VERSION ""

NS_ :

BS_:

BU_: ARM APIM_CDC APIM_CISM APIM ESPM DSP APIM_CIM FCIMB RACM_RCIM HUD_ADV WCM TRM_ITRM ACM GWM _delete IPC GENERIC TSTR

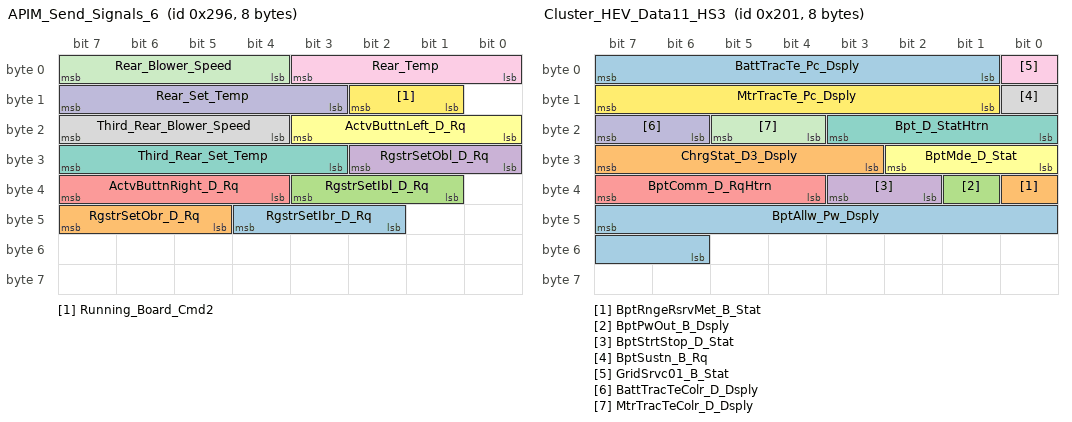
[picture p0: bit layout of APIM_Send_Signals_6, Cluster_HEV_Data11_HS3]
BO_ 662 APIM_Send_Signals_6: 8 APIM_CIM
 SG_ RgstrSetIbr_D_Rq : 44|3@0+ (1,0) [0|7] "SED"  GWM
 SG_ RgstrSetObr_D_Rq : 47|3@0+ (1,0) [0|7] "SED"  GWM
 SG_ RgstrSetIbl_D_Rq : 35|3@0+ (1,0) [0|7] "SED"  GWM
 SG_ RgstrSetObl_D_Rq : 26|3@0+ (1,0) [0|7] "SED"  GWM
 SG_ ActvButtnRight_D_Rq : 39|4@0+ (1,0) [0|15] "SED"  GWM
 SG_ ActvButtnLeft_D_Rq : 19|4@0+ (1,0) [0|15] "SED"  GWM
 SG_ Third_Rear_Set_Temp : 31|5@0+ (1,0) [0|31] "SED"  GWM
 SG_ Third_Rear_Blower_Speed : 23|4@0+ (1,0) [0|15] "SED"  GWM
 SG_ Rear_Temp : 3|4@0+ (1,0) [0|15] "SED"  GWM
 SG_ Rear_Set_Temp : 15|5@0+ (1,0) [0|31] "SED"  GWM
 SG_ Rear_Blower_Speed : 7|4@0+ (1,0) [0|15] "SED"  GWM
 SG_ Running_Board_Cmd2 : 10|2@0+ (1,0) [0|3] "SED"  GWM

BO_ 515 PowertrainData_12_HS3: 8 GWM
 SG_ FuelLvlPss_Pc_DsplyEng : 9|10@0+ (0.108696,-5.217408) [-5.217408|105.9786] "percent"  APIM,APIM_CDC,APIM_CIM,APIM_CISM,IPC
 SG_ FuelLvlAct_Pc_DsplyEng : 5|10@0+ (0.108696,-5.217408) [-5.217408|105.9786] "percent"  APIM,APIM_CDC,APIM_CIM,APIM_CISM,IPC
 SG_ PtIgnSwtch_D_Stat : 7|2@0+ (1,0) [0|3] "SED" Vector__XXX

BO_ 513 Cluster_HEV_Data11_HS3: 8 GWM
 SG_ BptAllw_Pw_Dsply : 47|10@0+ (0.1,0) [0|102.1] "kilowatt"  APIM_CDC,APIM,APIM_CIM,APIM_CISM
 SG_ BptRngeRsrvMet_B_Stat : 32|1@0+ (1,0) [0|1] "SED"  APIM_CDC,APIM,APIM_CIM,APIM_CISM
 SG_ BptPwOut_B_Dsply : 33|1@0+ (1,0) [0|1] "SED"  APIM_CDC,APIM,APIM_CIM,APIM_CISM
 SG_ BptStrtStop_D_Stat : 35|2@0+ (1,0) [0|3] "SED"  APIM_CDC,APIM,APIM_CIM,APIM_CISM
 SG_ BptComm_D_RqHtrn : 39|4@0+ (1,0) [0|15] "SED"  APIM_CDC,APIM,APIM_CIM,APIM_CISM
 SG_ BptMde_D_Stat : 26|3@0+ (1,0) [0|7] "SED"  APIM_CDC,APIM,APIM_CIM,APIM_CISM
 SG_ Bpt_D_StatHtrn : 19|4@0+ (1,0) [0|15] "SED"  APIM,APIM_CIM,APIM_CISM
 SG_ BptSustn_B_Rq : 8|1@0+ (1,0) [0|1] "SED"  APIM,APIM_CIM,APIM_CISM
 SG_ GridSrvc01_B_Stat : 0|1@0+ (1,0) [0|1] "SED"  APIM_CDC,APIM,APIM_CIM,APIM_CISM
 SG_ BattTracTeColr_D_Dsply : 23|2@0+ (1,0) [0|3] "SED"  APIM_CDC,APIM_CIM,IPC
 SG_ MtrTracTeColr_D_Dsply : 21|2@0+ (1,0) [0|3] "SED"  APIM_CDC,APIM_CIM,IPC
 SG_ MtrTracTe_Pc_Dsply : 15|7@0+ (1,0) [0|127] "percent"  APIM_CDC,APIM_CIM,IPC
 SG_ BattTracTe_Pc_Dsply : 7|7@0+ (1,0) [0|127] "percent"  APIM_CDC,APIM_CIM,IPC
 SG_ ChrgStat_D3_Dsply : 31|5@0+ (1,0) [0|31] "SED"  APIM_CDC,APIM,APIM_CIM,IPC,APIM_CISM

BO_ 148 Yaw_Data_HS3: 8 GWM
 SG_ VehYawWActl_D_Qf : 53|2@0+ (1,0) [0|3] "SED" Vector__XXX
 SG_ VehRolWActl_D_Qf : 55|2@0+ (1,0) [0|3] "SED" Vector__XXX
 SG_ VehRollYawW_No_Cs : 39|8@0+ (1,0) [0|255] "unitless" Vector__XXX
 SG_ VehRollYaw_No_Cnt : 47|8@0+ (1,0) [0|255] "unitless" Vector__XXX
 SG_ VehYaw_W_Actl : 23|16@0+ (0.0002,-6.5) [-6.5|6.6066] "rad/s"  APIM_CDC,APIM,APIM_CISM,ACM,APIM_CIM
 SG_ VehRol_W_Actl : 7|16@0+ (0.0002,-6.5) [-6.5|6.6066] "rad/s" Vector__XXX

BO_ 1042 TrailerBrakeData_HS3: 8 GWM
 SG_ VehRol_An_Dsply : 31|7@0+ (1,-64) [-64|61] "degrees"  APIM_CDC,HUD_ADV,APIM,APIM_CIM,APIM_CISM,IPC
 SG_ RearDiffLck_Tq_RqMn : 39|12@0+ (4,0) [0|16376] "Nm" Vector__XXX
 SG_ VehPtch_An_Dsply : 23|7@0+ (1,-64) [-64|61] "degrees"  APIM_CDC,HUD_ADV,APIM,APIM_CIM,APIM_CISM,IPC
 SG_ TrlrBrk_Pc_Rq : 14|7@0+ (1,0) [0|127] "percent"  TRM_ITRM,IPC

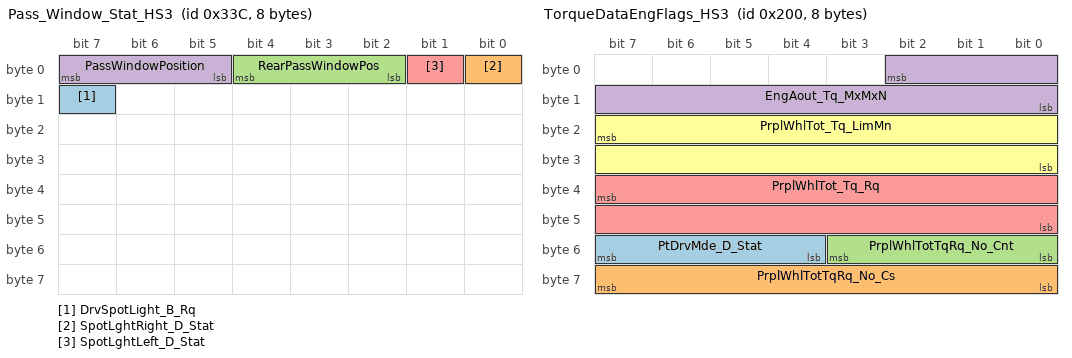
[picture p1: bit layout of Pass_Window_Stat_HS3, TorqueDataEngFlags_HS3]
BO_ 828 Pass_Window_Stat_HS3: 8 GWM
 SG_ DrvSpotLight_B_Rq : 15|1@0+ (1,0) [0|1] "SED" Vector__XXX
 SG_ SpotLghtRight_D_Stat : 0|1@0+ (1,0) [0|1] "SED"  APIM_CDC,APIM,APIM_CISM,APIM_CIM
 SG_ RearPassWindowPos : 4|3@0+ (1,0) [0|7] "SED"  APIM_CDC,APIM,APIM_CISM,ACM,APIM_CIM,WCM
 SG_ PassWindowPosition : 7|3@0+ (1,0) [0|7] "SED"  APIM_CDC,APIM,APIM_CISM,ACM,APIM_CIM,WCM
 SG_ SpotLghtLeft_D_Stat : 1|1@0+ (1,0) [0|1] "SED"  APIM_CDC,APIM,APIM_CISM,APIM_CIM

BO_ 330 TransData_3_HS3: 8 GWM
 SG_ TrnFaltOpenClu_B_Stat : 5|1@0+ (1,0) [0|1] "SED" Vector__XXX
 SG_ TrnAout_W_ActlUnfilt : 22|15@0+ (0.1,0) [0|3276.5] "rad/s"  APIM_CISM,ACM,APIM_CIM

BO_ 512 TorqueDataEngFlags_HS3: 8 GWM
 SG_ PtDrvMde_D_Stat : 55|4@0+ (1,0) [0|15] "SED"  APIM_CDC,APIM_CISM,ACM,APIM_CIM,IPC
 SG_ PrplWhlTotTqRq_No_Cs : 63|8@0+ (1,0) [0|255] "unitless" Vector__XXX
 SG_ PrplWhlTotTqRq_No_Cnt : 51|4@0+ (1,0) [0|15] "unitless" Vector__XXX
 SG_ EngAout_Tq_MxMxN : 2|11@0+ (1,-500) [-500|1547] "Nm" Vector__XXX
 SG_ PrplWhlTot_Tq_Rq : 39|16@0+ (4,-131072) [-131072|131068] "Nm" Vector__XXX
 SG_ PrplWhlTot_Tq_LimMn : 23|16@0+ (4,-131072) [-131072|131068] "Nm" Vector__XXX

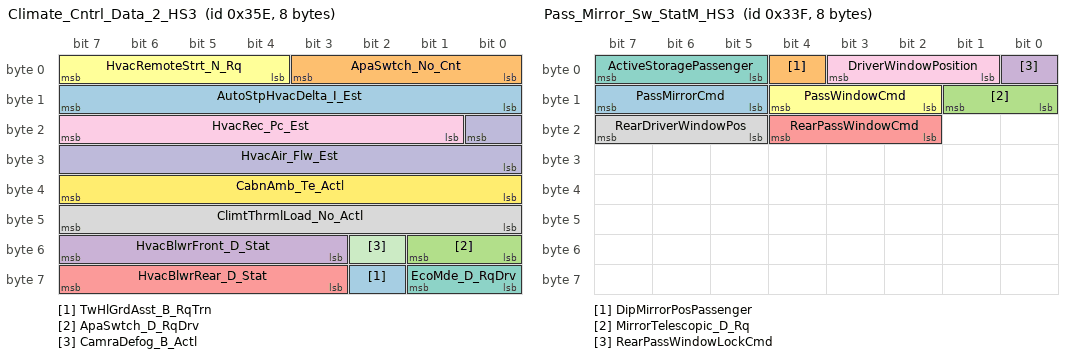
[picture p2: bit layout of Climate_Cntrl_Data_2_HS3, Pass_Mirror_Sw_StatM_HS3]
BO_ 862 Climate_Cntrl_Data_2_HS3: 8 GWM
 SG_ TwHlGrdAsst_B_RqTrn : 58|1@0+ (1,0) [0|1] "SED" Vector__XXX
 SG_ ApaSwtch_No_Cnt : 3|4@0+ (1,0) [0|15] "unitless" Vector__XXX
 SG_ ApaSwtch_D_RqDrv : 49|2@0+ (1,0) [0|3] "SED" Vector__XXX
 SG_ HvacBlwrFront_D_Stat : 55|5@0+ (1,0) [0|31] "SED"  APIM,APIM_CISM,APIM_CIM,WCM
 SG_ HvacBlwrRear_D_Stat : 63|5@0+ (1,0) [0|31] "SED"  APIM,APIM_CISM,APIM_CIM,WCM
 SG_ HvacRemoteStrt_N_Rq : 7|4@0+ (100,450) [450|1950] "RPM" Vector__XXX
 SG_ EcoMde_D_RqDrv : 57|2@0+ (1,0) [0|3] "SED" Vector__XXX
 SG_ ClimtThrmlLoad_No_Actl : 47|8@0+ (1,0) [0|254] "unitless" Vector__XXX
 SG_ HvacRec_Pc_Est : 23|7@0+ (1,0) [0|127] "percent" Vector__XXX
 SG_ HvacAir_Flw_Est : 16|9@0+ (0.5,0) [0|255.5] "liter/second" Vector__XXX
 SG_ CamraDefog_B_Actl : 50|1@0+ (1,0) [0|1] "SED" Vector__XXX
 SG_ CabnAmb_Te_Actl : 39|8@0+ (0.5,-57) [-57|70] "degC"  APIM_CDC,APIM,APIM_CISM,GWM,ACM,APIM_CIM,WCM
 SG_ AutoStpHvacDelta_I_Est : 15|8@0+ (1,-192) [-192|62] "ampere" Vector__XXX

BO_ 831 Pass_Mirror_Sw_StatM_HS3: 8 GWM
 SG_ PassMirrorCmd : 15|3@0+ (1,0) [0|7] "SED" Vector__XXX
 SG_ DipMirrorPosPassenger : 4|1@0+ (1,0) [0|1] "SED" Vector__XXX
 SG_ MirrorTelescopic_D_Rq : 9|2@0+ (1,0) [0|3] "SED" Vector__XXX
 SG_ RearPassWindowLockCmd : 0|1@0+ (1,0) [0|1] "SED" Vector__XXX
 SG_ RearPassWindowCmd : 20|3@0+ (1,0) [0|7] "SED" Vector__XXX
 SG_ PassWindowCmd : 12|3@0+ (1,0) [0|7] "SED" Vector__XXX
 SG_ ActiveStoragePassenger : 7|3@0+ (1,0) [0|7] "SED" Vector__XXX
 SG_ RearDriverWindowPos : 23|3@0+ (1,0) [0|7] "SED"  APIM_CDC,APIM,APIM_CISM,ACM,APIM_CIM,WCM
 SG_ DriverWindowPosition : 3|3@0+ (1,0) [0|7] "SED"  APIM_CDC,APIM,APIM_CISM,ACM,APIM_CIM,WCM

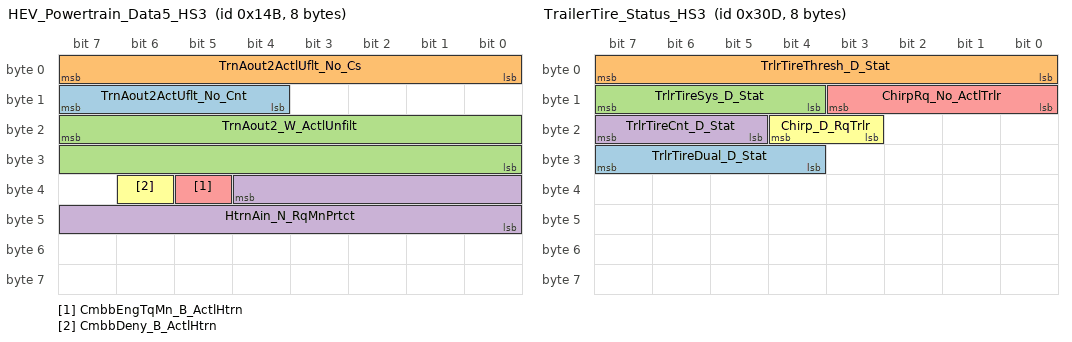
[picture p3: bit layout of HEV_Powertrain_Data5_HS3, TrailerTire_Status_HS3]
BO_ 331 HEV_Powertrain_Data5_HS3: 8 GWM
 SG_ TrnAout2ActUflt_No_Cnt : 15|4@0+ (1,0) [0|15] "unitless" Vector__XXX
 SG_ TrnAout2ActlUflt_No_Cs : 7|8@0+ (1,0) [0|255] "unitless" Vector__XXX
 SG_ TrnAout2_W_ActlUnfilt : 23|16@0+ (0.1,-3276.5) [-3276.5|3276.8] "rad/s"  APIM_CDC,APIM_CISM,ACM,APIM_CIM
 SG_ HtrnAin_N_RqMnPrtct : 36|13@0+ (2,0) [0|16382] "RPM" Vector__XXX
 SG_ CmbbEngTqMn_B_ActlHtrn : 37|1@0+ (1,0) [0|1] "SED" Vector__XXX
 SG_ CmbbDeny_B_ActlHtrn : 38|1@0+ (1,0) [0|1] "SED" Vector__XXX

BO_ 965 FrontTrunk_Data_HS3: 8 GWM
 SG_ TrnkFrontPrim_B_Falt : 18|1@0+ (1,0) [0|1] "SED"  APIM_CDC,APIM_CIM,IPC
 SG_ TrnkFrontEmgcy_D_Stat : 20|2@0+ (1,0) [0|0] "SED"  APIM_CDC,APIM_CIM,IPC
 SG_ PtWakeupActv4_B_Rq : 21|1@0+ (1,0) [0|1] "SED" Vector__XXX
 SG_ TrunkFrontOpen_D_Stat : 23|2@0+ (1,0) [0|3] "SED"  APIM_CDC,APIM,APIM_CISM,APIM_CIM
 SG_ TrunkFrontRolCd_No_Locl : 7|16@0+ (1,0) [0|65535] "unitless" Vector__XXX

BO_ 1242 PowertrainCstmData_HS3: 8 GWM
 SG_ EngExhMdeQuietCstm_D_Rq : 7|3@0+ (1,0) [0|7] "SED"  IPC
 SG_ StopStrtCstm_D_Rq : 15|2@0+ (1,0) [0|3] "SED"  IPC
 SG_ SelDrvMdeCstmPt_D_Rq : 4|5@0+ (1,0) [0|31] "SED" Vector__XXX

BO_ 1245 DrivelineCstmFeatures_HS3: 8 GWM
 SG_ RearDiffLckLamp_D_Cstm : 13|2@0+ (1,0) [0|3] "SED"  IPC
 SG_ FrontDiffLckLamp_D_Cstm : 15|2@0+ (1,0) [0|3] "SED"  IPC
 SG_ AwdMdeCstm_D_RqDrv : 7|3@0+ (1,0) [0|7] "SED"  IPC
 SG_ SelDrvMdeAwd2_D_Cstm : 4|5@0+ (1,0) [0|31] "SED" Vector__XXX

BO_ 781 TrailerTire_Status_HS3: 8 GWM
 SG_ TrlrTireDual_D_Stat : 31|4@0+ (1,0) [0|15] "SED"  APIM_CDC,APIM,APIM_CIM,APIM_CISM,IPC
 SG_ TrlrTireThresh_D_Stat : 7|8@0+ (1,0) [0|255] "unitless"  APIM_CDC,APIM,APIM_CISM,APIM_CIM,IPC
 SG_ TrlrTireSys_D_Stat : 15|4@0+ (1,0) [0|15] "SED"  APIM_CDC,APIM,APIM_CISM,APIM_CIM,IPC
 SG_ TrlrTireCnt_D_Stat : 23|3@0+ (1,0) [0|6] "SED"  APIM_CDC,APIM,APIM_CISM,APIM_CIM,IPC
 SG_ ChirpRq_No_ActlTrlr : 11|4@0+ (1,0) [0|15] "unitless"  APIM_CISM,APIM_CIM,IPC
 SG_ Chirp_D_RqTrlr : 20|2@0+ (1,0) [0|3] "SED"  APIM_CISM,APIM_CIM,IPC

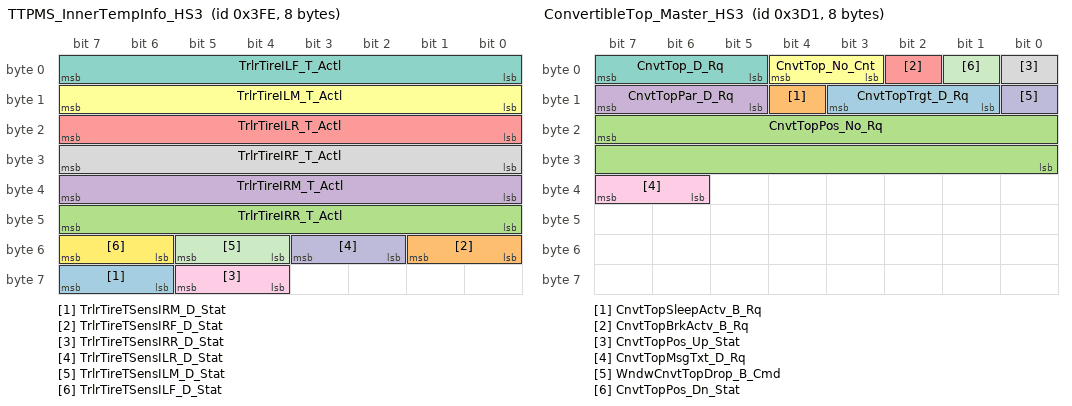
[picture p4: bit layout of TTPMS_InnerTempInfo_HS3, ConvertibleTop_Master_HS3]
BO_ 1022 TTPMS_InnerTempInfo_HS3: 8 GWM
 SG_ TrlrTireTSensIRM_D_Stat : 63|2@0+ (1,0) [0|3] "SED"  APIM_CDC,APIM,APIM_CISM,APIM_CIM,IPC
 SG_ TrlrTireTSensIRF_D_Stat : 49|2@0+ (1,0) [0|3] "SED"  APIM_CDC,APIM,APIM_CISM,APIM_CIM,IPC
 SG_ TrlrTireIRR_T_Actl : 47|8@0+ (1,-60) [-60|193] "degC"  APIM_CDC,APIM,APIM_CISM,APIM_CIM,IPC
 SG_ TrlrTireIRM_T_Actl : 39|8@0+ (1,-60) [-60|193] "degC"  APIM_CDC,APIM,APIM_CISM,APIM_CIM,IPC
 SG_ TrlrTireILR_T_Actl : 23|8@0+ (1,-60) [-60|193] "degC"  APIM_CDC,APIM,APIM_CISM,APIM_CIM,IPC
 SG_ TrlrTireILM_T_Actl : 15|8@0+ (1,-60) [-60|193] "degC"  APIM_CDC,APIM,APIM_CISM,APIM_CIM,IPC
 SG_ TrlrTireILF_T_Actl : 7|8@0+ (1,-60) [-60|193] "degC"  APIM_CDC,APIM,APIM_CISM,APIM_CIM,IPC
 SG_ TrlrTireIRF_T_Actl : 31|8@0+ (1,-60) [-60|193] "degC"  APIM_CDC,APIM,APIM_CISM,APIM_CIM,IPC
 SG_ TrlrTireTSensIRR_D_Stat : 61|2@0+ (1,0) [0|3] "SED"  APIM_CDC,APIM,APIM_CISM,APIM_CIM,IPC
 SG_ TrlrTireTSensILR_D_Stat : 51|2@0+ (1,0) [0|3] "SED"  APIM_CDC,APIM,APIM_CISM,APIM_CIM,IPC
 SG_ TrlrTireTSensILM_D_Stat : 53|2@0+ (1,0) [0|3] "SED"  APIM_CDC,APIM,APIM_CISM,APIM_CIM,IPC
 SG_ TrlrTireTSensILF_D_Stat : 55|2@0+ (1,0) [0|3] "SED"  APIM_CDC,APIM,APIM_CISM,APIM_CIM,IPC

BO_ 903 Av_RDAPM_Data2_HS3: 8 GWM
 SG_ AprSnd_D_Rq : 7|6@0+ (1,0) [0|63] "SED"  APIM_CDC,APIM,APIM_CISM,APIM_CIM

BO_ 901 Av_LDAPM_Data2_HS3: 8 GWM
 SG_ AplSnd_D_Rq : 7|6@0+ (1,0) [0|63] "SED"  APIM_CDC,APIM,APIM_CISM,APIM_CIM

BO_ 1112 Battery_Traction_6_HS3: 8 GWM
 SG_ BattTracIsoDis_B_Stat : 0|1@0+ (1,0) [0|1] "SED" Vector__XXX
 SG_ BattTrac2_E_Max : 47|12@0+ (50,0) [0|204650] "watt*hour"  APIM_CDC,APIM,APIM_CISM,APIM_CIM
 SG_ BattTracHeat_D_Rq : 35|2@0+ (1,0) [0|3] "SED" Vector__XXX
 SG_ BattTracDcFstSustn_B_Rq : 51|1@0+ (1,0) [0|1] "SED" Vector__XXX
 SG_ BattDcCnnct_D_Cmd : 14|3@0+ (1,0) [0|7] "SED" Vector__XXX
 SG_ BattTrac2_E_Avail : 31|12@0+ (50,0) [0|204650] "watt*hour"  APIM_CDC,APIM,APIM_CISM,APIM_CIM
 SG_ BattTracCnnct_D_Cmd : 18|3@0+ (1,0) [0|7] "SED" Vector__XXX
 SG_ BattTracHvilOpen_B_Stat : 8|1@0+ (1,0) [0|1] "SED" Vector__XXX
 SG_ BattTracCoolLvl_D_Rq : 11|3@0+ (1,0) [0|7] "SED" Vector__XXX
 SG_ CoolFanBatt_D_Rq : 23|5@0+ (1,0) [0|31] "unitless" Vector__XXX
 SG_ BattTracTeSustn_B_Rq : 1|1@0+ (1,0) [0|1] "SED" Vector__XXX
 SG_ BattTracTeEvnt_B_Stat : 2|1@0+ (1,0) [0|1] "SED" Vector__XXX
 SG_ BattTracDcdcDis_B_Rq : 7|1@0+ (1,0) [0|1] "SED" Vector__XXX
 SG_ BattChrgTrgtEvnt_B_Stat : 3|1@0+ (1,0) [0|1] "SED" Vector__XXX
 SG_ BattTracDiagClr_B_Rq : 15|1@0+ (1,0) [0|1] "SED" Vector__XXX
 SG_ BattTracChrgSustn_B_Rq : 4|1@0+ (1,0) [0|1] "SED" Vector__XXX
 SG_ HtrnClntPump_D_Stat : 6|2@0+ (1,0) [0|3] "SED" Vector__XXX
 SG_ BattTracDelta_Te_Actl : 63|8@0+ (0.5,-60) [-60|66.5] "degC" Vector__XXX
 SG_ BattTracClntPmp_D_Stat : 33|2@0+ (1,0) [0|3] "SED" Vector__XXX
 SG_ BattTracHazrd_D_Stat : 50|3@0+ (1,0) [0|7] "SED"  APIM_CDC,APIM_CIM,IPC

BO_ 977 ConvertibleTop_Master_HS3: 8 GWM
 SG_ CnvtTopTrgt_D_Rq : 11|3@0+ (1,0) [0|7] "SED" Vector__XXX
 SG_ CnvtTopSleepActv_B_Rq : 12|1@0+ (1,0) [0|1] "SED" Vector__XXX
 SG_ CnvtTopPos_No_Rq : 23|16@0+ (1,0) [0|65535] "unitless" Vector__XXX
 SG_ CnvtTopPar_D_Rq : 15|3@0+ (1,0) [0|7] "SED" Vector__XXX
 SG_ CnvtTopBrkActv_B_Rq : 2|1@0+ (1,0) [0|1] "SED" Vector__XXX
 SG_ CnvtTop_No_Cnt : 4|2@0+ (1,0) [0|3] "unitless" Vector__XXX
 SG_ CnvtTop_D_Rq : 7|3@0+ (1,0) [0|7] "SED" Vector__XXX
 SG_ CnvtTopPos_Up_Stat : 0|1@0+ (1,0) [0|1] "SED"  APIM_CDC,APIM_CISM,APIM_CIM,ACM,DSP
 SG_ CnvtTopMsgTxt_D_Rq : 39|2@0+ (1,0) [0|3] "SED"  APIM_CDC,APIM_CIM,IPC
 SG_ WndwCnvtTopDrop_B_Cmd : 8|1@0+ (1,0) [0|1] "SED" Vector__XXX
 SG_ CnvtTopPos_Dn_Stat : 1|1@0+ (1,0) [0|1] "SED"  APIM_CDC,APIM_CISM,APIM_CIM,ACM

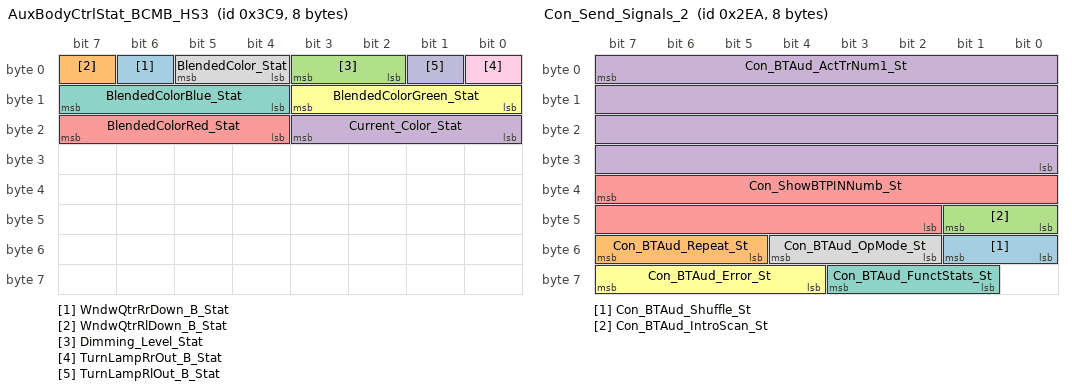
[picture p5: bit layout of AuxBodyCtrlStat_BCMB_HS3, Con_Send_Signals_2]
BO_ 969 AuxBodyCtrlStat_BCMB_HS3: 8 GWM
 SG_ WndwQtrRrDown_B_Stat : 6|1@0+ (1,0) [0|1] "SED" Vector__XXX
 SG_ WndwQtrRlDown_B_Stat : 7|1@0+ (1,0) [0|1] "SED" Vector__XXX
 SG_ Dimming_Level_Stat : 3|2@0+ (1,0) [0|3] "SED"  APIM_CDC,APIM_CIM
 SG_ Current_Color_Stat : 19|4@0+ (1,0) [0|15] "SED"  APIM_CDC,APIM_CIM
 SG_ BlendedColorRed_Stat : 23|4@0+ (1,0) [0|15] "SED"  APIM_CDC,APIM_CIM
 SG_ BlendedColorGreen_Stat : 11|4@0+ (1,0) [0|15] "SED"  APIM_CDC,APIM_CIM
 SG_ BlendedColorBlue_Stat : 15|4@0+ (1,0) [0|15] "SED"  APIM_CDC,APIM_CIM
 SG_ BlendedColor_Stat : 5|2@0+ (1,0) [0|3] "SED"  APIM_CDC,APIM_CIM
 SG_ TurnLampRrOut_B_Stat : 0|1@0+ (1,0) [0|1] "SED" Vector__XXX
 SG_ TurnLampRlOut_B_Stat : 1|1@0+ (1,0) [0|1] "SED" Vector__XXX

BO_ 530 APIM_Request_Signals_6: 8 APIM
 SG_ PiCode_No_Rq : 39|16@0+ (1,0) [0|65535] "unitless"  ACM
 SG_ StationTypeSel_D_Rq : 61|2@0+ (1,0) [0|3] "SED"  ACM
 SG_ DabExtndCntryCode_No_Rq : 55|8@0+ (1,0) [0|255] "unitless"  ACM
 SG_ DabStationCodeId_No_Rq : 23|16@0+ (1,0) [0|65535] "unitless"  ACM
 SG_ DabStationId_No_Rq : 7|16@0+ (1,0) [0|65535] "unitless"  ACM

BO_ 746 Con_Send_Signals_2: 8 ACM
 SG_ Con_BTAud_Shuffle_St : 49|2@0+ (1,0) [0|3] "SED"  IPC
 SG_ Con_BTAud_Repeat_St : 55|3@0+ (1,0) [0|7] "SED"  IPC
 SG_ Con_BTAud_IntroScan_St : 41|2@0+ (1,0) [0|3] "SED"  IPC
 SG_ Con_BTAud_ActTrNum1_St : 7|32@0+ (1,0) [0|4294967295] "unitless"  IPC
 SG_ Con_ShowBTPINNumb_St : 39|14@0+ (1,0) [0|16383] "unitless"  IPC
 SG_ Con_BTAud_Error_St : 63|4@0+ (1,0) [0|15] "SED"  IPC
 SG_ Con_BTAud_FunctStats_St : 59|3@0+ (1,0) [0|7] "SED"  IPC
 SG_ Con_BTAud_OpMode_St : 52|3@0+ (1,0) [0|7] "SED"  IPC

BO_ 479 DISP_Request_Sig: 8 APIM_CIM
 SG_ DISP_SetVolume_Rq : 5|6@0+ (1,-30) [-30|33] "steps"  DSP,ACM,GWM
 SG_ DISP_SetVol_Source_Rq : 19|4@0+ (1,0) [0|15] "SED"  IPC,DSP,ACM,GWM
 SG_ DISP_SetVol_Level_Rq : 13|6@0+ (1,0) [0|63] "unitless"  DSP,GWM,ACM
 SG_ DISP_Setshaker_Rq : 21|2@0+ (1,0) [0|3] "SED"  DSP,GWM,ACM

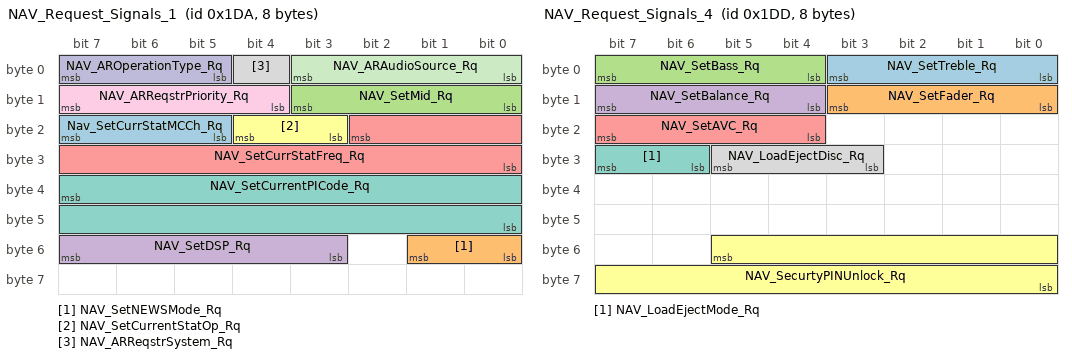
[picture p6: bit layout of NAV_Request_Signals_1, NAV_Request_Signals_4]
BO_ 474 NAV_Request_Signals_1: 8 APIM
 SG_ Nav_SetCurrStatMCCh_Rq : 23|3@0+ (1,0) [0|7] "SED"  ACM
 SG_ NAV_SetNEWSMode_Rq : 49|2@0+ (1,0) [0|3] "SED"  ACM
 SG_ NAV_SetMid_Rq : 11|4@0+ (1,-7) [-7|8] "SED"  DSP,ACM
 SG_ NAV_SetDSP_Rq : 55|5@0+ (1,0) [0|31] "SED"  DSP,ACM
 SG_ NAV_SetCurrStatFreq_Rq : 18|11@0+ (1,0) [0|1557] "unitless"  ACM
 SG_ NAV_SetCurrentStatOp_Rq : 20|2@0+ (1,0) [0|3] "SED"  ACM
 SG_ NAV_SetCurrentPICode_Rq : 39|16@0+ (1,0) [0|65535] "unitless"  ACM
 SG_ NAV_ARReqstrSystem_Rq : 4|1@0+ (1,0) [0|1] "SED"  DSP,ACM
 SG_ NAV_ARReqstrPriority_Rq : 15|4@0+ (1,0) [0|15] "SED"  DSP,ACM
 SG_ NAV_AROperationType_Rq : 7|3@0+ (1,0) [0|7] "SED"  DSP,ACM
 SG_ NAV_ARAudioSource_Rq : 3|4@0+ (1,0) [0|15] "SED"  DSP,ACM

BO_ 477 NAV_Request_Signals_4: 8 APIM
 SG_ NAV_SetTreble_Rq : 3|4@0+ (1,-7) [-7|8] "SED"  ACM,DSP
 SG_ NAV_SetFader_Rq : 11|4@0+ (1,-7) [-7|8] "SED"  ACM,DSP
 SG_ NAV_SetBass_Rq : 7|4@0+ (1,-7) [-7|8] "SED"  ACM,DSP
 SG_ NAV_SetBalance_Rq : 15|4@0+ (1,-7) [-7|8] "SED"  ACM,DSP
 SG_ NAV_SetAVC_Rq : 23|4@0+ (1,0) [0|15] "SED"  ACM,DSP
 SG_ NAV_SecurtyPINUnlock_Rq : 53|14@0+ (1,0) [0|16383] "unitless"  ACM
 SG_ NAV_LoadEjectMode_Rq : 31|2@0+ (1,0) [0|3] "SED"  ACM
 SG_ NAV_LoadEjectDisc_Rq : 29|3@0+ (1,0) [0|7] "SED"  ACM

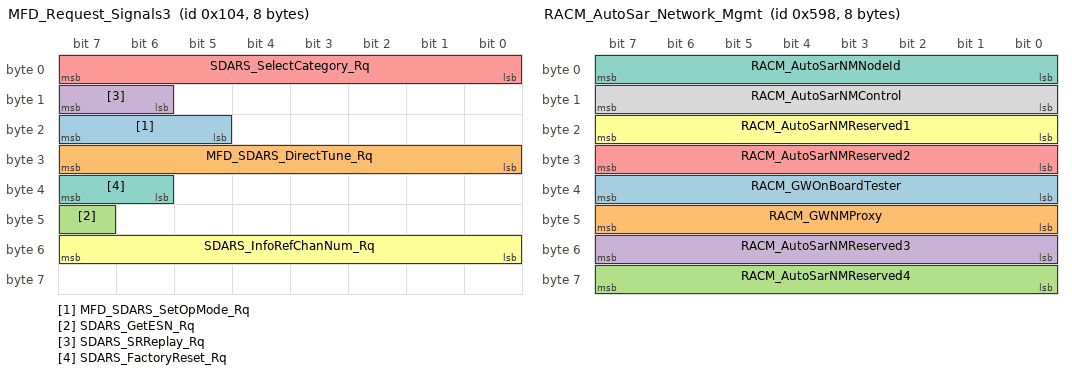
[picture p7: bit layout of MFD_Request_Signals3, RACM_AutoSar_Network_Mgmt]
BO_ 260 MFD_Request_Signals3: 8 APIM
 SG_ MFD_SDARS_SetOpMode_Rq : 23|3@0+ (1,0) [0|7] "SED"  ACM
 SG_ MFD_SDARS_DirectTune_Rq : 31|8@0+ (1,0) [0|255] "unitless"  ACM
 SG_ SDARS_GetESN_Rq : 47|1@0+ (1,0) [0|1] "SED"  ACM
 SG_ SDARS_SRReplay_Rq : 15|2@0+ (1,0) [0|3] "SED"  ACM
 SG_ SDARS_SelectCategory_Rq : 7|8@0+ (1,0) [0|255] "unitless"  ACM
 SG_ SDARS_InfoRefChanNum_Rq : 55|8@0+ (1,0) [0|255] "unitless"  ACM
 SG_ SDARS_FactoryReset_Rq : 39|2@0+ (1,0) [0|3] "SED"  DSP,ACM

BO_ 476 NAV_Request_Signals_3: 8 APIM
 SG_ Nav_SetAudioMixRatio_Rq : 31|5@0+ (1,0) [0|20] "decibel"  ACM
 SG_ NAV_SkipCatalouge_Rq : 7|2@0+ (1,0) [0|3] "SED"  ACM
 SG_ NAV_SetOperationMode_Rq : 26|3@0+ (1,0) [0|7] "SED"  ACM
 SG_ NAV_SetDSPProgram_Rq : 13|3@0+ (1,0) [0|7] "SED"  ACM

BO_ 490 HMI_Request_Signals_2: 8 APIM
 SG_ HMI_SetCompression_Rq : 9|2@0+ (1,0) [0|3] "SED"  APIM_CDC,ACM
 SG_ HMI_SkipTrack_Rq : 35|2@0+ (1,0) [0|3] "SED"  ACM

BO_ 1916 TesterPhysicalResRACM: 8 RACM_RCIM
 SG_ TesterPhysicalResRACM : 7|64@0+ (1,0) [0|1.84467E+019] "unitless"  TSTR

BO_ 1908 TesterPhysicalReqRACM: 8 TSTR
 SG_ TesterPhysicalReqRACM : 7|64@0+ (1,0) [0|1.84467E+019] "unitless"  RACM_RCIM

BO_ 1432 RACM_AutoSar_Network_Mgmt: 8 RACM_RCIM
 SG_ RACM_GWOnBoardTester : 39|8@0+ (1,0) [0|255] "unitless"  GENERIC,GWM
 SG_ RACM_GWNMProxy : 47|8@0+ (1,0) [0|255] "unitless"  GENERIC,GWM
 SG_ RACM_AutoSarNMReserved4 : 63|8@0+ (1,0) [0|255] "unitless"  GENERIC,GWM
 SG_ RACM_AutoSarNMReserved3 : 55|8@0+ (1,0) [0|255] "unitless"  GENERIC,GWM
 SG_ RACM_AutoSarNMReserved2 : 31|8@0+ (1,0) [0|255] "unitless"  GENERIC,GWM
 SG_ RACM_AutoSarNMReserved1 : 23|8@0+ (1,0) [0|255] "unitless"  GENERIC,GWM
 SG_ RACM_AutoSarNMNodeId : 7|8@0+ (1,0) [0|255] "unitless"  GENERIC,GWM
 SG_ RACM_AutoSarNMControl : 15|8@0+ (1,0) [0|255] "unitless"  GENERIC,GWM

BO_ 1923 TesterPhysicalReqDSP: 8 TSTR
 SG_ TesterPhysicalReqDSP : 7|64@0+ (1,0) [0|1.84467E+019] "unitless"  DSP

BO_ 1931 TesterPhysicalResDSP: 8 DSP
 SG_ TesterPhysicalResDSP : 7|64@0+ (1,0) [0|1.84467E+019] "unitless"  TSTR

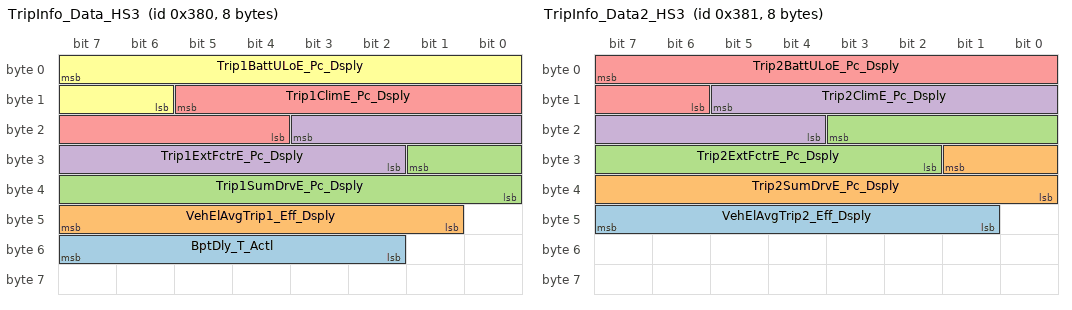
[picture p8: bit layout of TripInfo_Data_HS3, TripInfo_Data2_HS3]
BO_ 896 TripInfo_Data_HS3: 8 GWM
 SG_ BptDly_T_Actl : 55|6@0+ (0.5,0) [0|30.5] "minute"  APIM_CDC,APIM,APIM_CIM,APIM_CISM
 SG_ VehElAvgTrip1_Eff_Dsply : 47|7@0+ (10,-100) [-100|1150] "wattHr/km"  APIM_CDC,APIM,APIM_CIM,IPC,APIM_CISM
 SG_ Trip1SumDrvE_Pc_Dsply : 25|10@0+ (0.1,0) [0|102.1] "percent"  APIM_CDC,APIM,APIM_CIM,APIM_CISM
 SG_ Trip1ExtFctrE_Pc_Dsply : 19|10@0+ (0.1,0) [0|102.1] "percent"  APIM_CDC,APIM,APIM_CIM,APIM_CISM
 SG_ Trip1ClimE_Pc_Dsply : 13|10@0+ (0.1,0) [0|102.1] "percent"  APIM_CDC,APIM,APIM_CIM,APIM_CISM
 SG_ Trip1BattULoE_Pc_Dsply : 7|10@0+ (0.1,0) [0|102.1] "percent"  APIM_CDC,APIM,APIM_CIM,APIM_CISM

BO_ 897 TripInfo_Data2_HS3: 8 GWM
 SG_ VehElAvgTrip2_Eff_Dsply : 47|7@0+ (10,-100) [-100|1150] "wattHr/km"  APIM_CDC,APIM,APIM_CIM,IPC,APIM_CISM
 SG_ Trip2SumDrvE_Pc_Dsply : 25|10@0+ (0.1,0) [0|102.1] "percent"  APIM_CDC,APIM,APIM_CIM,APIM_CISM
 SG_ Trip2ExtFctrE_Pc_Dsply : 19|10@0+ (0.1,0) [0|102.1] "percent"  APIM_CDC,APIM,APIM_CIM,APIM_CISM
 SG_ Trip2ClimE_Pc_Dsply : 13|10@0+ (0.1,0) [0|102.1] "percent"  APIM_CDC,APIM,APIM_CIM,APIM_CISM
 SG_ Trip2BattULoE_Pc_Dsply : 7|10@0+ (0.1,0) [0|102.1] "percent"  APIM_CDC,APIM,APIM_CIM,APIM_CISM

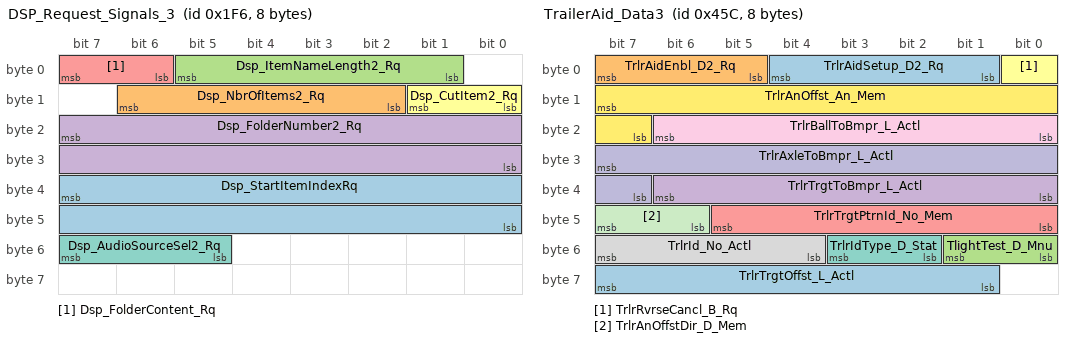
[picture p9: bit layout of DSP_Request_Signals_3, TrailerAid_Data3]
BO_ 502 DSP_Request_Signals_3: 8 APIM
 SG_ Dsp_StartItemIndexRq : 39|16@0+ (1,0) [0|65535] "unitless"  ACM
 SG_ Dsp_NbrOfItems2_Rq : 14|5@0+ (1,0) [0|20] "SED"  ACM
 SG_ Dsp_ItemNameLength2_Rq : 5|5@0+ (1,0) [0|20] "SED"  ACM
 SG_ Dsp_FolderNumber2_Rq : 23|16@0+ (1,0) [0|65535] "unitless"  ACM
 SG_ Dsp_FolderContent_Rq : 7|2@0+ (1,0) [0|3] "SED"  ACM
 SG_ Dsp_CutItem2_Rq : 9|2@0+ (1,0) [0|3] "SED"  ACM
 SG_ Dsp_AudioSourceSel2_Rq : 55|3@0+ (1,0) [0|7] "SED"  ACM

BO_ 955 Tire_Temp_Data_HS3: 8 GWM
 SG_ Tire_Temp_RF_Data : 47|8@0+ (1,-60) [-60|193] "degC"  APIM_CDC,APIM,APIM_CISM,APIM_CIM,IPC
 SG_ Tire_Temp_ORR_Data : 39|8@0+ (1,-60) [-60|193] "degC"  APIM_CDC,APIM,APIM_CISM,APIM_CIM,IPC
 SG_ Tire_Temp_OLR_Data : 31|8@0+ (1,-60) [-60|193] "degC"  APIM_CDC,APIM,APIM_CISM,APIM_CIM,IPC
 SG_ Tire_Temp_LF_Data : 23|8@0+ (1,-60) [-60|193] "degC"  APIM_CDC,APIM,APIM_CISM,APIM_CIM,IPC
 SG_ Tire_Temp_IRR_Data : 15|8@0+ (1,-60) [-60|193] "degC"  APIM_CDC,APIM,APIM_CIM,APIM_CISM,IPC
 SG_ Tire_Temp_ILR_Data : 7|8@0+ (1,-60) [-60|193] "degC"  APIM_CDC,APIM,APIM_CIM,APIM_CISM,IPC

BO_ 1116 TrailerAid_Data3: 8 APIM
 SG_ TrlrAidSetup_D2_Rq : 4|4@0+ (1,0) [0|15] "SED"  GWM
 SG_ TrlrAidEnbl_D2_Rq : 7|3@0+ (1,0) [0|7] "SED"  GWM
 SG_ TlightTest_D_Mnu : 49|2@0+ (1,0) [0|3] "SED"  GWM
 SG_ TrlrTrgtToBmpr_L_Actl : 38|7@0+ (0.0127,0) [0|1.6129] "meter"  GWM
 SG_ TrlrTrgtPtrnId_No_Mem : 45|6@0+ (1,0) [0|63] "unitless"  GWM
 SG_ TrlrRvrseCancl_B_Rq : 0|1@0+ (1,0) [0|1] "SED"  GWM
 SG_ TrlrIdType_D_Stat : 51|2@0+ (1,0) [0|3] "SED"  GWM
 SG_ TrlrId_No_Actl : 55|4@0+ (1,0) [0|15] "unitless"  GWM
 SG_ TrlrBallToBmpr_L_Actl : 22|7@0+ (0.0127,0) [0|1.6129] "meter"  GWM
 SG_ TrlrAxleToBmpr_L_Actl : 31|9@0+ (0.0254,0) [0|12.9794] "meter"  GWM
 SG_ TrlrAnOffstDir_D_Mem : 47|2@0+ (1,0) [0|3] "SED"  GWM
 SG_ TrlrAnOffst_An_Mem : 15|9@0+ (0.1,0) [0|51.1] "degrees"  GWM
 SG_ TrlrTrgtOffst_L_Actl : 63|7@0+ (0.0127,0) [0|1.6129] "meter"  GWM

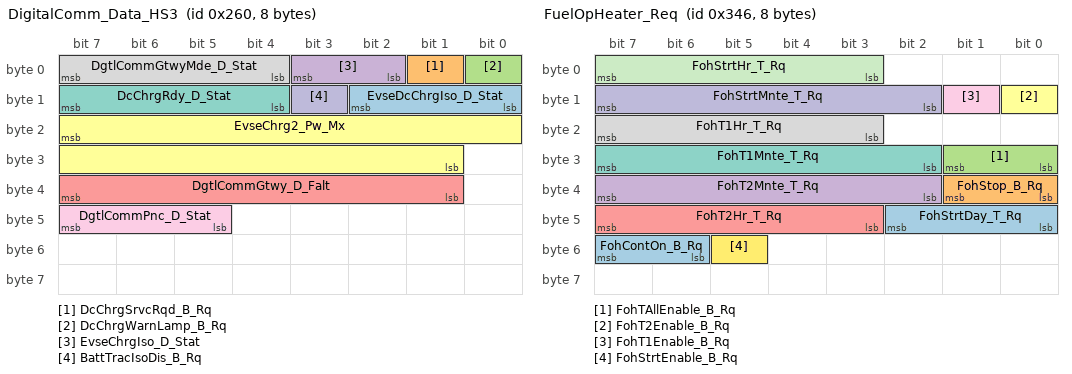
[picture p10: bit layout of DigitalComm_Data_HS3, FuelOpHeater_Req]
BO_ 608 DigitalComm_Data_HS3: 8 GWM
 SG_ EvseDcChrgIso_D_Stat : 10|3@0+ (1,0) [0|7] "SED" Vector__XXX
 SG_ DcChrgSrvcRqd_B_Rq : 1|1@0+ (1,0) [0|1] "SED"  IPC
 SG_ DcChrgWarnLamp_B_Rq : 0|1@0+ (1,0) [0|1] "SED" Vector__XXX
 SG_ EvseChrgIso_D_Stat : 3|2@0+ (1,0) [0|3] "SED" Vector__XXX
 SG_ DgtlCommGtwy_D_Falt : 39|7@0+ (1,0) [0|63] "SED" Vector__XXX
 SG_ EvseChrg2_Pw_Mx : 23|15@0+ (50,0) [0|1638250] "watts" Vector__XXX
 SG_ DcChrgRdy_D_Stat : 15|4@0+ (1,0) [0|15] "SED" Vector__XXX
 SG_ DgtlCommGtwyMde_D_Stat : 7|4@0+ (1,0) [0|15] "SED" Vector__XXX
 SG_ DgtlCommPnc_D_Stat : 47|3@0+ (1,0) [0|7] "SED" Vector__XXX
 SG_ BattTracIsoDis_B_Rq : 11|1@0+ (1,0) [0|1] "SED" Vector__XXX

BO_ 1237 Active_Park_Assist3_HS3: 8 GWM
 SG_ ApaSlotRef2Y_L_Actl : 31|11@0+ (0.02,-20.96) [-20.96|19.98] "meter"  APIM_CDC,APIM,APIM_CISM,APIM_CIM
 SG_ ApaSlotRef2X_L_Actl : 12|11@0+ (0.02,-20.96) [-20.96|19.98] "meter"  APIM_CDC,APIM,APIM_CISM,APIM_CIM
 SG_ ApaSlotRef1Y_L_Actl : 36|11@0+ (0.02,-20.96) [-20.96|19.98] "meter"  APIM_CDC,APIM,APIM_CISM,APIM_CIM
 SG_ ApaSlotRef1X_L_Actl : 7|11@0+ (0.02,-20.96) [-20.96|19.98] "meter"  APIM_CDC,APIM,APIM_CISM,APIM_CIM

BO_ 838 FuelOpHeater_Req: 8 IPC
 SG_ FohStrtDay_T_Rq : 42|3@0+ (1,0) [0|7] "SED"  GWM
 SG_ FohStop_B_Rq : 33|2@0+ (1,0) [0|3] "SED"  GWM
 SG_ FohTAllEnable_B_Rq : 25|2@0+ (1,0) [0|3] "SED"  GWM
 SG_ FohT2Mnte_T_Rq : 39|6@0+ (1,0) [0|63] "minute"  GWM
 SG_ FohT2Hr_T_Rq : 47|5@0+ (1,0) [0|31] "hour"  GWM
 SG_ FohT2Enable_B_Rq : 8|1@0+ (1,0) [0|1] "SED"  GWM
 SG_ FohT1Mnte_T_Rq : 31|6@0+ (1,0) [0|63] "minute"  GWM
 SG_ FohT1Hr_T_Rq : 23|5@0+ (1,0) [0|31] "hour"  GWM
 SG_ FohT1Enable_B_Rq : 9|1@0+ (1,0) [0|1] "SED"  GWM
 SG_ FohStrtMnte_T_Rq : 15|6@0+ (1,0) [0|63] "minute"  GWM
 SG_ FohStrtHr_T_Rq : 7|5@0+ (1,0) [0|31] "hour"  GWM
 SG_ FohStrtEnable_B_Rq : 53|1@0+ (1,0) [0|1] "SED"  GWM
 SG_ FohContOn_B_Rq : 55|2@0+ (1,0) [0|3] "SED"  GWM

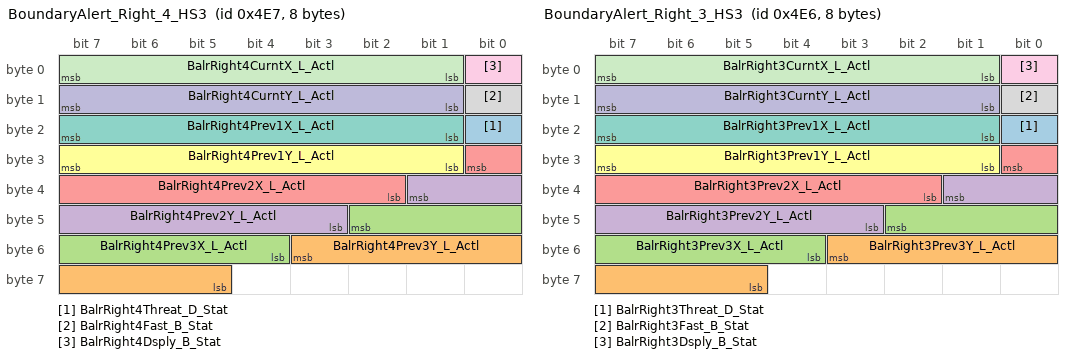
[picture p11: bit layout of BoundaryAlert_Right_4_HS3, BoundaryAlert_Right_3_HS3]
BO_ 1255 BoundaryAlert_Right_4_HS3: 8 GWM
 SG_ BalrRight4Threat_D_Stat : 16|1@0+ (1,0) [0|1] "SED"  APIM_CDC,IPC,APIM_CIM
 SG_ BalrRight4Prev3Y_L_Actl : 51|7@0+ (0.5,-32) [-32|31.5] "meter"  APIM_CDC,IPC,APIM_CIM
 SG_ BalrRight4Prev3X_L_Actl : 42|7@0+ (0.5,-32) [-32|31.5] "meter"  APIM_CDC,IPC,APIM_CIM
 SG_ BalrRight4Prev2Y_L_Actl : 33|7@0+ (0.5,-32) [-32|31.5] "meter"  APIM_CDC,IPC,APIM_CIM
 SG_ BalrRight4Prev2X_L_Actl : 24|7@0+ (0.5,-32) [-32|31.5] "meter"  APIM_CDC,IPC,APIM_CIM
 SG_ BalrRight4Prev1Y_L_Actl : 31|7@0+ (0.5,-32) [-32|31.5] "meter"  APIM_CDC,IPC,APIM_CIM
 SG_ BalrRight4Prev1X_L_Actl : 23|7@0+ (0.5,-32) [-32|31.5] "meter"  APIM_CDC,IPC,APIM_CIM
 SG_ BalrRight4Fast_B_Stat : 8|1@0+ (1,0) [0|1] "SED"  APIM_CDC,IPC,APIM_CIM
 SG_ BalrRight4Dsply_B_Stat : 0|1@0+ (1,0) [0|1] "SED"  APIM_CDC,IPC,APIM_CIM
 SG_ BalrRight4CurntY_L_Actl : 15|7@0+ (0.5,-32) [-32|31.5] "meter"  APIM_CDC,IPC,APIM_CIM
 SG_ BalrRight4CurntX_L_Actl : 7|7@0+ (0.5,-32) [-32|31.5] "meter"  APIM_CDC,IPC,APIM_CIM

BO_ 1254 BoundaryAlert_Right_3_HS3: 8 GWM
 SG_ BalrRight3Threat_D_Stat : 16|1@0+ (1,0) [0|1] "SED"  APIM_CDC,IPC,APIM_CIM
 SG_ BalrRight3Prev3Y_L_Actl : 51|7@0+ (0.5,-32) [-32|31.5] "meter"  APIM_CDC,IPC,APIM_CIM
 SG_ BalrRight3Prev3X_L_Actl : 42|7@0+ (0.5,-32) [-32|31.5] "meter"  APIM_CDC,IPC,APIM_CIM
 SG_ BalrRight3Prev2Y_L_Actl : 33|7@0+ (0.5,-32) [-32|31.5] "meter"  APIM_CDC,IPC,APIM_CIM
 SG_ BalrRight3Prev2X_L_Actl : 24|7@0+ (0.5,-32) [-32|31.5] "meter"  APIM_CDC,IPC,APIM_CIM
 SG_ BalrRight3Prev1Y_L_Actl : 31|7@0+ (0.5,-32) [-32|31.5] "meter"  APIM_CDC,IPC,APIM_CIM
 SG_ BalrRight3Prev1X_L_Actl : 23|7@0+ (0.5,-32) [-32|31.5] "meter"  APIM_CDC,IPC,APIM_CIM
 SG_ BalrRight3Fast_B_Stat : 8|1@0+ (1,0) [0|1] "SED"  APIM_CDC,IPC,APIM_CIM
 SG_ BalrRight3Dsply_B_Stat : 0|1@0+ (1,0) [0|1] "SED"  APIM_CDC,IPC,APIM_CIM
 SG_ BalrRight3CurntY_L_Actl : 15|7@0+ (0.5,-32) [-32|31.5] "meter"  APIM_CDC,IPC,APIM_CIM
 SG_ BalrRight3CurntX_L_Actl : 7|7@0+ (0.5,-32) [-32|31.5] "meter"  APIM_CDC,IPC,APIM_CIM

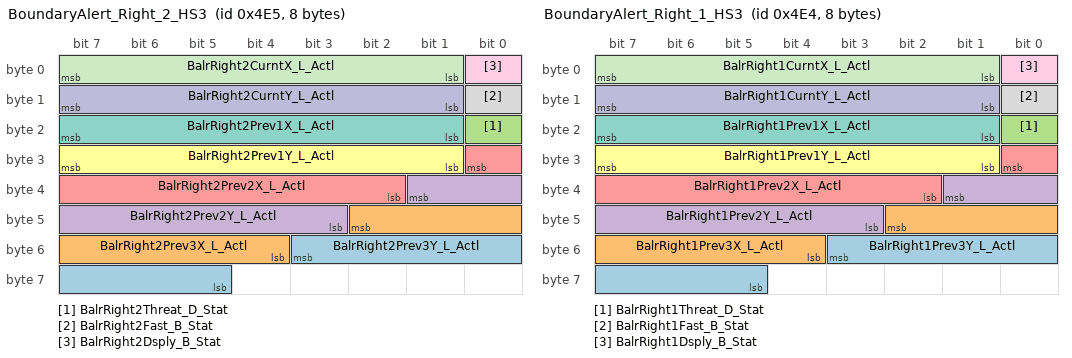
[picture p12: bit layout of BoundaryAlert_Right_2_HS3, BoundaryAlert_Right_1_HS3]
BO_ 1253 BoundaryAlert_Right_2_HS3: 8 GWM
 SG_ BalrRight2Prev3Y_L_Actl : 51|7@0+ (0.5,-32) [-32|31.5] "meter"  APIM_CDC,IPC,APIM_CIM
 SG_ BalrRight2Prev3X_L_Actl : 42|7@0+ (0.5,-32) [-32|31.5] "meter"  APIM_CDC,IPC,APIM_CIM
 SG_ BalrRight2Threat_D_Stat : 16|1@0+ (1,0) [0|1] "SED"  APIM_CDC,IPC,APIM_CIM
 SG_ BalrRight2Prev2Y_L_Actl : 33|7@0+ (0.5,-32) [-32|31.5] "meter"  APIM_CDC,IPC,APIM_CIM
 SG_ BalrRight2Prev2X_L_Actl : 24|7@0+ (0.5,-32) [-32|31.5] "meter"  APIM_CDC,IPC,APIM_CIM
 SG_ BalrRight2Prev1Y_L_Actl : 31|7@0+ (0.5,-32) [-32|31.5] "meter"  APIM_CDC,IPC,APIM_CIM
 SG_ BalrRight2Prev1X_L_Actl : 23|7@0+ (0.5,-32) [-32|31.5] "meter"  APIM_CDC,IPC,APIM_CIM
 SG_ BalrRight2Fast_B_Stat : 8|1@0+ (1,0) [0|1] "SED"  APIM_CDC,IPC,APIM_CIM
 SG_ BalrRight2Dsply_B_Stat : 0|1@0+ (1,0) [0|1] "SED"  APIM_CDC,IPC,APIM_CIM
 SG_ BalrRight2CurntY_L_Actl : 15|7@0+ (0.5,-32) [-32|31.5] "meter"  APIM_CDC,IPC,APIM_CIM
 SG_ BalrRight2CurntX_L_Actl : 7|7@0+ (0.5,-32) [-32|31.5] "meter"  APIM_CDC,IPC,APIM_CIM

BO_ 1252 BoundaryAlert_Right_1_HS3: 8 GWM
 SG_ BalrRight1Prev3Y_L_Actl : 51|7@0+ (0.5,-32) [-32|31.5] "meter"  APIM_CDC,IPC,APIM_CIM
 SG_ BalrRight1Prev3X_L_Actl : 42|7@0+ (0.5,-32) [-32|31.5] "meter"  APIM_CDC,IPC,APIM_CIM
 SG_ BalrRight1Threat_D_Stat : 16|1@0+ (1,0) [0|1] "SED"  APIM_CDC,IPC,APIM_CIM
 SG_ BalrRight1Prev2Y_L_Actl : 33|7@0+ (0.5,-32) [-32|31.5] "meter"  APIM_CDC,IPC,APIM_CIM
 SG_ BalrRight1Prev2X_L_Actl : 24|7@0+ (0.5,-32) [-32|31.5] "meter"  APIM_CDC,IPC,APIM_CIM
 SG_ BalrRight1Prev1Y_L_Actl : 31|7@0+ (0.5,-32) [-32|31.5] "meter"  APIM_CDC,IPC,APIM_CIM
 SG_ BalrRight1Prev1X_L_Actl : 23|7@0+ (0.5,-32) [-32|31.5] "meter"  APIM_CDC,IPC,APIM_CIM
 SG_ BalrRight1Fast_B_Stat : 8|1@0+ (1,0) [0|1] "SED"  APIM_CDC,IPC,APIM_CIM
 SG_ BalrRight1Dsply_B_Stat : 0|1@0+ (1,0) [0|1] "SED"  APIM_CDC,IPC,APIM_CIM
 SG_ BalrRight1CurntY_L_Actl : 15|7@0+ (0.5,-32) [-32|31.5] "meter"  APIM_CDC,IPC,APIM_CIM
 SG_ BalrRight1CurntX_L_Actl : 7|7@0+ (0.5,-32) [-32|31.5] "meter"  APIM_CDC,IPC,APIM_CIM

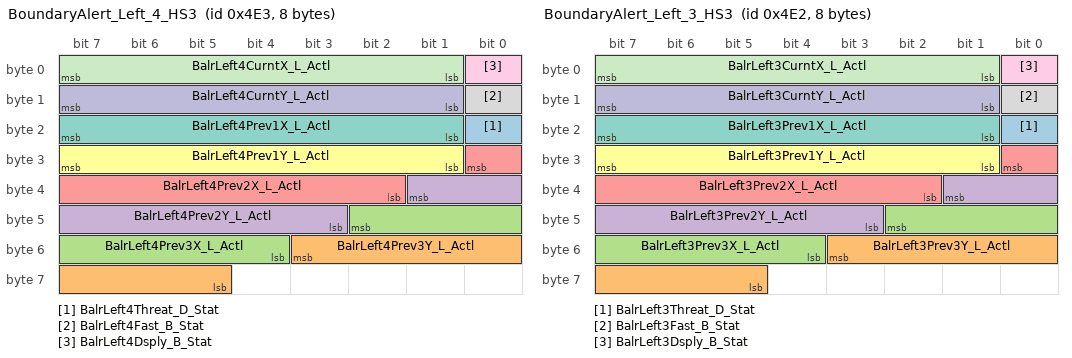
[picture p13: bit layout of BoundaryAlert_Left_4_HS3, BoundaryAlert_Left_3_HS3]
BO_ 1251 BoundaryAlert_Left_4_HS3: 8 GWM
 SG_ BalrLeft4Threat_D_Stat : 16|1@0+ (1,0) [0|1] "SED"  APIM_CDC,IPC,APIM_CIM
 SG_ BalrLeft4Prev3Y_L_Actl : 51|7@0+ (0.5,-32) [-32|31.5] "meter"  APIM_CDC,IPC,APIM_CIM
 SG_ BalrLeft4Prev3X_L_Actl : 42|7@0+ (0.5,-32) [-32|31.5] "meter"  APIM_CDC,IPC,APIM_CIM
 SG_ BalrLeft4Prev2Y_L_Actl : 33|7@0+ (0.5,-32) [-32|31.5] "meter"  APIM_CDC,IPC,APIM_CIM
 SG_ BalrLeft4Prev2X_L_Actl : 24|7@0+ (0.5,-32) [-32|31.5] "meter"  APIM_CDC,IPC,APIM_CIM
 SG_ BalrLeft4Prev1Y_L_Actl : 31|7@0+ (0.5,-32) [-32|31.5] "meter"  APIM_CDC,IPC,APIM_CIM
 SG_ BalrLeft4Prev1X_L_Actl : 23|7@0+ (0.5,-32) [-32|31.5] "meter"  APIM_CDC,IPC,APIM_CIM
 SG_ BalrLeft4Fast_B_Stat : 8|1@0+ (1,0) [0|1] "SED"  APIM_CDC,IPC,APIM_CIM
 SG_ BalrLeft4Dsply_B_Stat : 0|1@0+ (1,0) [0|1] "SED"  APIM_CDC,IPC,APIM_CIM
 SG_ BalrLeft4CurntY_L_Actl : 15|7@0+ (0.5,-32) [-32|31.5] "meter"  APIM_CDC,IPC,APIM_CIM
 SG_ BalrLeft4CurntX_L_Actl : 7|7@0+ (0.5,-32) [-32|31.5] "meter"  APIM_CDC,IPC,APIM_CIM

BO_ 1250 BoundaryAlert_Left_3_HS3: 8 GWM
 SG_ BalrLeft3Threat_D_Stat : 16|1@0+ (1,0) [0|1] "SED"  APIM_CDC,IPC,APIM_CIM
 SG_ BalrLeft3Prev3Y_L_Actl : 51|7@0+ (0.5,-32) [-32|31.5] "meter"  APIM_CDC,IPC,APIM_CIM
 SG_ BalrLeft3Prev3X_L_Actl : 42|7@0+ (0.5,-32) [-32|31.5] "meter"  APIM_CDC,IPC,APIM_CIM
 SG_ BalrLeft3Prev2Y_L_Actl : 33|7@0+ (0.5,-32) [-32|31.5] "meter"  APIM_CDC,IPC,APIM_CIM
 SG_ BalrLeft3Prev2X_L_Actl : 24|7@0+ (0.5,-32) [-32|31.5] "meter"  APIM_CDC,IPC,APIM_CIM
 SG_ BalrLeft3Prev1Y_L_Actl : 31|7@0+ (0.5,-32) [-32|31.5] "meter"  APIM_CDC,IPC,APIM_CIM
 SG_ BalrLeft3Prev1X_L_Actl : 23|7@0+ (0.5,-32) [-32|31.5] "meter"  APIM_CDC,IPC,APIM_CIM
 SG_ BalrLeft3Fast_B_Stat : 8|1@0+ (1,0) [0|1] "SED"  APIM_CDC,IPC,APIM_CIM
 SG_ BalrLeft3Dsply_B_Stat : 0|1@0+ (1,0) [0|1] "SED"  APIM_CDC,IPC,APIM_CIM
 SG_ BalrLeft3CurntY_L_Actl : 15|7@0+ (0.5,-32) [-32|31.5] "meter"  APIM_CDC,IPC,APIM_CIM
 SG_ BalrLeft3CurntX_L_Actl : 7|7@0+ (0.5,-32) [-32|31.5] "meter"  APIM_CDC,IPC,APIM_CIM

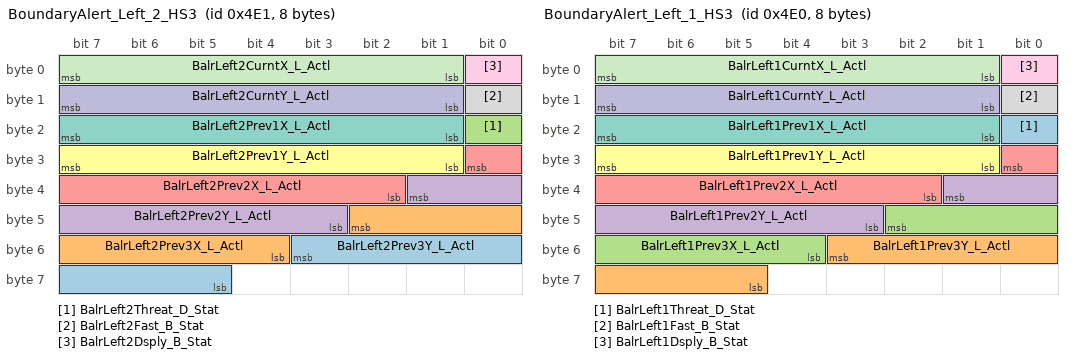
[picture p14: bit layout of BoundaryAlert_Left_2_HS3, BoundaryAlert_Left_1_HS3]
BO_ 1249 BoundaryAlert_Left_2_HS3: 8 GWM
 SG_ BalrLeft2Prev3Y_L_Actl : 51|7@0+ (0.5,-32) [-32|31.5] "meter"  APIM_CDC,IPC,APIM_CIM
 SG_ BalrLeft2Prev3X_L_Actl : 42|7@0+ (0.5,-32) [-32|31.5] "meter"  APIM_CDC,IPC,APIM_CIM
 SG_ BalrLeft2Threat_D_Stat : 16|1@0+ (1,0) [0|1] "SED"  APIM_CDC,IPC,APIM_CIM
 SG_ BalrLeft2Prev2Y_L_Actl : 33|7@0+ (0.5,-32) [-32|31.5] "meter"  APIM_CDC,IPC,APIM_CIM
 SG_ BalrLeft2Prev2X_L_Actl : 24|7@0+ (0.5,-32) [-32|31.5] "meter"  APIM_CDC,IPC,APIM_CIM
 SG_ BalrLeft2Prev1Y_L_Actl : 31|7@0+ (0.5,-32) [-32|31.5] "meter"  APIM_CDC,IPC,APIM_CIM
 SG_ BalrLeft2Prev1X_L_Actl : 23|7@0+ (0.5,-32) [-32|31.5] "meter"  APIM_CDC,IPC,APIM_CIM
 SG_ BalrLeft2Fast_B_Stat : 8|1@0+ (1,0) [0|1] "SED"  APIM_CDC,IPC,APIM_CIM
 SG_ BalrLeft2Dsply_B_Stat : 0|1@0+ (1,0) [0|1] "SED"  APIM_CDC,IPC,APIM_CIM
 SG_ BalrLeft2CurntY_L_Actl : 15|7@0+ (0.5,-32) [-32|31.5] "meter"  APIM_CDC,IPC,APIM_CIM
 SG_ BalrLeft2CurntX_L_Actl : 7|7@0+ (0.5,-32) [-32|31.5] "meter"  APIM_CDC,IPC,APIM_CIM

BO_ 1248 BoundaryAlert_Left_1_HS3: 8 GWM
 SG_ BalrLeft1Threat_D_Stat : 16|1@0+ (1,0) [0|1] "SED"  APIM_CDC,IPC,APIM_CIM
 SG_ BalrLeft1Prev3Y_L_Actl : 51|7@0+ (0.5,-32) [-32|31.5] "meter"  APIM_CDC,IPC,APIM_CIM
 SG_ BalrLeft1Prev3X_L_Actl : 42|7@0+ (0.5,-32) [-32|31.5] "meter"  APIM_CDC,IPC,APIM_CIM
 SG_ BalrLeft1Prev2Y_L_Actl : 33|7@0+ (0.5,-32) [-32|31.5] "meter"  APIM_CDC,IPC,APIM_CIM
 SG_ BalrLeft1Prev2X_L_Actl : 24|7@0+ (0.5,-32) [-32|31.5] "meter"  APIM_CDC,IPC,APIM_CIM
 SG_ BalrLeft1Prev1Y_L_Actl : 31|7@0+ (0.5,-32) [-32|31.5] "meter"  APIM_CDC,IPC,APIM_CIM
 SG_ BalrLeft1Prev1X_L_Actl : 23|7@0+ (0.5,-32) [-32|31.5] "meter"  APIM_CDC,IPC,APIM_CIM
 SG_ BalrLeft1Fast_B_Stat : 8|1@0+ (1,0) [0|1] "SED"  APIM_CDC,IPC,APIM_CIM
 SG_ BalrLeft1Dsply_B_Stat : 0|1@0+ (1,0) [0|1] "SED"  APIM_CDC,IPC,APIM_CIM
 SG_ BalrLeft1CurntY_L_Actl : 15|7@0+ (0.5,-32) [-32|31.5] "meter"  APIM_CDC,IPC,APIM_CIM
 SG_ BalrLeft1CurntX_L_Actl : 7|7@0+ (0.5,-32) [-32|31.5] "meter"  APIM_CDC,IPC,APIM_CIM

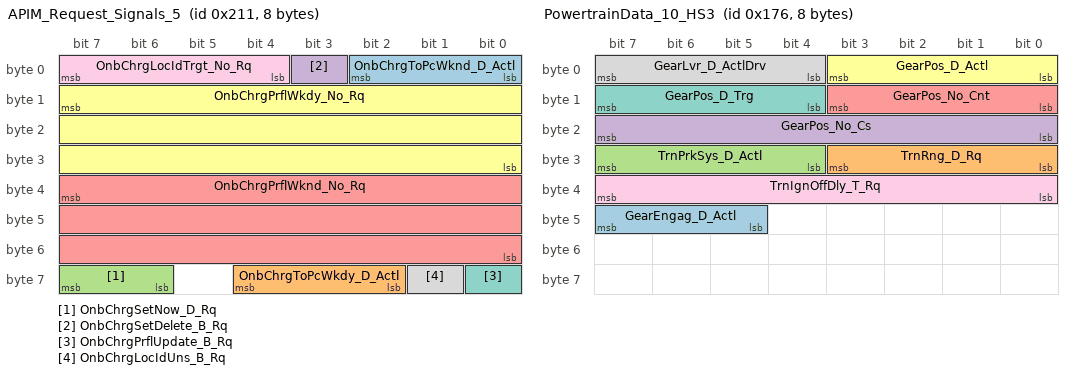
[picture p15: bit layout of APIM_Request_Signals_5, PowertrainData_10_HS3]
BO_ 529 APIM_Request_Signals_5: 8 APIM
 SG_ OnbChrgToPcWknd_D_Actl : 2|3@0+ (1,0) [0|7] "percent"  GWM
 SG_ OnbChrgToPcWkdy_D_Actl : 60|3@0+ (1,0) [0|7] "percent"  GWM
 SG_ OnbChrgSetNow_D_Rq : 63|2@0+ (1,0) [0|3] "SED"  GWM
 SG_ OnbChrgSetDelete_B_Rq : 3|1@0+ (1,0) [0|1] "SED"  GWM
 SG_ OnbChrgPrflWknd_No_Rq : 39|24@0+ (1,0) [0|16777215] "unitless"  GWM
 SG_ OnbChrgPrflWkdy_No_Rq : 15|24@0+ (1,0) [0|16777215] "unitless"  GWM
 SG_ OnbChrgPrflUpdate_B_Rq : 56|1@0+ (1,0) [0|1] "SED"  GWM
 SG_ OnbChrgLocIdUns_B_Rq : 57|1@0+ (1,0) [0|1] "SED"  GWM
 SG_ OnbChrgLocIdTrgt_No_Rq : 7|4@0+ (1,0) [0|15] "unitless"  GWM

BO_ 374 PowertrainData_10_HS3: 8 GWM
 SG_ GearEngag_D_Actl : 47|3@0+ (1,0) [0|7] "SED"  APIM_CDC,APIM_CIM,IPC
 SG_ TrnRng_D_Rq : 27|4@0+ (1,0) [0|15] "SED"  APIM_CDC,APIM,APIM_CISM,APIM_CIM
 SG_ TrnPrkSys_D_Actl : 31|4@0+ (1,0) [0|15] "SED" Vector__XXX
 SG_ GearPos_No_Cs : 23|8@0+ (1,0) [0|255] "unitless" Vector__XXX
 SG_ GearPos_No_Cnt : 11|4@0+ (1,0) [0|15] "unitless" Vector__XXX
 SG_ GearPos_D_Actl : 3|4@0+ (1,0) [0|15] "SED"  APIM_CDC,APIM,APIM_CISM,APIM_CIM
 SG_ GearPos_D_Trg : 15|4@0+ (1,0) [0|15] "SED"  APIM_CDC,APIM,APIM_CISM,APIM_CIM
 SG_ GearLvr_D_ActlDrv : 7|4@0+ (1,0) [0|15] "SED" Vector__XXX
 SG_ TrnIgnOffDly_T_Rq : 39|8@0+ (4,0) [0|1020] "ms" Vector__XXX

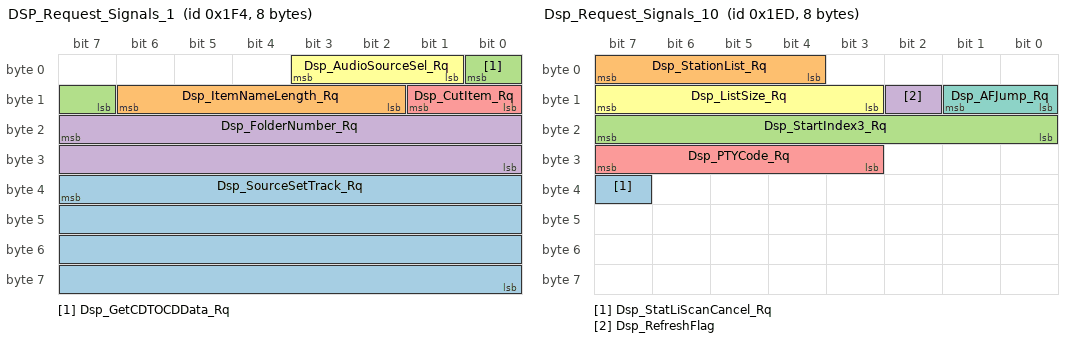
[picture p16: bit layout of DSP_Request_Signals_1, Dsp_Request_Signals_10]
BO_ 500 DSP_Request_Signals_1: 8 APIM
 SG_ Dsp_SourceSetTrack_Rq : 39|32@0+ (1,0) [0|4294967295] "unitless"  ACM
 SG_ Dsp_ItemNameLength_Rq : 14|5@0+ (1,0) [0|20] "SED"  ACM
 SG_ Dsp_GetCDTOCDData_Rq : 0|2@0+ (1,0) [0|3] "SED"  ACM
 SG_ Dsp_FolderNumber_Rq : 23|16@0+ (1,0) [0|65535] "unitless"  ACM
 SG_ Dsp_CutItem_Rq : 9|2@0+ (1,0) [0|3] "SED"  ACM
 SG_ Dsp_AudioSourceSel_Rq : 3|3@0+ (1,0) [0|7] "SED"  ACM

BO_ 503 DSP_Request_Signals_4: 8 APIM
 SG_ Dsp_PlayFrstTrInFldr_Rq : 39|16@0+ (1,0) [0|65535] "unitless"  ACM
 SG_ Dsp_ItemIndex_Rq : 23|16@0+ (1,0) [0|65535] "unitless"  APIM_CDC,ACM
 SG_ Dsp_FolderNumber3_Rq : 7|16@0+ (1,0) [0|65535] "unitless"  APIM_CDC,ACM
 SG_ Dsp_AudioSourceSel3_Rq : 55|3@0+ (1,0) [0|7] "SED"  ACM

BO_ 412 LBClient2_Request_Signals: 8 APIM
 SG_ LBC2_StartItemInd : 55|16@0+ (1,0) [0|65535] "unitless"  ACM
 SG_ LBC2_SetListServ : 47|8@0+ (1,0) [0|255] "unitless"  ACM
 SG_ LBC2_Opcode : 39|2@0+ (1,0) [0|3] "SED"  ACM
 SG_ LBC2_NbrOfItems : 37|6@0+ (1,0) [0|63] "unitless"  ACM
 SG_ LBC2_ItemIndex : 23|16@0+ (1,0) [0|65535] "unitless"  ACM
 SG_ LBC2_ActiveListID : 7|16@0+ (1,0) [0|65535] "unitless"  ACM

BO_ 493 Dsp_Request_Signals_10: 8 APIM
 SG_ Dsp_StatLiScanCancel_Rq : 39|1@0+ (1,0) [0|1] "SED"  ACM
 SG_ Dsp_StationList_Rq : 7|4@0+ (1,0) [0|15] "SED"  ACM
 SG_ Dsp_StartIndex3_Rq : 23|8@0+ (1,0) [0|255] "unitless"  ACM
 SG_ Dsp_RefreshFlag : 10|1@0+ (1,0) [0|1] "SED"  ACM
 SG_ Dsp_PTYCode_Rq : 31|5@0+ (1,0) [0|31] "SED"  ACM
 SG_ Dsp_ListSize_Rq : 15|5@0+ (1,0) [0|31] "SED"  ACM
 SG_ Dsp_AFJump_Rq : 9|2@0+ (1,0) [0|3] "SED"  ACM

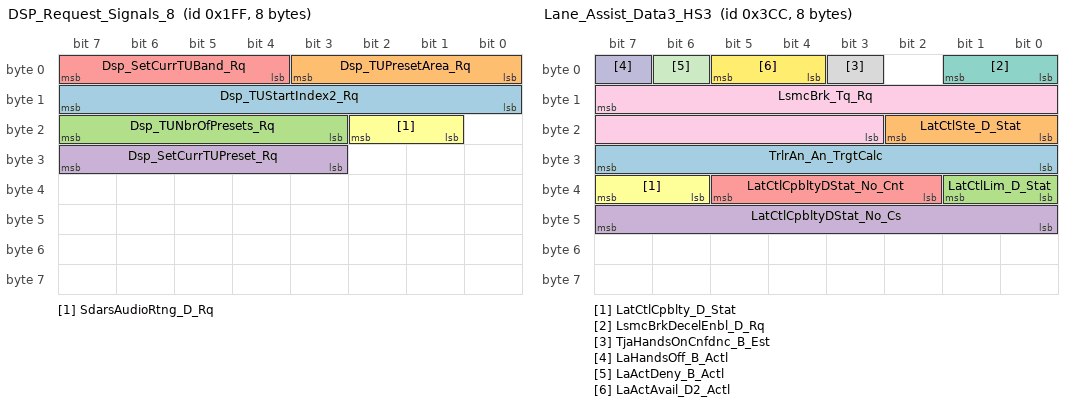
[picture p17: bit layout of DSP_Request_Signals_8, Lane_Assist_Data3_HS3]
BO_ 511 DSP_Request_Signals_8: 8 APIM
 SG_ Dsp_TUStartIndex2_Rq : 15|8@0+ (1,0) [0|255] "unitless"  ACM
 SG_ Dsp_TUPresetArea_Rq : 3|4@0+ (1,0) [0|15] "SED"  ACM
 SG_ Dsp_TUNbrOfPresets_Rq : 23|5@0+ (1,0) [0|30] "SED"  ACM
 SG_ Dsp_SetCurrTUPreset_Rq : 31|5@0+ (1,0) [0|31] "SED"  APIM_CDC,ACM
 SG_ Dsp_SetCurrTUBand_Rq : 7|4@0+ (1,0) [0|15] "SED"  ACM
 SG_ SdarsAudioRtng_D_Rq : 18|2@0+ (1,0) [0|3] "SED"  ACM

BO_ 257 MFD_Request_Signals1: 8 APIM
 SG_ MFD_SetTagMode : 39|2@0+ (1,0) [0|3] "SED"  ACM
 SG_ MFD_SetRBDSMode : 47|2@0+ (1,0) [0|3] "SED"  ACM
 SG_ MFD_SetHDModeRq : 31|2@0+ (1,0) [0|3] "SED"  ACM
 SG_ MFD_GetTagInfo : 7|4@0+ (1,0) [0|15] "day"  ACM

BO_ 972 Lane_Assist_Data3_HS3: 8 GWM
 SG_ TrlrAn_An_TrgtCalc : 31|8@0+ (1,-128) [-128|127] "degrees" Vector__XXX
 SG_ LatCtlSte_D_Stat : 18|3@0+ (1,0) [0|7] "SED" Vector__XXX
 SG_ LatCtlLim_D_Stat : 33|2@0+ (1,0) [0|3] "SED" Vector__XXX
 SG_ LatCtlCpbltyDStat_No_Cs : 47|8@0+ (1,0) [0|255] "unitless" Vector__XXX
 SG_ LatCtlCpbltyDStat_No_Cnt : 37|4@0+ (1,0) [0|15] "unitless" Vector__XXX
 SG_ LatCtlCpblty_D_Stat : 39|2@0+ (1,0) [0|3] "SED" Vector__XXX
 SG_ LsmcBrkDecelEnbl_D_Rq : 1|2@0+ (1,0) [0|3] "SED" Vector__XXX
 SG_ TjaHandsOnCnfdnc_B_Est : 3|1@0+ (1,0) [0|1] "SED" Vector__XXX
 SG_ LsmcBrk_Tq_Rq : 15|13@0+ (4,0) [0|32764] "Nm" Vector__XXX
 SG_ LaHandsOff_B_Actl : 7|1@0+ (1,0) [0|1] "SED"  APIM_CIM,IPC
 SG_ LaActDeny_B_Actl : 6|1@0+ (1,0) [0|1] "SED"  APIM_CDC,APIM_CIM,IPC
 SG_ LaActAvail_D2_Actl : 5|2@0+ (1,0) [0|3] "SED" Vector__XXX

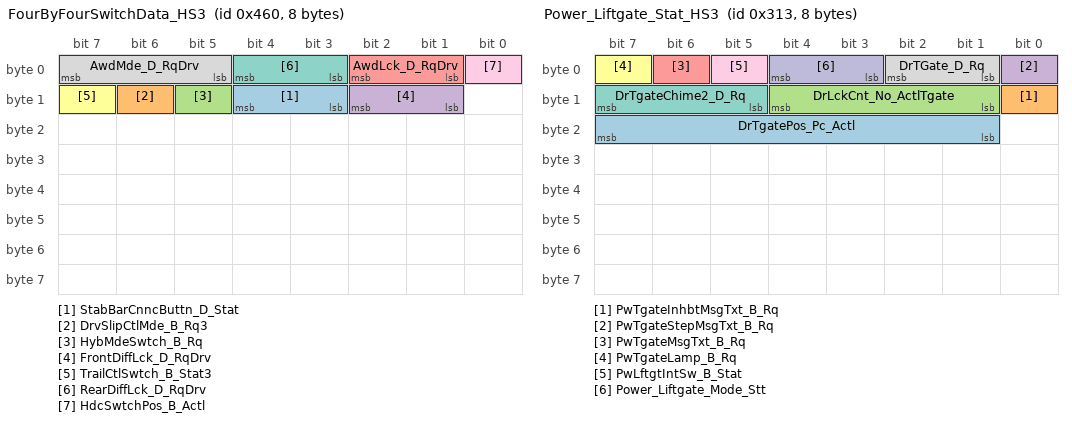
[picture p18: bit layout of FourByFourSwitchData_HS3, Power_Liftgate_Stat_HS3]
BO_ 1120 FourByFourSwitchData_HS3: 8 GWM
 SG_ StabBarCnncButtn_D_Stat : 12|2@0+ (1,0) [0|3] "SED" Vector__XXX
 SG_ DrvSlipCtlMde_B_Rq3 : 14|1@0+ (1,0) [0|1] "SED" Vector__XXX
 SG_ HybMdeSwtch_B_Rq : 13|1@0+ (1,0) [0|1] "SED" Vector__XXX
 SG_ FrontDiffLck_D_RqDrv : 10|2@0+ (1,0) [0|3] "SED" Vector__XXX
 SG_ AwdLck_D_RqDrv : 2|2@0+ (1,0) [0|3] "SED" Vector__XXX
 SG_ TrailCtlSwtch_B_Stat3 : 15|1@0+ (1,0) [0|1] "SED" Vector__XXX
 SG_ RearDiffLck_D_RqDrv : 4|2@0+ (1,0) [0|3] "SED"  APIM_CDC,APIM_CIM,IPC
 SG_ AwdMde_D_RqDrv : 7|3@0+ (1,0) [0|7] "SED"  APIM_CDC,APIM_CIM,IPC
 SG_ HdcSwtchPos_B_Actl : 0|1@0+ (1,0) [0|1] "SED" Vector__XXX

BO_ 1087 Powertrain_Data_5_HS3: 8 GWM
 SG_ TrlrRngeDsply_B_Stat : 16|1@0+ (1,0) [0|1] "SED"  IPC
 SG_ StopStrtImccTxt_D_Dspl : 63|4@0+ (1,0) [0|15] "SED"  IPC
 SG_ StopStrtImccActv_D_St : 52|3@0+ (1,0) [0|7] "SED"  APIM
 SG_ StopStrtImccTxt_D_Rq : 55|3@0+ (1,0) [0|7] "SED"  APIM
 SG_ EngIdlShutDownT_D_Stat : 47|8@0+ (1,0) [0|255] "SED"  APIM_CDC,APIM,APIM_CIM,APIM_CISM
 SG_ DcacFaltMsgTxt_D2_Rq : 39|6@0+ (1,0) [0|63] "SED"  APIM_CDC,APIM,IPC,APIM_CISM,APIM_CIM
 SG_ StopStrtCstm_D_Stat : 26|2@0+ (1,0) [0|3] "SED" Vector__XXX
 SG_ SelDrvMdeCstmPt_D_Stat : 31|5@0+ (1,0) [0|31] "SED" Vector__XXX
 SG_ RepaLcGrdInhbt_B_Stat : 17|1@0+ (1,0) [0|1] "SED" Vector__XXX
 SG_ ClimtCool_D_RqPt : 19|2@0+ (1,0) [0|3] "SED" Vector__XXX
 SG_ StrtInGearMsgTxt_D_Rq : 23|4@0+ (1,0) [0|15] "SED"  APIM_CDC,APIM_CIM,IPC
 SG_ IgnOffInhbt_B_Stat : 9|1@0+ (1,0) [0|1] "SED" Vector__XXX
 SG_ BtsiShifInhbt_B_RqPt : 8|1@0+ (1,0) [0|1] "SED" Vector__XXX
 SG_ FapLcInhbt_B_Rq : 1|1@0+ (1,0) [0|1] "SED" Vector__XXX
 SG_ FapLcStopHold_B_Rq : 2|1@0+ (1,0) [0|1] "SED" Vector__XXX
 SG_ FapLcPrchgBrk_B_Rq : 3|1@0+ (1,0) [0|1] "SED" Vector__XXX
 SG_ FapLcObstcl_B_Stat : 4|1@0+ (1,0) [0|1] "SED" Vector__XXX
 SG_ FapLcMaxGrdInhbt_B_Stat : 5|1@0+ (1,0) [0|1] "SED" Vector__XXX
 SG_ FapLcMaxGrdAbrt_B_Stat : 6|1@0+ (1,0) [0|1] "SED" Vector__XXX
 SG_ FapLcActv_B_Stat : 7|1@0+ (1,0) [0|1] "SED" Vector__XXX
 SG_ BattRgenLoDChrg_D_RqEng : 13|2@0+ (1,0) [0|3] "SED" Vector__XXX
 SG_ BattRgenLoChrg_D_RqEng : 15|2@0+ (1,0) [0|3] "SED" Vector__XXX
 SG_ AdasLcObtclAbrt_B_Stat : 0|1@0+ (1,0) [0|1] "SED" Vector__XXX

BO_ 787 Power_Liftgate_Stat_HS3: 8 GWM
 SG_ DrTgatePos_Pc_Actl : 23|7@0+ (1,0) [0|125] "percent" Vector__XXX
 SG_ PwTgateInhbtMsgTxt_B_Rq : 8|1@0+ (1,0) [0|1] "SED"  APIM_CDC,APIM_CIM,IPC
 SG_ DrLckCnt_No_ActlTgate : 12|4@0+ (1,0) [0|15] "unitless" Vector__XXX
 SG_ PwTgateStepMsgTxt_B_Rq : 0|1@0+ (1,0) [0|1] "SED"  APIM_CDC,APIM,APIM_CISM,APIM_CIM,IPC
 SG_ PwTgateMsgTxt_B_Rq : 6|1@0+ (1,0) [0|1] "SED"  APIM_CDC,APIM,APIM_CISM,APIM_CIM,IPC
 SG_ PwTgateLamp_B_Rq : 7|1@0+ (1,0) [0|1] "SED"  APIM_CDC,APIM,APIM_CISM,APIM_CIM,IPC
 SG_ DrTgateChime2_D_Rq : 15|3@0+ (1,0) [0|7] "SED"  APIM_CDC,APIM,APIM_CISM,APIM_CIM,IPC
 SG_ DrTGate_D_Rq : 2|2@0+ (1,0) [0|3] "SED" Vector__XXX
 SG_ PwLftgtIntSw_B_Stat : 5|1@0+ (1,0) [0|1] "SED"  APIM_CDC,APIM,APIM_CISM,APIM_CIM
 SG_ Power_Liftgate_Mode_Stt : 4|2@0+ (1,0) [0|3] "SED"  APIM_CDC,APIM,APIM_CISM,APIM_CIM,IPC

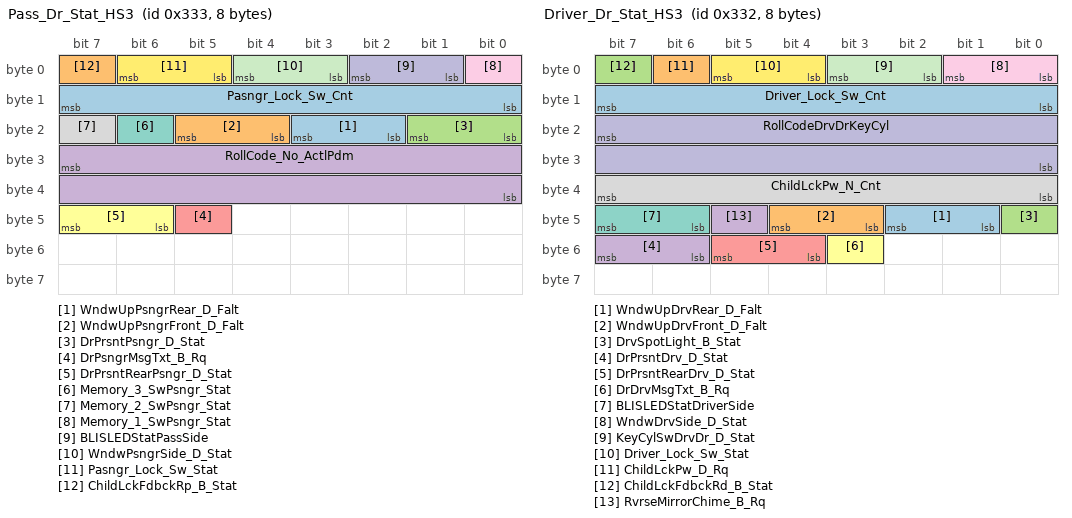
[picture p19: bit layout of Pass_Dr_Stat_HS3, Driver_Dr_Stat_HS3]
BO_ 819 Pass_Dr_Stat_HS3: 8 GWM
 SG_ WndwUpPsngrRear_D_Falt : 19|2@0+ (1,0) [0|3] "SED" Vector__XXX
 SG_ WndwUpPsngrFront_D_Falt : 21|2@0+ (1,0) [0|3] "SED" Vector__XXX
 SG_ DrPrsntPsngr_D_Stat : 17|2@0+ (1,0) [0|3] "SED"  APIM_CDC,APIM,APIM_CISM,APIM_CIM,IPC
 SG_ RollCode_No_ActlPdm : 31|16@0+ (1,0) [0|65535] "unitless" Vector__XXX
 SG_ DrPsngrMsgTxt_B_Rq : 45|1@0+ (1,0) [0|1] "SED"  APIM_CDC,APIM_CIM,IPC
 SG_ DrPrsntRearPsngr_D_Stat : 47|2@0+ (1,0) [0|3] "SED"  APIM_CDC,APIM,APIM_CISM,APIM_CIM,IPC
 SG_ Memory_3_SwPsngr_Stat : 22|1@0+ (1,0) [0|1] "SED" Vector__XXX
 SG_ Memory_2_SwPsngr_Stat : 23|1@0+ (1,0) [0|1] "SED" Vector__XXX
 SG_ Memory_1_SwPsngr_Stat : 0|1@0+ (1,0) [0|1] "SED" Vector__XXX
 SG_ BLISLEDStatPassSide : 2|2@0+ (1,0) [0|3] "SED" Vector__XXX
 SG_ WndwPsngrSide_D_Stat : 4|2@0+ (1,0) [0|3] "SED" Vector__XXX
 SG_ Pasngr_Lock_Sw_Stat : 6|2@0+ (1,0) [0|3] "SED" Vector__XXX
 SG_ Pasngr_Lock_Sw_Cnt : 15|8@0+ (1,0) [0|255] "Cnt" Vector__XXX
 SG_ ChildLckFdbckRp_B_Stat : 7|1@0+ (1,0) [0|1] "SED" Vector__XXX

BO_ 818 Driver_Dr_Stat_HS3: 8 GWM
 SG_ WndwUpDrvRear_D_Falt : 42|2@0+ (1,0) [0|3] "SED" Vector__XXX
 SG_ WndwUpDrvFront_D_Falt : 44|2@0+ (1,0) [0|3] "SED" Vector__XXX
 SG_ DrvSpotLight_B_Stat : 40|1@0+ (1,0) [0|1] "SED" Vector__XXX
 SG_ DrPrsntDrv_D_Stat : 55|2@0+ (1,0) [0|3] "SED"  APIM_CDC,APIM,APIM_CISM,APIM_CIM,IPC
 SG_ DrPrsntRearDrv_D_Stat : 53|2@0+ (1,0) [0|3] "SED"  APIM_CDC,APIM,APIM_CISM,APIM_CIM,IPC
 SG_ DrDrvMsgTxt_B_Rq : 51|1@0+ (1,0) [0|1] "SED"  APIM_CDC,APIM_CIM,IPC
 SG_ BLISLEDStatDriverSide : 47|2@0+ (1,0) [0|3] "SED" Vector__XXX
 SG_ ChildLckPw_N_Cnt : 39|8@0+ (1,0) [0|255] "unitless" Vector__XXX
 SG_ WndwDrvSide_D_Stat : 1|2@0+ (1,0) [0|3] "SED" Vector__XXX
 SG_ RollCodeDrvDrKeyCyl : 23|16@0+ (1,0) [0|65535] "unitless" Vector__XXX
 SG_ KeyCylSwDrvDr_D_Stat : 3|2@0+ (1,0) [0|3] "SED" Vector__XXX
 SG_ Driver_Lock_Sw_Stat : 5|2@0+ (1,0) [0|3] "SED" Vector__XXX
 SG_ Driver_Lock_Sw_Cnt : 15|8@0+ (1,0) [0|255] "Cnt" Vector__XXX
 SG_ ChildLckPw_D_Rq : 6|1@0+ (1,0) [0|1] "SED" Vector__XXX
 SG_ ChildLckFdbckRd_B_Stat : 7|1@0+ (1,0) [0|1] "SED" Vector__XXX
 SG_ RvrseMirrorChime_B_Rq : 45|1@0+ (1,0) [0|1] "SED"  APIM_CDC,APIM_CIM,IPC

BO_TX_BU_ 662 : APIM,APIM_CDC,APIM_CISM,APIM_CIM;
BO_TX_BU_ 479 : APIM,APIM_CDC,APIM_CISM,APIM_CIM;
BO_TX_BU_ 474 : APIM_CDC,APIM_CIM,APIM_CISM,APIM;
BO_TX_BU_ 477 : APIM_CDC,APIM_CIM,APIM_CISM,APIM;
BO_TX_BU_ 260 : APIM_CDC,APIM_CISM,APIM;
BO_TX_BU_ 476 : APIM_CDC,APIM;
BO_TX_BU_ 490 : APIM_CDC,APIM;
BO_TX_BU_ 502 : APIM_CDC,APIM;
BO_TX_BU_ 1116 : APIM_CDC,APIM_CIM,APIM_CISM,APIM;
BO_TX_BU_ 838 : APIM_CDC,APIM_CIM,IPC;
BO_TX_BU_ 529 : APIM_CDC,APIM_CIM,APIM_CISM,APIM;
BO_TX_BU_ 500 : APIM_CDC,APIM;
BO_TX_BU_ 503 : APIM_CDC,APIM;
BO_TX_BU_ 412 : APIM_CDC,APIM;
BO_TX_BU_ 511 : APIM_CDC,APIM;
BO_TX_BU_ 257 : APIM_CISM,APIM;
CM_ SG_ 148 VehYaw_W_Actl "CCMGenSigTimeoutTime=1000";
CM_ BO_ 828 "Set GenSigSendType = NoSigSendType (Cyclic) for the following signals, D.Card 3/31/08
Driver_Lock_Sw_Stat
";
CM_ SG_ 512 PrplWhlTotTqRq_No_Cs "Signal not transmitted on gas variants.";
CM_ SG_ 512 PrplWhlTotTqRq_No_Cnt "Signal not transmitted on gas variants.";
CM_ SG_ 512 EngAout_Tq_MxMxN "Signal not transmitted on gas variants.";
CM_ SG_ 1112 BattTracClntPmp_D_Stat "48V mHEV: ECM_HEVDSL is Tx,  MHT HEV: PCM_HEV is Tx,  Powersplit HEV: SOBDMC_HPCM is Tx";
CM_ SG_ 977 CnvtTopSleepActv_B_Rq "Signal not transmitted on gas and HEV variants.";
CM_ SG_ 977 CnvtTopBrkActv_B_Rq "Signal not transmitted on gas and HEV variants.";
CM_ SG_ 977 CnvtTopPos_Up_Stat "Signal not transmitted on vehicles without convertible tops.";
CM_ SG_ 977 CnvtTopPos_Dn_Stat "Signal not transmitted on vehicles without convertible tops.";
CM_ SG_ 969 TurnLampRrOut_B_Stat "Signal not transmitted on vehicles without a BCMB module.";
CM_ SG_ 969 TurnLampRlOut_B_Stat "Signal not transmitted on vehicles without a BCMB module.";
CM_ SG_ 746 Con_BTAud_Shuffle_St "Object MediaPlayer BTAudio.Shuffle";
CM_ SG_ 746 Con_BTAud_Repeat_St "Object Media Player BTAudio.Repeat";
CM_ SG_ 746 Con_BTAud_IntroScan_St "Object Media Player BTAudio.IntroScan";
CM_ SG_ 746 Con_BTAud_ActTrNum1_St "Object Media Player BTAudio.ActiveTrackNum1
";
CM_ SG_ 746 Con_ShowBTPINNumb_St "Object BT Device.ShowBTPINNumb

PIN value range (dec): 0000 - 9999

Inactive: $3FFD
Invalid: $3FFE";
CM_ SG_ 746 Con_BTAud_Error_St "Object Media Player BTAudio.BTAudioError";
CM_ SG_ 746 Con_BTAud_FunctStats_St "Object Media Player BTAudio.FunctionStatus";
CM_ SG_ 746 Con_BTAud_OpMode_St "Object Media Player BTAudio.OperationMode";
CM_ SG_ 479 DISP_SetVol_Source_Rq "Object.VolumeControl.MFD_SetVol_Source.Rq

SetVol_Source.Rq";
CM_ SG_ 479 DISP_SetVol_Level_Rq "Object.VolumeControl.MFD_SetVol_Level.Rq 

0x0 Inactive/NoChange
0x1 No Volume
0x2 Vol_Step1
0x3 Vol_Step2
0x4 Vol_Step3
Cont.
0x1F Vol_Step30

Object.VolumeControl.SetPointVolume

Object.VolumeControl.SetVol_Level.Rq";
CM_ SG_ 479 DISP_Setshaker_Rq "Object.AudioSettings.SetShaker.Rq
";
CM_ SG_ 474 Nav_SetCurrStatMCCh_Rq "Object Audio.SetDSPProgram
";
CM_ SG_ 474 NAV_SetNEWSMode_Rq "Object Tuner.SetNEWSMode";
CM_ SG_ 474 NAV_SetMid_Rq "Object Audio Settings.SetMid

Level -7..0..7
$F: Inactive

Method: SetMidRange.Rq";
CM_ SG_ 474 NAV_SetDSP_Rq "Object Audio.SetDSP

Object.AudioSettings.SetOccupancy_Mode.Rq";
CM_ SG_ 474 NAV_SetCurrStatFreq_Rq "Object Tuner.SetCurrentStat.Request.Frequency

AM: Freq = 153+ Offset kHz.
Offset 0..1557

FM: Freq = 76+ Offset*0.05 MHz. Offset 0..640
Selected tuned band determine frequency (kHz or MHz).";
CM_ SG_ 474 NAV_SetCurrentStatOp_Rq "Object Tuner.SetCurrentStat.Request.Operation";
CM_ SG_ 474 NAV_SetCurrentPICode_Rq "Object Tuner.SetCurrentStat.Request.PI Code

16 bit hex coded PI Code

";
CM_ SG_ 474 NAV_ARReqstrSystem_Rq "Object Audio Management AudioClient.AudioRequest.Requester System

AudioRequest.Rq : RequesterSystem";
CM_ SG_ 474 NAV_ARReqstrPriority_Rq "Object Audio Management AudioClient.AudioRequest.Requester Priority

AudioRequest.Rq : RequesterPriority";
CM_ SG_ 474 NAV_AROperationType_Rq "Object Audio Management Audio Client.AudioRequest.Operation Type

AudioRequest.Rq : OperationType";
CM_ SG_ 474 NAV_ARAudioSource_Rq "Object Audio Management Audio Client.AudioRequest.Requested Audio Source

$8 interpreted as APIM or Navigation

AudioRequest.Rq : RequestedAudioSource";
CM_ SG_ 477 NAV_SetTreble_Rq "Object Audio.SetTreble.Rq



Level -7..0..7
$F: Inactive";
CM_ SG_ 477 NAV_SetFader_Rq "Object Audio.SetFader

.Rq

Level -7..0..7

$F: Inactive";
CM_ SG_ 477 NAV_SetBass_Rq "Object Audio.SetBass.Rq



Level -7..0..7
$F: Inactive";
CM_ SG_ 477 NAV_SetBalance_Rq "Object Audio.SetBalance.Rq



Level -7..0..7
$F: Inactive";
CM_ SG_ 477 NAV_SetAVC_Rq "Object Audio.SetAVC
Object. Audio.SetSpeed_Comp_Vol.Rq

$F: Inactive";
CM_ SG_ 477 NAV_SecurtyPINUnlock_Rq "Object ACU System Master.SecurityPINUnlock
PIN: from 0000 - 9999
$3FFF: Inactive";
CM_ SG_ 477 NAV_LoadEjectMode_Rq "Object Single CD.LoadEject.Mode";
CM_ SG_ 477 NAV_LoadEjectDisc_Rq "Object Indash CD Changer.LoadEject(Disc Number)
Object Single CD.LoadEject(Action)
";
CM_ SG_ 260 SDARS_GetESN_Rq "Object Tuner.SDARS Tuner.GetESN";
CM_ SG_ 260 SDARS_SRReplay_Rq "Object Tuner.SDARS Tuner.SR-ReplayStatus";
CM_ SG_ 260 SDARS_SelectCategory_Rq "Object Tuner.SDARS Tuner.SetCategory
0x00: All
0x01: Category1
0x02: Category2
....
0xF9: Category249
0xFA: Reserved
....
0xFE: Reserved
0xFF: Invalid
";
CM_ SG_ 260 SDARS_InfoRefChanNum_Rq "Object Tuner.SDARS Tuner.InfoRefresh.Rq
$0: Channel_0
$1: Channel_1
$2: Channel_2
$FE: Channel_254
$FF: Inactive";
CM_ SG_ 260 SDARS_FactoryReset_Rq "Object Tuner.SDARS Tuner.FactoryReset

Object VehicleSettings.FactoryReset.Rq

Object StationManagement.FactoryReset.Rq

Enhanced Memory: FactoryReset_Rq";
CM_ SG_ 476 NAV_SkipCatalouge_Rq "Object Single CD.SkipFolder";
CM_ SG_ 476 NAV_SetOperationMode_Rq "Object Rear CD Changer.SetOperationMode
Object Indash CD Changer.SetOperationMode
Object Single CD.SetOperationMode";
CM_ SG_ 476 NAV_SetDSPProgram_Rq "Object Audio.SetDSPProgram
";
CM_ SG_ 502 Dsp_StartItemIndexRq "Object Media Player BT SDCard.GetMPInfo.StartItemIndex
USB.GetMPInfo.StartItemIndex
SingleCD.GetMPInfo.StartItemIndex

$FFFF: Inactive";
CM_ SG_ 502 Dsp_NbrOfItems2_Rq "Object Media Player 
BT Audio.GetMPInfo.NbrOfItems
SDCard.GetMPInfo.NbrOfItems
USB.GetMPInfo.NbrOfItems
SingleCD.GetMPInfo.NbrOfItems";
CM_ SG_ 502 Dsp_ItemNameLength2_Rq "Object Media Player 
BT Audio.GetMPInfo.ItemNameLength
SDCard.GetMPInfo.ItemNameLength
USB.GetMPInfo.ItemNameLength
SingleCD.GetMPInfo.ItemNameLength";
CM_ SG_ 502 Dsp_FolderNumber2_Rq "Object Media Player 
BT Audio.GetMPInfo.FolderNumber
USB.GetMPInfo.FolderNumber
SDCard.GetMPInfo.FolderNumber
SingleCD.GetMPInfo.FolderNumber

$FFFF: Inactive";
CM_ SG_ 502 Dsp_FolderContent_Rq "Object Media Player 
BT Audio.GetMPInfo.FolderContent
SDCard.GetMPInfo.FolderContent
USB.GetMPInfo.FolderContent
SingleCD.GetMPinfo.Foldercontent

Note: Value table entries were truncated from:
$0: ..FolderNumber
$1: ..OfParameterFolderNumber";
CM_ SG_ 502 Dsp_CutItem2_Rq "Object Media Player 
BT Audio.GetMPInfo.CutItemName
SDCard.GetMPInfo.CutItemName
USB.GetMPInfo.CutItemName
SingleCD.GetMPInfo.CutItemName

Note: value table entry for value $2 was truncated from:
OneQuarterFromTheBeginningThreeQuarterFromTheEnd";
CM_ SG_ 502 Dsp_AudioSourceSel2_Rq "Object Media Player 
BT Audio.GetMPInfo.AudioSource
SDCard.GetMPInfo.AudioSource
USB.GetMPInfo.AudioSource
SingleCD.GetMPInfo.AudioSource";
CM_ SG_ 374 TrnRng_D_Rq "Powersplit HEVs with HF45, HPCM will Tx  this message.  For all other programs it will be Tx by PCM or TCM. ";
CM_ SG_ 374 TrnPrkSys_D_Actl "Powersplit HEVs with HF45, HPCM will Tx  this message.  For all other programs it will be Tx by PCM or TCM. ";
CM_ SG_ 374 GearPos_No_Cs "Powersplit HEVs with HF45, HPCM will Tx  this message.  For all other programs it will be Tx by PCM or TCM. ";
CM_ SG_ 374 GearPos_No_Cnt "Powersplit HEVs with HF45, HPCM will Tx  this message.  For all other programs it will be Tx by PCM or TCM. ";
CM_ SG_ 374 GearPos_D_Actl "Powersplit HEVs with HF45, HPCM will Tx  this message.  For all other programs it will be Tx by PCM or TCM. ";
CM_ SG_ 374 GearPos_D_Trg "Powersplit HEVs with HF45, HPCM will Tx  this message.  For all other programs it will be Tx by PCM or TCM. ";
CM_ SG_ 374 GearLvr_D_ActlDrv "Powersplit HEVs with HF45, HPCM will Tx  this message.  For all other programs it will be Tx by PCM or TCM. ";
CM_ SG_ 500 Dsp_SourceSetTrack_Rq "Object Media Player BTAudio.SetTrack
Object Media Player USB.SetTrack
Object Single CD.SetTrack.AudioSource
";
CM_ SG_ 500 Dsp_ItemNameLength_Rq "Object Media Player BTAudio.GetFolderName.ItemNameLength
Object Media Player USB.GetFolderName.ItemNameLength
Object Single CD.GetFolderName.ItemNameLength";
CM_ SG_ 500 Dsp_GetCDTOCDData_Rq "GetCDTOCData";
CM_ SG_ 500 Dsp_FolderNumber_Rq "Object Media Player BTAudio.GetFolderName.FolderNumber
Object Media Player USB.GetFolderName.FolderNumber
Object Single CD.GetFolderName.FolderNumber";
CM_ SG_ 500 Dsp_CutItem_Rq "Object Media Player BTAudio.GetFolderName.CutItemName
Object Media Player USB.GetFolderName.CutItemName
Object Single CD.GetFolderName.CutItemName

Note: value table entry for value $2 was truncated from:
OneQuarterFromTheBeginningThreeQuarterFromTheEnd";
CM_ SG_ 500 Dsp_AudioSourceSel_Rq "Object Media Player 
{ BTAudio.GetFolderName, 
SDCard.GetFolderName,
USB.GetFolderName,
BTAudio.SetTrack,
SD Card.SetTrack}.AudioSource
USB.SetTrack.AudioSource
Object Single CD.GetFolderName.AudioSource
Object Single CD.SetTrack.AudioSource";
CM_ SG_ 503 Dsp_PlayFrstTrInFldr_Rq "Object Single CD.PlayFirstTrackInFolder
Object Media Player BTAudio.PlayFirstTrackInFolder.FolderNumber
Object Media Player USB.PlayFirstTrackInFolder.FolderNumber

$FFFF: Inactive";
CM_ SG_ 503 Dsp_ItemIndex_Rq "Object Media Player BTAudio.GetDetailedMPInfo.ItemIndex
Object Media Player USB.GetDetailedMPInfo.ItemIndex

$FFFF: Inactive";
CM_ SG_ 503 Dsp_FolderNumber3_Rq "Object Media Player BTAudio.GetDetailedMPInfo.FolderNumber
Object Media Player USB.GetDetailedMPInfo.FolderNumber

$FFFF: Inactive";
CM_ SG_ 503 Dsp_AudioSourceSel3_Rq "Objects Media Player  {BTAudio, USB}.GetDetailedMPInfo.AudioSource

Objects Media Player {Single CD, BTAudio, USB}.PlayFirstTrackInFolder.AudioSource";
CM_ SG_ 412 LBC2_StartItemInd "Object. ListBrowser.ItemInf.Rq.StartItemInd
0x0000:Inactive
0x0001:1
0xFFFE:65634
0xFFFF:Reserved";
CM_ SG_ 412 LBC2_SetListServ "Object. ListBrowser.ItemInf.Rq.SetListServ
0x00:Inactive
0x01:ServerID_1
0xFF:ALL";
CM_ SG_ 412 LBC2_Opcode "Object. ListBrowser.ItemInf.Rq.Opcode";
CM_ SG_ 412 LBC2_NbrOfItems "Object. ListBrowser.ItemInf.Rq.NbrOfItems
0x00:Inactive
0x01:1Item
0x3F:63Items";
CM_ SG_ 412 LBC2_ItemIndex "Object. ListBrowser.ItemInf.Rq.ItemIndex
0x0000:BrowseActiveListID
0x0001:EntryIndex_1
0xFFFF:ParentOfActiveListID";
CM_ SG_ 412 LBC2_ActiveListID "Object. ListBrowser.ItemInf.Rq.ActiveListID
0x0000:Root
0xFFFF:Reserved";
CM_ SG_ 493 Dsp_StatLiScanCancel_Rq "Object Tuner.StationListScan";
CM_ SG_ 493 Dsp_StationList_Rq "Object Tuner.GetStationList(StationList)
(Parameter1)";
CM_ SG_ 493 Dsp_StartIndex3_Rq "Object TunerGetStationList(StartingIndex)
(Parameter3)";
CM_ SG_ 493 Dsp_RefreshFlag "Object Tuner.GetStationList(StationList)
(Parameter5)";
CM_ SG_ 493 Dsp_PTYCode_Rq "Object Tuner.GetStationList(PTYCode)
(Parramater4)

$0: Invalid
$1: PTY 1 (News)
..
$1F: PTY 31 (Alarm)";
CM_ SG_ 493 Dsp_ListSize_Rq "Object Tuner.GetStationList(ListSize)
(Parameter2)";
CM_ SG_ 493 Dsp_AFJump_Rq "Object Tuner.AFJump.Rq";
CM_ SG_ 511 Dsp_TUStartIndex2_Rq "Object Tuner.GetTUPresetInfo.StartIndex2
Object DAB.GetTUPresetInfo.StartIndex2
Object SDARS.GetTUPresetInfo.StartIndex2

$1-$FF: Preset 1 to 255";
CM_ SG_ 511 Dsp_TUPresetArea_Rq "Object Tuner.GetTUPresetInfo.PresetArea
Object DAB.GetTUPresetInfo.PresetArea
Object SDARS.GetTUPresetInfo.PresetArea";
CM_ SG_ 511 Dsp_TUNbrOfPresets_Rq "Object Tuner.GetTUPresetInfo.NumberOfPresets
Object DAB.GetTUPresetInfo.NumberOfPresets
Object SDARS.GetTUPresetInfo.NumberOfPresets

$1-$1E: Preset 1 to 30";
CM_ SG_ 511 Dsp_SetCurrTUPreset_Rq "Object Tuner.GetTUPresetInfo.SetCurrentTUPreset
Object DAB.GetTUPresetInfo.SetCurrentTUPreset
Object SDARS.GetTUPresetInfo.SetCurrentTUPreset

$1-$1E: Preset 1 to 30";
CM_ SG_ 511 Dsp_SetCurrTUBand_Rq "Object Tuner.SetCurrTUBand
Object DAB.SetCurrTUBand
Object SDARS.SetCurrTUBand
";
CM_ SG_ 257 MFD_SetTagMode "Used by MFD to distribute actual Master Clock data to the Slave";
CM_ SG_ 257 MFD_SetRBDSMode "Used by MFD to distribute actual Master Clock data to the Slave";
CM_ SG_ 257 MFD_SetHDModeRq "Used by MFD to distribute actual Master Clock data to the Slave";
CM_ SG_ 257 MFD_GetTagInfo "Used by MFD to distribute actual Master Clock data to the Slave";
BA_DEF_ BO_  "FrameRouting" STRING ;
BA_DEF_ BO_  "NetworkInitialization" ENUM  "No","Yes";
BA_DEF_ BO_  "GenMsgStartDelayTime" INT 0 10000;
BA_DEF_ BO_  "GenMsgNrOfRepetition" INT 0 100;
BA_DEF_ BO_  "GenMsgDelayTime" INT 0 1000;
BA_DEF_ BO_  "GenMsgCycleTime" INT 0 100000;
BA_DEF_ BO_  "GenMsgSendType" ENUM  "FixedPeriodic","Event","EnabledPeriodic","NotUsed","NotUsed","EventPeriodic","NotUsed","NotUsed","NoMsgSendType";
BA_DEF_ SG_  "U_P702_MY2024_Tx" ENUM  "No","Yes";
BA_DEF_ SG_  "U_V710_MY2023_Tx" ENUM  "No","Yes";
BA_DEF_ SG_  "U_CDX74X_MY2024_Tx" ENUM  "No","Yes";
BA_DEF_ SG_  "U_CDX707_MY2023_Tx" ENUM  "No","Yes";
BA_DEF_ SG_  "U_P708_MY2023_Tx" ENUM  "No","Yes";
BA_DEF_ SG_  "U_V713AV_MY2022_Tx" ENUM  "No","Yes";
BA_DEF_ SG_  "U_V713N_MY2022_Tx" ENUM  "No","Yes";
BA_DEF_ SG_  "ECGUsedTxSignal" ENUM  "No","Yes";
BA_DEF_ SG_  "U_P702_MY2024_Rx" ENUM  "No","Yes";
BA_DEF_ SG_  "U_V710_MY2023_Rx" ENUM  "No","Yes";
BA_DEF_ SG_  "U_CDX74X_MY2024_Rx" ENUM  "No","Yes";
BA_DEF_ SG_  "U_CDX707_MY2023_Rx" ENUM  "No","Yes";
BA_DEF_ SG_  "U_P708_MY2023_Rx" ENUM  "No","Yes";
BA_DEF_ SG_  "U_V713AV_MY2022_Rx" ENUM  "No","Yes";
BA_DEF_ SG_  "U_V713N_MY2022_Rx" ENUM  "No","Yes";
BA_DEF_ SG_  "ECGUsedRxSignal" ENUM  "No","Yes";
BA_DEF_ SG_  "UsedOnPgmDBC" ENUM  "No","Yes";
BA_DEF_ SG_  "ContentDependant" ENUM  "No","Yes";
BA_DEF_ SG_  "GenSigStartValue" HEX 0 268435455;
BA_DEF_ SG_  "MetaData" ENUM  "No","Yes";
BA_DEF_ SG_  "WakeupSignal" ENUM  "No","Yes";
BA_DEF_ SG_  "GenSigInactiveValue" INT 0 100000;
BA_DEF_ SG_  "GenSigSendType" ENUM  "Cyclic","OnWrite","vector_leerstring","OnChange","vector_leerstring","IfActive","vector_leerstring","NoSigSendType";
BA_DEF_ BO_  "TpTxIndex" INT 0 536870911;
BA_DEF_ BO_  "OvtpPushApplication" ENUM  "FALSE","TRUE";
BA_DEF_ BO_  "SCP_FreshnessValueLength" INT 0 512;
BA_DEF_ BO_  "SCP_DataId" INT 0 17663;
BA_DEF_ BO_  "SCP_FreshnessValueTxLength" INT 0 512;
BA_DEF_ BO_  "SCP_AuthInfoTxLength" INT 0 512;
BA_DEF_ BO_  "SC_Message" ENUM  "No","Yes";
BA_DEF_ BO_  "GenMsgRoutingTimeoutTime" INT 0 5000;
BA_DEF_ BO_  "MessageGateway" ENUM  "No","Yes";
BA_DEF_ BO_  "NmAsrMessage" ENUM  "No","Yes";
BA_DEF_ BO_  "DiagState" ENUM  "No","Yes";
BA_DEF_ BO_  "DiagRequest" ENUM  "No","Yes";
BA_DEF_ BO_  "DiagResponse" ENUM  "No","Yes";
BA_DEF_ BO_  "NmMessage" ENUM  "No","Yes";
BA_DEF_ BO_  "GenMsgILSupport" ENUM  "No","Yes";
BA_DEF_DEF_  "FrameRouting" "";
BA_DEF_DEF_  "NetworkInitialization" "Yes";
BA_DEF_DEF_  "GenMsgStartDelayTime" 0;
BA_DEF_DEF_  "GenMsgNrOfRepetition" 1;
BA_DEF_DEF_  "GenMsgDelayTime" 20;
BA_DEF_DEF_  "GenMsgCycleTime" 0;
BA_DEF_DEF_  "GenMsgSendType" "NoMsgSendType";
BA_DEF_DEF_  "U_P702_MY2024_Tx" "No";
BA_DEF_DEF_  "U_V710_MY2023_Tx" "No";
BA_DEF_DEF_  "U_CDX74X_MY2024_Tx" "No";
BA_DEF_DEF_  "U_CDX707_MY2023_Tx" "No";
BA_DEF_DEF_  "U_P708_MY2023_Tx" "No";
BA_DEF_DEF_  "U_V713AV_MY2022_Tx" "No";
BA_DEF_DEF_  "U_V713N_MY2022_Tx" "No";
BA_DEF_DEF_  "ECGUsedTxSignal" "No";
BA_DEF_DEF_  "U_P702_MY2024_Rx" "No";
BA_DEF_DEF_  "U_V710_MY2023_Rx" "No";
BA_DEF_DEF_  "U_CDX74X_MY2024_Rx" "No";
BA_DEF_DEF_  "U_CDX707_MY2023_Rx" "No";
BA_DEF_DEF_  "U_P708_MY2023_Rx" "No";
BA_DEF_DEF_  "U_V713AV_MY2022_Rx" "No";
BA_DEF_DEF_  "U_V713N_MY2022_Rx" "No";
BA_DEF_DEF_  "ECGUsedRxSignal" "No";
BA_DEF_DEF_  "UsedOnPgmDBC" "Yes";
BA_DEF_DEF_  "ContentDependant" "No";
BA_DEF_DEF_  "GenSigStartValue" 0;
BA_DEF_DEF_  "MetaData" "No";
BA_DEF_DEF_  "WakeupSignal" "No";
BA_DEF_DEF_  "GenSigInactiveValue" 0;
BA_DEF_DEF_  "GenSigSendType" "NoSigSendType";
BA_DEF_DEF_  "TpTxIndex" 0;
BA_DEF_DEF_  "OvtpPushApplication" "FALSE";
BA_DEF_DEF_  "SCP_FreshnessValueLength" 64;
BA_DEF_DEF_  "SCP_DataId" 0;
BA_DEF_DEF_  "SCP_FreshnessValueTxLength" 11;
BA_DEF_DEF_  "SCP_AuthInfoTxLength" 53;
BA_DEF_DEF_  "SC_Message" "No";
BA_DEF_DEF_  "GenMsgRoutingTimeoutTime" 0;
BA_DEF_DEF_  "MessageGateway" "No";
BA_DEF_DEF_  "NmAsrMessage" "No";
BA_DEF_DEF_  "DiagState" "No";
BA_DEF_DEF_  "DiagRequest" "No";
BA_DEF_DEF_  "DiagResponse" "No";
BA_DEF_DEF_  "NmMessage" "No";
BA_DEF_DEF_  "GenMsgILSupport" "Yes";
BA_ "GenMsgSendType" BO_ 662 5;
BA_ "GenMsgCycleTime" BO_ 662 1000;
BA_ "FrameRouting" BO_ 515 "FD1_CAN,0x203;";
BA_ "FrameRouting" BO_ 513 "FD1_CAN,0x201;";
BA_ "FrameRouting" BO_ 148 "HS2_CAN,0x91;FD1_CAN,0x91";
BA_ "FrameRouting" BO_ 1042 "FD1_CAN,0x412;";
BA_ "FrameRouting" BO_ 828 "FD3_CAN,0x33C;";
BA_ "FrameRouting" BO_ 330 "FD1_CAN,0x14A;";
BA_ "FrameRouting" BO_ 512 "FD1_CAN,0x200;";
BA_ "FrameRouting" BO_ 862 "MS1_CAN,0x35E;";
BA_ "FrameRouting" BO_ 831 "FD3_CAN,0x33F;";
BA_ "FrameRouting" BO_ 331 "FD1_CAN,0x14B;";
BA_ "FrameRouting" BO_ 965 "FD1_CAN,0x3C5;";
BA_ "GenMsgSendType" BO_ 1242 5;
BA_ "GenMsgCycleTime" BO_ 1242 1000;
BA_ "GenMsgSendType" BO_ 1245 5;
BA_ "GenMsgCycleTime" BO_ 1245 1000;
BA_ "FrameRouting" BO_ 781 "MS2_CAN,0x30D;";
BA_ "FrameRouting" BO_ 1022 "MS2_CAN,0x3FE;";
BA_ "FrameRouting" BO_ 903 "FD2_CAN,0x387;";
BA_ "FrameRouting" BO_ 901 "FD2_CAN,0x385;";
BA_ "FrameRouting" BO_ 1112 "HS2_CAN,0x458;";
BA_ "FrameRouting" BO_ 977 "MS1_CAN,0x3D1;";
BA_ "FrameRouting" BO_ 969 "MS1_CAN,0x3C9;";
BA_ "GenMsgSendType" BO_ 530 1;
BA_ "GenMsgSendType" BO_ 746 5;
BA_ "GenMsgCycleTime" BO_ 746 1000;
BA_ "GenMsgSendType" BO_ 479 1;
BA_ "GenMsgSendType" BO_ 474 1;
BA_ "GenMsgSendType" BO_ 477 1;
BA_ "GenMsgSendType" BO_ 260 1;
BA_ "GenMsgSendType" BO_ 476 1;
BA_ "GenMsgSendType" BO_ 490 1;
BA_ "GenMsgILSupport" BO_ 1916 0;
BA_ "DiagResponse" BO_ 1916 1;
BA_ "GenMsgSendType" BO_ 1916 1;
BA_ "GenMsgDelayTime" BO_ 1916 0;
BA_ "NetworkInitialization" BO_ 1916 0;
BA_ "GenMsgILSupport" BO_ 1908 0;
BA_ "DiagRequest" BO_ 1908 1;
BA_ "GenMsgSendType" BO_ 1908 1;
BA_ "GenMsgDelayTime" BO_ 1908 0;
BA_ "NetworkInitialization" BO_ 1908 0;
BA_ "GenMsgILSupport" BO_ 1432 0;
BA_ "NmAsrMessage" BO_ 1432 1;
BA_ "GenMsgSendType" BO_ 1432 0;
BA_ "GenMsgCycleTime" BO_ 1432 1000;
BA_ "NetworkInitialization" BO_ 1432 0;
BA_ "GenMsgILSupport" BO_ 1923 0;
BA_ "DiagRequest" BO_ 1923 1;
BA_ "GenMsgSendType" BO_ 1923 1;
BA_ "GenMsgDelayTime" BO_ 1923 0;
BA_ "NetworkInitialization" BO_ 1923 0;
BA_ "GenMsgILSupport" BO_ 1931 0;
BA_ "DiagResponse" BO_ 1931 1;
BA_ "GenMsgSendType" BO_ 1931 1;
BA_ "GenMsgDelayTime" BO_ 1931 0;
BA_ "NetworkInitialization" BO_ 1931 0;
BA_ "FrameRouting" BO_ 896 "FD1_CAN,0x380;";
BA_ "FrameRouting" BO_ 897 "FD1_CAN,0x381;";
BA_ "GenMsgSendType" BO_ 502 1;
BA_ "FrameRouting" BO_ 955 "FD1_CAN,0x3BB;";
BA_ "GenMsgSendType" BO_ 1116 5;
BA_ "GenMsgCycleTime" BO_ 1116 1000;
BA_ "FrameRouting" BO_ 608 "HS2_CAN,0x25F;";
BA_ "FrameRouting" BO_ 1237 "FD1_CAN,0x4D5;FD3_CAN,0x4D5";
BA_ "GenMsgSendType" BO_ 838 0;
BA_ "GenMsgCycleTime" BO_ 838 100;
BA_ "FrameRouting" BO_ 1255 "FD1_CAN,0x4E7;FD3_CAN,0x4E7";
BA_ "FrameRouting" BO_ 1254 "FD1_CAN,0x4E6;FD3_CAN,0x4E6";
BA_ "FrameRouting" BO_ 1253 "FD1_CAN,0x4E5;FD3_CAN,0x4E5";
BA_ "FrameRouting" BO_ 1252 "FD1_CAN,0x4E4;FD3_CAN,0x4E4";
BA_ "FrameRouting" BO_ 1251 "FD1_CAN,0x4E3;FD3_CAN,0x4E3";
BA_ "FrameRouting" BO_ 1250 "FD1_CAN,0x4E2;FD3_CAN,0x4E2";
BA_ "FrameRouting" BO_ 1249 "FD1_CAN,0x4E1;FD3_CAN,0x4E1";
BA_ "FrameRouting" BO_ 1248 "FD1_CAN,0x4E0;FD3_CAN,0x4E0";
BA_ "GenMsgSendType" BO_ 529 5;
BA_ "GenMsgCycleTime" BO_ 529 1000;
BA_ "FrameRouting" BO_ 374 "FD1_CAN,0x176;";
BA_ "GenMsgSendType" BO_ 500 1;
BA_ "GenMsgSendType" BO_ 503 1;
BA_ "GenMsgSendType" BO_ 412 1;
BA_ "GenMsgSendType" BO_ 493 1;
BA_ "GenMsgSendType" BO_ 511 1;
BA_ "GenMsgSendType" BO_ 257 1;
BA_ "FrameRouting" BO_ 972 "FD1_CAN,0x3CC;FD3_CAN,0x3CC";
BA_ "FrameRouting" BO_ 1120 "HS2_CAN,0x460;";
BA_ "FrameRouting" BO_ 1087 "FD1_CAN,0x43F;";
BA_ "FrameRouting" BO_ 787 "MS1_CAN,0x313;MS2_CAN,0x313";
BA_ "FrameRouting" BO_ 819 "FD3_CAN,0x333;";
BA_ "FrameRouting" BO_ 818 "FD3_CAN,0x332;";
BA_ "GenSigSendType" SG_ 662 RgstrSetIbr_D_Rq 3;
BA_ "U_P702_MY2024_Tx" SG_ 662 RgstrSetIbr_D_Rq 1;
BA_ "GenSigSendType" SG_ 662 RgstrSetObr_D_Rq 3;
BA_ "U_P702_MY2024_Tx" SG_ 662 RgstrSetObr_D_Rq 1;
BA_ "GenSigSendType" SG_ 662 RgstrSetIbl_D_Rq 3;
BA_ "U_P702_MY2024_Tx" SG_ 662 RgstrSetIbl_D_Rq 1;
BA_ "GenSigSendType" SG_ 662 RgstrSetObl_D_Rq 3;
BA_ "U_P702_MY2024_Tx" SG_ 662 RgstrSetObl_D_Rq 1;
BA_ "GenSigSendType" SG_ 662 ActvButtnRight_D_Rq 3;
BA_ "U_P702_MY2024_Tx" SG_ 662 ActvButtnRight_D_Rq 1;
BA_ "GenSigSendType" SG_ 662 ActvButtnLeft_D_Rq 3;
BA_ "U_P702_MY2024_Tx" SG_ 662 ActvButtnLeft_D_Rq 1;
BA_ "GenSigSendType" SG_ 662 Third_Rear_Set_Temp 3;
BA_ "U_V710_MY2023_Tx" SG_ 662 Third_Rear_Set_Temp 1;
BA_ "U_P708_MY2023_Tx" SG_ 662 Third_Rear_Set_Temp 1;
BA_ "U_P702_MY2024_Tx" SG_ 662 Third_Rear_Set_Temp 1;
BA_ "GenSigSendType" SG_ 662 Third_Rear_Blower_Speed 3;
BA_ "U_V710_MY2023_Tx" SG_ 662 Third_Rear_Blower_Speed 1;
BA_ "U_P708_MY2023_Tx" SG_ 662 Third_Rear_Blower_Speed 1;
BA_ "U_P702_MY2024_Tx" SG_ 662 Third_Rear_Blower_Speed 1;
BA_ "GenSigSendType" SG_ 662 Rear_Temp 3;
BA_ "U_V710_MY2023_Tx" SG_ 662 Rear_Temp 1;
BA_ "U_P708_MY2023_Tx" SG_ 662 Rear_Temp 1;
BA_ "U_P702_MY2024_Tx" SG_ 662 Rear_Temp 1;
BA_ "GenSigSendType" SG_ 662 Rear_Set_Temp 3;
BA_ "U_V710_MY2023_Tx" SG_ 662 Rear_Set_Temp 1;
BA_ "U_P708_MY2023_Tx" SG_ 662 Rear_Set_Temp 1;
BA_ "U_P702_MY2024_Tx" SG_ 662 Rear_Set_Temp 1;
BA_ "GenSigSendType" SG_ 662 Rear_Blower_Speed 3;
BA_ "U_V710_MY2023_Tx" SG_ 662 Rear_Blower_Speed 1;
BA_ "U_P708_MY2023_Tx" SG_ 662 Rear_Blower_Speed 1;
BA_ "U_P702_MY2024_Tx" SG_ 662 Rear_Blower_Speed 1;
BA_ "GenSigSendType" SG_ 662 Running_Board_Cmd2 3;
BA_ "U_V710_MY2023_Tx" SG_ 662 Running_Board_Cmd2 1;
BA_ "U_P708_MY2023_Tx" SG_ 662 Running_Board_Cmd2 1;
BA_ "U_P702_MY2024_Tx" SG_ 662 Running_Board_Cmd2 1;
BA_ "U_P702_MY2024_Rx" SG_ 515 FuelLvlPss_Pc_DsplyEng 1;
BA_ "U_P702_MY2024_Rx" SG_ 515 FuelLvlAct_Pc_DsplyEng 1;
BA_ "GenSigStartValue" SG_ 515 PtIgnSwtch_D_Stat 2;
BA_ "GenSigStartValue" SG_ 513 BptAllw_Pw_Dsply 1022;
BA_ "U_P702_MY2024_Rx" SG_ 513 BptAllw_Pw_Dsply 1;
BA_ "U_V710_MY2023_Rx" SG_ 513 BptRngeRsrvMet_B_Stat 1;
BA_ "U_P708_MY2023_Rx" SG_ 513 BptRngeRsrvMet_B_Stat 1;
BA_ "U_P702_MY2024_Rx" SG_ 513 BptRngeRsrvMet_B_Stat 1;
BA_ "U_V710_MY2023_Rx" SG_ 513 BptPwOut_B_Dsply 1;
BA_ "U_P708_MY2023_Rx" SG_ 513 BptPwOut_B_Dsply 1;
BA_ "U_P702_MY2024_Rx" SG_ 513 BptPwOut_B_Dsply 1;
BA_ "U_V710_MY2023_Rx" SG_ 513 BptStrtStop_D_Stat 1;
BA_ "U_P708_MY2023_Rx" SG_ 513 BptStrtStop_D_Stat 1;
BA_ "U_P702_MY2024_Rx" SG_ 513 BptStrtStop_D_Stat 1;
BA_ "U_V710_MY2023_Rx" SG_ 513 BptComm_D_RqHtrn 1;
BA_ "U_P708_MY2023_Rx" SG_ 513 BptComm_D_RqHtrn 1;
BA_ "U_P702_MY2024_Rx" SG_ 513 BptComm_D_RqHtrn 1;
BA_ "U_V710_MY2023_Rx" SG_ 513 BptMde_D_Stat 1;
BA_ "U_P708_MY2023_Rx" SG_ 513 BptMde_D_Stat 1;
BA_ "U_P702_MY2024_Rx" SG_ 513 BptMde_D_Stat 1;
BA_ "U_V710_MY2023_Rx" SG_ 513 Bpt_D_StatHtrn 1;
BA_ "U_P708_MY2023_Rx" SG_ 513 Bpt_D_StatHtrn 1;
BA_ "U_V710_MY2023_Rx" SG_ 513 BptSustn_B_Rq 1;
BA_ "U_P708_MY2023_Rx" SG_ 513 BptSustn_B_Rq 1;
BA_ "U_V710_MY2023_Rx" SG_ 513 GridSrvc01_B_Stat 1;
BA_ "U_P708_MY2023_Rx" SG_ 513 GridSrvc01_B_Stat 1;
BA_ "U_P702_MY2024_Rx" SG_ 513 GridSrvc01_B_Stat 1;
BA_ "U_V710_MY2023_Rx" SG_ 513 BattTracTeColr_D_Dsply 1;
BA_ "U_P702_MY2024_Rx" SG_ 513 BattTracTeColr_D_Dsply 1;
BA_ "U_V710_MY2023_Rx" SG_ 513 MtrTracTeColr_D_Dsply 1;
BA_ "U_P702_MY2024_Rx" SG_ 513 MtrTracTeColr_D_Dsply 1;
BA_ "U_V710_MY2023_Rx" SG_ 513 MtrTracTe_Pc_Dsply 1;
BA_ "U_P702_MY2024_Rx" SG_ 513 MtrTracTe_Pc_Dsply 1;
BA_ "U_V710_MY2023_Rx" SG_ 513 BattTracTe_Pc_Dsply 1;
BA_ "U_P702_MY2024_Rx" SG_ 513 BattTracTe_Pc_Dsply 1;
BA_ "WakeupSignal" SG_ 513 ChrgStat_D3_Dsply 1;
BA_ "U_V710_MY2023_Rx" SG_ 513 ChrgStat_D3_Dsply 1;
BA_ "U_P708_MY2023_Rx" SG_ 513 ChrgStat_D3_Dsply 1;
BA_ "U_P702_MY2024_Rx" SG_ 513 ChrgStat_D3_Dsply 1;
BA_ "MetaData" SG_ 148 VehYawWActl_D_Qf 1;
BA_ "GenSigStartValue" SG_ 148 VehYawWActl_D_Qf 1;
BA_ "MetaData" SG_ 148 VehRolWActl_D_Qf 1;
BA_ "GenSigStartValue" SG_ 148 VehRolWActl_D_Qf 1;
BA_ "MetaData" SG_ 148 VehRollYawW_No_Cs 1;
BA_ "MetaData" SG_ 148 VehRollYaw_No_Cnt 1;
BA_ "GenSigStartValue" SG_ 148 VehYaw_W_Actl 65534;
BA_ "U_V713N_MY2022_Rx" SG_ 148 VehYaw_W_Actl 1;
BA_ "U_V713AV_MY2022_Rx" SG_ 148 VehYaw_W_Actl 1;
BA_ "U_P708_MY2023_Rx" SG_ 148 VehYaw_W_Actl 1;
BA_ "U_V710_MY2023_Rx" SG_ 148 VehYaw_W_Actl 1;
BA_ "U_P702_MY2024_Rx" SG_ 148 VehYaw_W_Actl 1;
BA_ "GenSigStartValue" SG_ 148 VehRol_W_Actl 65534;
BA_ "U_V713N_MY2022_Rx" SG_ 1042 VehRol_An_Dsply 1;
BA_ "U_V713AV_MY2022_Rx" SG_ 1042 VehRol_An_Dsply 1;
BA_ "U_P708_MY2023_Rx" SG_ 1042 VehRol_An_Dsply 1;
BA_ "U_V710_MY2023_Rx" SG_ 1042 VehRol_An_Dsply 1;
BA_ "U_P702_MY2024_Rx" SG_ 1042 VehRol_An_Dsply 1;
BA_ "U_V713N_MY2022_Rx" SG_ 1042 VehPtch_An_Dsply 1;
BA_ "U_V713AV_MY2022_Rx" SG_ 1042 VehPtch_An_Dsply 1;
BA_ "U_P708_MY2023_Rx" SG_ 1042 VehPtch_An_Dsply 1;
BA_ "U_V710_MY2023_Rx" SG_ 1042 VehPtch_An_Dsply 1;
BA_ "U_P702_MY2024_Rx" SG_ 1042 VehPtch_An_Dsply 1;
BA_ "U_V713N_MY2022_Rx" SG_ 1042 TrlrBrk_Pc_Rq 1;
BA_ "U_V713AV_MY2022_Rx" SG_ 1042 TrlrBrk_Pc_Rq 1;
BA_ "U_P708_MY2023_Rx" SG_ 1042 TrlrBrk_Pc_Rq 1;
BA_ "U_P702_MY2024_Rx" SG_ 1042 TrlrBrk_Pc_Rq 1;
BA_ "U_V710_MY2023_Rx" SG_ 828 SpotLghtRight_D_Stat 1;
BA_ "U_P708_MY2023_Rx" SG_ 828 SpotLghtRight_D_Stat 1;
BA_ "U_P702_MY2024_Rx" SG_ 828 SpotLghtRight_D_Stat 1;
BA_ "WakeupSignal" SG_ 828 RearPassWindowPos 1;
BA_ "U_V713N_MY2022_Rx" SG_ 828 RearPassWindowPos 1;
BA_ "U_V713AV_MY2022_Rx" SG_ 828 RearPassWindowPos 1;
BA_ "U_P708_MY2023_Rx" SG_ 828 RearPassWindowPos 1;
BA_ "U_CDX74X_MY2024_Rx" SG_ 828 RearPassWindowPos 1;
BA_ "U_V710_MY2023_Rx" SG_ 828 RearPassWindowPos 1;
BA_ "U_P702_MY2024_Rx" SG_ 828 RearPassWindowPos 1;
BA_ "WakeupSignal" SG_ 828 PassWindowPosition 1;
BA_ "U_V713N_MY2022_Rx" SG_ 828 PassWindowPosition 1;
BA_ "U_P708_MY2023_Rx" SG_ 828 PassWindowPosition 1;
BA_ "U_CDX74X_MY2024_Rx" SG_ 828 PassWindowPosition 1;
BA_ "U_V710_MY2023_Rx" SG_ 828 PassWindowPosition 1;
BA_ "U_P702_MY2024_Rx" SG_ 828 PassWindowPosition 1;
BA_ "U_V713AV_MY2022_Rx" SG_ 828 PassWindowPosition 1;
BA_ "U_V710_MY2023_Rx" SG_ 828 SpotLghtLeft_D_Stat 1;
BA_ "U_P708_MY2023_Rx" SG_ 828 SpotLghtLeft_D_Stat 1;
BA_ "U_P702_MY2024_Rx" SG_ 828 SpotLghtLeft_D_Stat 1;
BA_ "U_V713N_MY2022_Rx" SG_ 330 TrnAout_W_ActlUnfilt 1;
BA_ "U_V713AV_MY2022_Rx" SG_ 330 TrnAout_W_ActlUnfilt 1;
BA_ "U_V710_MY2023_Rx" SG_ 330 TrnAout_W_ActlUnfilt 1;
BA_ "U_V713N_MY2022_Rx" SG_ 512 PtDrvMde_D_Stat 1;
BA_ "U_V713AV_MY2022_Rx" SG_ 512 PtDrvMde_D_Stat 1;
BA_ "U_P708_MY2023_Rx" SG_ 512 PtDrvMde_D_Stat 1;
BA_ "U_V710_MY2023_Rx" SG_ 512 PtDrvMde_D_Stat 1;
BA_ "U_P702_MY2024_Rx" SG_ 512 PtDrvMde_D_Stat 1;
BA_ "MetaData" SG_ 512 PrplWhlTotTqRq_No_Cs 1;
BA_ "MetaData" SG_ 512 PrplWhlTotTqRq_No_Cnt 1;
BA_ "MetaData" SG_ 862 ApaSwtch_No_Cnt 1;
BA_ "U_V713N_MY2022_Rx" SG_ 862 HvacBlwrFront_D_Stat 1;
BA_ "U_P708_MY2023_Rx" SG_ 862 HvacBlwrFront_D_Stat 1;
BA_ "U_CDX74X_MY2024_Rx" SG_ 862 HvacBlwrFront_D_Stat 1;
BA_ "U_V710_MY2023_Rx" SG_ 862 HvacBlwrFront_D_Stat 1;
BA_ "U_P702_MY2024_Rx" SG_ 862 HvacBlwrFront_D_Stat 1;
BA_ "U_V713N_MY2022_Rx" SG_ 862 HvacBlwrRear_D_Stat 1;
BA_ "U_P708_MY2023_Rx" SG_ 862 HvacBlwrRear_D_Stat 1;
BA_ "U_CDX74X_MY2024_Rx" SG_ 862 HvacBlwrRear_D_Stat 1;
BA_ "U_V710_MY2023_Rx" SG_ 862 HvacBlwrRear_D_Stat 1;
BA_ "U_P702_MY2024_Rx" SG_ 862 HvacBlwrRear_D_Stat 1;
BA_ "GenSigStartValue" SG_ 862 ClimtThrmlLoad_No_Actl 255;
BA_ "U_V713N_MY2022_Rx" SG_ 862 CabnAmb_Te_Actl 1;
BA_ "U_V713AV_MY2022_Rx" SG_ 862 CabnAmb_Te_Actl 1;
BA_ "U_P708_MY2023_Rx" SG_ 862 CabnAmb_Te_Actl 1;
BA_ "U_CDX74X_MY2024_Rx" SG_ 862 CabnAmb_Te_Actl 1;
BA_ "U_V710_MY2023_Rx" SG_ 862 CabnAmb_Te_Actl 1;
BA_ "U_P702_MY2024_Rx" SG_ 862 CabnAmb_Te_Actl 1;
BA_ "ECGUsedRxSignal" SG_ 862 CabnAmb_Te_Actl 1;
BA_ "WakeupSignal" SG_ 831 PassMirrorCmd 1;
BA_ "WakeupSignal" SG_ 831 RearPassWindowCmd 1;
BA_ "WakeupSignal" SG_ 831 PassWindowCmd 1;
BA_ "WakeupSignal" SG_ 831 RearDriverWindowPos 1;
BA_ "U_V713N_MY2022_Rx" SG_ 831 RearDriverWindowPos 1;
BA_ "U_V713AV_MY2022_Rx" SG_ 831 RearDriverWindowPos 1;
BA_ "U_P708_MY2023_Rx" SG_ 831 RearDriverWindowPos 1;
BA_ "U_CDX74X_MY2024_Rx" SG_ 831 RearDriverWindowPos 1;
BA_ "U_V710_MY2023_Rx" SG_ 831 RearDriverWindowPos 1;
BA_ "U_P702_MY2024_Rx" SG_ 831 RearDriverWindowPos 1;
BA_ "WakeupSignal" SG_ 831 DriverWindowPosition 1;
BA_ "U_V713N_MY2022_Rx" SG_ 831 DriverWindowPosition 1;
BA_ "U_V713AV_MY2022_Rx" SG_ 831 DriverWindowPosition 1;
BA_ "U_P708_MY2023_Rx" SG_ 831 DriverWindowPosition 1;
BA_ "U_CDX74X_MY2024_Rx" SG_ 831 DriverWindowPosition 1;
BA_ "U_V710_MY2023_Rx" SG_ 831 DriverWindowPosition 1;
BA_ "U_P702_MY2024_Rx" SG_ 831 DriverWindowPosition 1;
BA_ "MetaData" SG_ 331 TrnAout2ActUflt_No_Cnt 1;
BA_ "MetaData" SG_ 331 TrnAout2ActlUflt_No_Cs 1;
BA_ "GenSigStartValue" SG_ 331 TrnAout2_W_ActlUnfilt 65534;
BA_ "U_V710_MY2023_Rx" SG_ 331 TrnAout2_W_ActlUnfilt 1;
BA_ "U_P702_MY2024_Rx" SG_ 331 TrnAout2_W_ActlUnfilt 1;
BA_ "U_P702_MY2024_Rx" SG_ 965 TrnkFrontPrim_B_Falt 1;
BA_ "WakeupSignal" SG_ 965 TrnkFrontEmgcy_D_Stat 1;
BA_ "GenSigStartValue" SG_ 965 TrnkFrontEmgcy_D_Stat 3;
BA_ "U_V710_MY2023_Rx" SG_ 965 TrnkFrontEmgcy_D_Stat 1;
BA_ "U_P702_MY2024_Rx" SG_ 965 TrnkFrontEmgcy_D_Stat 1;
BA_ "WakeupSignal" SG_ 965 PtWakeupActv4_B_Rq 1;
BA_ "WakeupSignal" SG_ 965 TrunkFrontOpen_D_Stat 1;
BA_ "GenSigStartValue" SG_ 965 TrunkFrontOpen_D_Stat 2;
BA_ "U_P708_MY2023_Rx" SG_ 965 TrunkFrontOpen_D_Stat 1;
BA_ "U_V710_MY2023_Rx" SG_ 965 TrunkFrontOpen_D_Stat 1;
BA_ "U_P702_MY2024_Rx" SG_ 965 TrunkFrontOpen_D_Stat 1;
BA_ "WakeupSignal" SG_ 965 TrunkFrontRolCd_No_Locl 1;
BA_ "GenSigSendType" SG_ 1242 EngExhMdeQuietCstm_D_Rq 3;
BA_ "U_P708_MY2023_Rx" SG_ 1242 EngExhMdeQuietCstm_D_Rq 1;
BA_ "ECGUsedTxSignal" SG_ 1242 EngExhMdeQuietCstm_D_Rq 1;
BA_ "U_CDX74X_MY2024_Tx" SG_ 1242 EngExhMdeQuietCstm_D_Rq 1;
BA_ "U_V710_MY2023_Tx" SG_ 1242 EngExhMdeQuietCstm_D_Rq 1;
BA_ "GenSigSendType" SG_ 1242 StopStrtCstm_D_Rq 3;
BA_ "U_P708_MY2023_Rx" SG_ 1242 StopStrtCstm_D_Rq 1;
BA_ "ECGUsedTxSignal" SG_ 1242 StopStrtCstm_D_Rq 1;
BA_ "U_CDX74X_MY2024_Tx" SG_ 1242 StopStrtCstm_D_Rq 1;
BA_ "U_V710_MY2023_Tx" SG_ 1242 StopStrtCstm_D_Rq 1;
BA_ "GenSigSendType" SG_ 1242 SelDrvMdeCstmPt_D_Rq 3;
BA_ "ECGUsedTxSignal" SG_ 1242 SelDrvMdeCstmPt_D_Rq 1;
BA_ "U_CDX74X_MY2024_Tx" SG_ 1242 SelDrvMdeCstmPt_D_Rq 1;
BA_ "U_V710_MY2023_Tx" SG_ 1242 SelDrvMdeCstmPt_D_Rq 1;
BA_ "GenSigSendType" SG_ 1245 RearDiffLckLamp_D_Cstm 3;
BA_ "U_P708_MY2023_Rx" SG_ 1245 RearDiffLckLamp_D_Cstm 1;
BA_ "ECGUsedTxSignal" SG_ 1245 RearDiffLckLamp_D_Cstm 1;
BA_ "U_CDX74X_MY2024_Tx" SG_ 1245 RearDiffLckLamp_D_Cstm 1;
BA_ "U_V710_MY2023_Tx" SG_ 1245 RearDiffLckLamp_D_Cstm 1;
BA_ "GenSigSendType" SG_ 1245 FrontDiffLckLamp_D_Cstm 3;
BA_ "U_P708_MY2023_Rx" SG_ 1245 FrontDiffLckLamp_D_Cstm 1;
BA_ "ECGUsedTxSignal" SG_ 1245 FrontDiffLckLamp_D_Cstm 1;
BA_ "U_CDX74X_MY2024_Tx" SG_ 1245 FrontDiffLckLamp_D_Cstm 1;
BA_ "U_V710_MY2023_Tx" SG_ 1245 FrontDiffLckLamp_D_Cstm 1;
BA_ "GenSigSendType" SG_ 1245 AwdMdeCstm_D_RqDrv 3;
BA_ "U_P708_MY2023_Rx" SG_ 1245 AwdMdeCstm_D_RqDrv 1;
BA_ "ECGUsedTxSignal" SG_ 1245 AwdMdeCstm_D_RqDrv 1;
BA_ "U_CDX74X_MY2024_Tx" SG_ 1245 AwdMdeCstm_D_RqDrv 1;
BA_ "U_V710_MY2023_Tx" SG_ 1245 AwdMdeCstm_D_RqDrv 1;
BA_ "GenSigStartValue" SG_ 1245 SelDrvMdeAwd2_D_Cstm 31;
BA_ "GenSigSendType" SG_ 1245 SelDrvMdeAwd2_D_Cstm 3;
BA_ "ECGUsedTxSignal" SG_ 1245 SelDrvMdeAwd2_D_Cstm 1;
BA_ "U_CDX74X_MY2024_Tx" SG_ 1245 SelDrvMdeAwd2_D_Cstm 1;
BA_ "U_V710_MY2023_Tx" SG_ 1245 SelDrvMdeAwd2_D_Cstm 1;
BA_ "U_P708_MY2023_Rx" SG_ 781 TrlrTireDual_D_Stat 1;
BA_ "U_V713AV_MY2022_Rx" SG_ 781 TrlrTireDual_D_Stat 1;
BA_ "U_V710_MY2023_Rx" SG_ 781 TrlrTireDual_D_Stat 1;
BA_ "U_P702_MY2024_Rx" SG_ 781 TrlrTireDual_D_Stat 1;
BA_ "U_P708_MY2023_Rx" SG_ 781 TrlrTireThresh_D_Stat 1;
BA_ "U_V710_MY2023_Rx" SG_ 781 TrlrTireThresh_D_Stat 1;
BA_ "U_P702_MY2024_Rx" SG_ 781 TrlrTireThresh_D_Stat 1;
BA_ "U_P708_MY2023_Rx" SG_ 781 TrlrTireSys_D_Stat 1;
BA_ "U_V710_MY2023_Rx" SG_ 781 TrlrTireSys_D_Stat 1;
BA_ "U_P702_MY2024_Rx" SG_ 781 TrlrTireSys_D_Stat 1;
BA_ "U_P708_MY2023_Rx" SG_ 781 TrlrTireCnt_D_Stat 1;
BA_ "U_V710_MY2023_Rx" SG_ 781 TrlrTireCnt_D_Stat 1;
BA_ "U_P702_MY2024_Rx" SG_ 781 TrlrTireCnt_D_Stat 1;
BA_ "U_P708_MY2023_Rx" SG_ 781 ChirpRq_No_ActlTrlr 1;
BA_ "U_V710_MY2023_Rx" SG_ 781 ChirpRq_No_ActlTrlr 1;
BA_ "U_P708_MY2023_Rx" SG_ 781 Chirp_D_RqTrlr 1;
BA_ "U_V710_MY2023_Rx" SG_ 781 Chirp_D_RqTrlr 1;
BA_ "U_P708_MY2023_Rx" SG_ 1022 TrlrTireTSensIRM_D_Stat 1;
BA_ "U_V710_MY2023_Rx" SG_ 1022 TrlrTireTSensIRM_D_Stat 1;
BA_ "U_P702_MY2024_Rx" SG_ 1022 TrlrTireTSensIRM_D_Stat 1;
BA_ "U_P708_MY2023_Rx" SG_ 1022 TrlrTireTSensIRF_D_Stat 1;
BA_ "U_V710_MY2023_Rx" SG_ 1022 TrlrTireTSensIRF_D_Stat 1;
BA_ "U_P702_MY2024_Rx" SG_ 1022 TrlrTireTSensIRF_D_Stat 1;
BA_ "GenSigStartValue" SG_ 1022 TrlrTireIRR_T_Actl 253;
BA_ "U_P708_MY2023_Rx" SG_ 1022 TrlrTireIRR_T_Actl 1;
BA_ "U_V710_MY2023_Rx" SG_ 1022 TrlrTireIRR_T_Actl 1;
BA_ "U_P702_MY2024_Rx" SG_ 1022 TrlrTireIRR_T_Actl 1;
BA_ "GenSigStartValue" SG_ 1022 TrlrTireIRM_T_Actl 253;
BA_ "U_P708_MY2023_Rx" SG_ 1022 TrlrTireIRM_T_Actl 1;
BA_ "U_V710_MY2023_Rx" SG_ 1022 TrlrTireIRM_T_Actl 1;
BA_ "U_P702_MY2024_Rx" SG_ 1022 TrlrTireIRM_T_Actl 1;
BA_ "GenSigStartValue" SG_ 1022 TrlrTireILR_T_Actl 253;
BA_ "U_P708_MY2023_Rx" SG_ 1022 TrlrTireILR_T_Actl 1;
BA_ "U_V710_MY2023_Rx" SG_ 1022 TrlrTireILR_T_Actl 1;
BA_ "U_P702_MY2024_Rx" SG_ 1022 TrlrTireILR_T_Actl 1;
BA_ "GenSigStartValue" SG_ 1022 TrlrTireILM_T_Actl 253;
BA_ "U_P708_MY2023_Rx" SG_ 1022 TrlrTireILM_T_Actl 1;
BA_ "U_V710_MY2023_Rx" SG_ 1022 TrlrTireILM_T_Actl 1;
BA_ "U_P702_MY2024_Rx" SG_ 1022 TrlrTireILM_T_Actl 1;
BA_ "GenSigStartValue" SG_ 1022 TrlrTireILF_T_Actl 253;
BA_ "U_P708_MY2023_Rx" SG_ 1022 TrlrTireILF_T_Actl 1;
BA_ "U_V710_MY2023_Rx" SG_ 1022 TrlrTireILF_T_Actl 1;
BA_ "U_P702_MY2024_Rx" SG_ 1022 TrlrTireILF_T_Actl 1;
BA_ "GenSigStartValue" SG_ 1022 TrlrTireIRF_T_Actl 253;
BA_ "U_P708_MY2023_Rx" SG_ 1022 TrlrTireIRF_T_Actl 1;
BA_ "U_V710_MY2023_Rx" SG_ 1022 TrlrTireIRF_T_Actl 1;
BA_ "U_P702_MY2024_Rx" SG_ 1022 TrlrTireIRF_T_Actl 1;
BA_ "U_P708_MY2023_Rx" SG_ 1022 TrlrTireTSensIRR_D_Stat 1;
BA_ "U_V710_MY2023_Rx" SG_ 1022 TrlrTireTSensIRR_D_Stat 1;
BA_ "U_P702_MY2024_Rx" SG_ 1022 TrlrTireTSensIRR_D_Stat 1;
BA_ "U_P708_MY2023_Rx" SG_ 1022 TrlrTireTSensILR_D_Stat 1;
BA_ "U_V710_MY2023_Rx" SG_ 1022 TrlrTireTSensILR_D_Stat 1;
BA_ "U_P702_MY2024_Rx" SG_ 1022 TrlrTireTSensILR_D_Stat 1;
BA_ "U_P708_MY2023_Rx" SG_ 1022 TrlrTireTSensILM_D_Stat 1;
BA_ "U_V710_MY2023_Rx" SG_ 1022 TrlrTireTSensILM_D_Stat 1;
BA_ "U_P702_MY2024_Rx" SG_ 1022 TrlrTireTSensILM_D_Stat 1;
BA_ "U_P708_MY2023_Rx" SG_ 1022 TrlrTireTSensILF_D_Stat 1;
BA_ "U_V710_MY2023_Rx" SG_ 1022 TrlrTireTSensILF_D_Stat 1;
BA_ "U_P702_MY2024_Rx" SG_ 1022 TrlrTireTSensILF_D_Stat 1;
BA_ "U_P708_MY2023_Rx" SG_ 903 AprSnd_D_Rq 1;
BA_ "U_V710_MY2023_Rx" SG_ 903 AprSnd_D_Rq 1;
BA_ "U_P708_MY2023_Rx" SG_ 901 AplSnd_D_Rq 1;
BA_ "U_V710_MY2023_Rx" SG_ 901 AplSnd_D_Rq 1;
BA_ "GenSigStartValue" SG_ 1112 BattTrac2_E_Max 4094;
BA_ "U_V710_MY2023_Rx" SG_ 1112 BattTrac2_E_Max 1;
BA_ "U_P708_MY2023_Rx" SG_ 1112 BattTrac2_E_Max 1;
BA_ "U_P702_MY2024_Rx" SG_ 1112 BattTrac2_E_Max 1;
BA_ "U_V710_MY2023_Rx" SG_ 1112 BattTrac2_E_Avail 1;
BA_ "U_P708_MY2023_Rx" SG_ 1112 BattTrac2_E_Avail 1;
BA_ "U_P702_MY2024_Rx" SG_ 1112 BattTrac2_E_Avail 1;
BA_ "GenSigStartValue" SG_ 1112 BattTracDelta_Te_Actl 254;
BA_ "U_P708_MY2023_Rx" SG_ 1112 BattTracHazrd_D_Stat 1;
BA_ "U_V710_MY2023_Rx" SG_ 1112 BattTracHazrd_D_Stat 1;
BA_ "U_P702_MY2024_Rx" SG_ 1112 BattTracHazrd_D_Stat 1;
BA_ "MetaData" SG_ 977 CnvtTop_No_Cnt 1;
BA_ "WakeupSignal" SG_ 977 CnvtTopPos_Up_Stat 1;
BA_ "U_V713N_MY2022_Rx" SG_ 977 CnvtTopPos_Up_Stat 1;
BA_ "U_V713AV_MY2022_Rx" SG_ 977 CnvtTopPos_Up_Stat 1;
BA_ "U_V710_MY2023_Rx" SG_ 977 CnvtTopPos_Up_Stat 1;
BA_ "WakeupSignal" SG_ 977 CnvtTopMsgTxt_D_Rq 1;
BA_ "U_P708_MY2023_Rx" SG_ 977 CnvtTopMsgTxt_D_Rq 1;
BA_ "U_V710_MY2023_Rx" SG_ 977 CnvtTopMsgTxt_D_Rq 1;
BA_ "WakeupSignal" SG_ 977 CnvtTopPos_Dn_Stat 1;
BA_ "U_V713N_MY2022_Rx" SG_ 977 CnvtTopPos_Dn_Stat 1;
BA_ "U_V713AV_MY2022_Rx" SG_ 977 CnvtTopPos_Dn_Stat 1;
BA_ "U_V710_MY2023_Rx" SG_ 977 CnvtTopPos_Dn_Stat 1;
BA_ "U_P708_MY2023_Rx" SG_ 969 Dimming_Level_Stat 1;
BA_ "U_V710_MY2023_Rx" SG_ 969 Dimming_Level_Stat 1;
BA_ "U_P702_MY2024_Rx" SG_ 969 Dimming_Level_Stat 1;
BA_ "GenSigStartValue" SG_ 969 Current_Color_Stat 8;
BA_ "U_P708_MY2023_Rx" SG_ 969 Current_Color_Stat 1;
BA_ "U_V710_MY2023_Rx" SG_ 969 Current_Color_Stat 1;
BA_ "U_P702_MY2024_Rx" SG_ 969 Current_Color_Stat 1;
BA_ "U_P708_MY2023_Rx" SG_ 969 BlendedColorRed_Stat 1;
BA_ "U_V710_MY2023_Rx" SG_ 969 BlendedColorRed_Stat 1;
BA_ "U_P702_MY2024_Rx" SG_ 969 BlendedColorRed_Stat 1;
BA_ "U_P708_MY2023_Rx" SG_ 969 BlendedColorGreen_Stat 1;
BA_ "U_V710_MY2023_Rx" SG_ 969 BlendedColorGreen_Stat 1;
BA_ "U_P702_MY2024_Rx" SG_ 969 BlendedColorGreen_Stat 1;
BA_ "U_P708_MY2023_Rx" SG_ 969 BlendedColorBlue_Stat 1;
BA_ "U_V710_MY2023_Rx" SG_ 969 BlendedColorBlue_Stat 1;
BA_ "U_P702_MY2024_Rx" SG_ 969 BlendedColorBlue_Stat 1;
BA_ "GenSigStartValue" SG_ 969 BlendedColor_Stat 2;
BA_ "U_P708_MY2023_Rx" SG_ 969 BlendedColor_Stat 1;
BA_ "U_V710_MY2023_Rx" SG_ 969 BlendedColor_Stat 1;
BA_ "U_P702_MY2024_Rx" SG_ 969 BlendedColor_Stat 1;
BA_ "WakeupSignal" SG_ 969 TurnLampRrOut_B_Stat 1;
BA_ "WakeupSignal" SG_ 969 TurnLampRlOut_B_Stat 1;
BA_ "U_V713N_MY2022_Rx" SG_ 530 PiCode_No_Rq 1;
BA_ "U_V713AV_MY2022_Rx" SG_ 530 PiCode_No_Rq 1;
BA_ "U_P708_MY2023_Rx" SG_ 530 PiCode_No_Rq 1;
BA_ "U_V710_MY2023_Rx" SG_ 530 PiCode_No_Rq 1;
BA_ "U_P708_MY2023_Tx" SG_ 530 PiCode_No_Rq 1;
BA_ "GenSigSendType" SG_ 530 StationTypeSel_D_Rq 3;
BA_ "U_V713N_MY2022_Rx" SG_ 530 StationTypeSel_D_Rq 1;
BA_ "U_V713AV_MY2022_Rx" SG_ 530 StationTypeSel_D_Rq 1;
BA_ "U_P708_MY2023_Rx" SG_ 530 StationTypeSel_D_Rq 1;
BA_ "U_V710_MY2023_Rx" SG_ 530 StationTypeSel_D_Rq 1;
BA_ "U_P708_MY2023_Tx" SG_ 530 StationTypeSel_D_Rq 1;
BA_ "U_V713N_MY2022_Rx" SG_ 530 DabExtndCntryCode_No_Rq 1;
BA_ "U_V713AV_MY2022_Rx" SG_ 530 DabExtndCntryCode_No_Rq 1;
BA_ "U_P708_MY2023_Rx" SG_ 530 DabExtndCntryCode_No_Rq 1;
BA_ "U_V710_MY2023_Rx" SG_ 530 DabExtndCntryCode_No_Rq 1;
BA_ "U_P708_MY2023_Tx" SG_ 530 DabExtndCntryCode_No_Rq 1;
BA_ "U_V713N_MY2022_Rx" SG_ 530 DabStationCodeId_No_Rq 1;
BA_ "U_V713AV_MY2022_Rx" SG_ 530 DabStationCodeId_No_Rq 1;
BA_ "U_P708_MY2023_Rx" SG_ 530 DabStationCodeId_No_Rq 1;
BA_ "U_V710_MY2023_Rx" SG_ 530 DabStationCodeId_No_Rq 1;
BA_ "U_P708_MY2023_Tx" SG_ 530 DabStationCodeId_No_Rq 1;
BA_ "U_V713N_MY2022_Rx" SG_ 530 DabStationId_No_Rq 1;
BA_ "U_V713AV_MY2022_Rx" SG_ 530 DabStationId_No_Rq 1;
BA_ "U_P708_MY2023_Rx" SG_ 530 DabStationId_No_Rq 1;
BA_ "U_V710_MY2023_Rx" SG_ 530 DabStationId_No_Rq 1;
BA_ "U_P708_MY2023_Tx" SG_ 530 DabStationId_No_Rq 1;
BA_ "GenSigSendType" SG_ 746 Con_BTAud_Shuffle_St 3;
BA_ "U_V713N_MY2022_Tx" SG_ 746 Con_BTAud_Shuffle_St 1;
BA_ "U_V713AV_MY2022_Tx" SG_ 746 Con_BTAud_Shuffle_St 1;
BA_ "GenSigSendType" SG_ 746 Con_BTAud_Repeat_St 3;
BA_ "U_V713N_MY2022_Tx" SG_ 746 Con_BTAud_Repeat_St 1;
BA_ "U_V713AV_MY2022_Tx" SG_ 746 Con_BTAud_Repeat_St 1;
BA_ "GenSigSendType" SG_ 746 Con_BTAud_IntroScan_St 3;
BA_ "U_V713N_MY2022_Tx" SG_ 746 Con_BTAud_IntroScan_St 1;
BA_ "U_V713AV_MY2022_Tx" SG_ 746 Con_BTAud_IntroScan_St 1;
BA_ "GenSigSendType" SG_ 746 Con_BTAud_ActTrNum1_St 3;
BA_ "U_V713N_MY2022_Tx" SG_ 746 Con_BTAud_ActTrNum1_St 1;
BA_ "U_V713AV_MY2022_Tx" SG_ 746 Con_BTAud_ActTrNum1_St 1;
BA_ "GenSigSendType" SG_ 746 Con_ShowBTPINNumb_St 3;
BA_ "U_V713N_MY2022_Tx" SG_ 746 Con_ShowBTPINNumb_St 1;
BA_ "U_V713AV_MY2022_Tx" SG_ 746 Con_ShowBTPINNumb_St 1;
BA_ "GenSigSendType" SG_ 746 Con_BTAud_Error_St 3;
BA_ "U_V713N_MY2022_Tx" SG_ 746 Con_BTAud_Error_St 1;
BA_ "U_V713AV_MY2022_Tx" SG_ 746 Con_BTAud_Error_St 1;
BA_ "GenSigSendType" SG_ 746 Con_BTAud_FunctStats_St 3;
BA_ "U_V713N_MY2022_Tx" SG_ 746 Con_BTAud_FunctStats_St 1;
BA_ "U_V713AV_MY2022_Tx" SG_ 746 Con_BTAud_FunctStats_St 1;
BA_ "GenSigSendType" SG_ 746 Con_BTAud_OpMode_St 3;
BA_ "U_V713N_MY2022_Tx" SG_ 746 Con_BTAud_OpMode_St 1;
BA_ "U_V713AV_MY2022_Tx" SG_ 746 Con_BTAud_OpMode_St 1;
BA_ "GenSigStartValue" SG_ 479 DISP_SetVolume_Rq 30;
BA_ "GenSigSendType" SG_ 479 DISP_SetVolume_Rq 3;
BA_ "U_V713N_MY2022_Rx" SG_ 479 DISP_SetVolume_Rq 1;
BA_ "U_V713AV_MY2022_Rx" SG_ 479 DISP_SetVolume_Rq 1;
BA_ "U_P708_MY2023_Rx" SG_ 479 DISP_SetVolume_Rq 1;
BA_ "U_V710_MY2023_Rx" SG_ 479 DISP_SetVolume_Rq 1;
BA_ "U_CDX74X_MY2024_Rx" SG_ 479 DISP_SetVolume_Rq 1;
BA_ "U_V710_MY2023_Tx" SG_ 479 DISP_SetVolume_Rq 1;
BA_ "U_P708_MY2023_Tx" SG_ 479 DISP_SetVolume_Rq 1;
BA_ "U_P702_MY2024_Tx" SG_ 479 DISP_SetVolume_Rq 1;
BA_ "GenSigSendType" SG_ 479 DISP_SetVol_Source_Rq 3;
BA_ "U_V710_MY2023_Rx" SG_ 479 DISP_SetVol_Source_Rq 1;
BA_ "U_V713N_MY2022_Rx" SG_ 479 DISP_SetVol_Source_Rq 1;
BA_ "U_V713AV_MY2022_Rx" SG_ 479 DISP_SetVol_Source_Rq 1;
BA_ "U_P708_MY2023_Rx" SG_ 479 DISP_SetVol_Source_Rq 1;
BA_ "U_V710_MY2023_Tx" SG_ 479 DISP_SetVol_Source_Rq 1;
BA_ "U_P708_MY2023_Tx" SG_ 479 DISP_SetVol_Source_Rq 1;
BA_ "U_P702_MY2024_Tx" SG_ 479 DISP_SetVol_Source_Rq 1;
BA_ "U_V710_MY2023_Rx" SG_ 479 DISP_SetVol_Level_Rq 1;
BA_ "U_V713N_MY2022_Rx" SG_ 479 DISP_SetVol_Level_Rq 1;
BA_ "U_V713AV_MY2022_Rx" SG_ 479 DISP_SetVol_Level_Rq 1;
BA_ "U_P708_MY2023_Rx" SG_ 479 DISP_SetVol_Level_Rq 1;
BA_ "U_V710_MY2023_Tx" SG_ 479 DISP_SetVol_Level_Rq 1;
BA_ "U_P708_MY2023_Tx" SG_ 479 DISP_SetVol_Level_Rq 1;
BA_ "U_P702_MY2024_Tx" SG_ 479 DISP_SetVol_Level_Rq 1;
BA_ "GenSigSendType" SG_ 479 DISP_Setshaker_Rq 3;
BA_ "U_V710_MY2023_Rx" SG_ 479 DISP_Setshaker_Rq 1;
BA_ "U_V713N_MY2022_Rx" SG_ 479 DISP_Setshaker_Rq 1;
BA_ "U_V713AV_MY2022_Rx" SG_ 479 DISP_Setshaker_Rq 1;
BA_ "U_P708_MY2023_Rx" SG_ 479 DISP_Setshaker_Rq 1;
BA_ "U_V710_MY2023_Tx" SG_ 479 DISP_Setshaker_Rq 1;
BA_ "U_P708_MY2023_Tx" SG_ 479 DISP_Setshaker_Rq 1;
BA_ "U_P702_MY2024_Tx" SG_ 479 DISP_Setshaker_Rq 1;
BA_ "U_V713N_MY2022_Rx" SG_ 474 Nav_SetCurrStatMCCh_Rq 1;
BA_ "U_V713AV_MY2022_Rx" SG_ 474 Nav_SetCurrStatMCCh_Rq 1;
BA_ "U_P708_MY2023_Rx" SG_ 474 Nav_SetCurrStatMCCh_Rq 1;
BA_ "U_V710_MY2023_Rx" SG_ 474 Nav_SetCurrStatMCCh_Rq 1;
BA_ "U_V710_MY2023_Tx" SG_ 474 Nav_SetCurrStatMCCh_Rq 1;
BA_ "U_P708_MY2023_Tx" SG_ 474 Nav_SetCurrStatMCCh_Rq 1;
BA_ "U_P702_MY2024_Tx" SG_ 474 Nav_SetCurrStatMCCh_Rq 1;
BA_ "GenSigSendType" SG_ 474 NAV_SetNEWSMode_Rq 3;
BA_ "U_V713N_MY2022_Rx" SG_ 474 NAV_SetNEWSMode_Rq 1;
BA_ "U_V713AV_MY2022_Rx" SG_ 474 NAV_SetNEWSMode_Rq 1;
BA_ "U_P708_MY2023_Rx" SG_ 474 NAV_SetNEWSMode_Rq 1;
BA_ "U_V710_MY2023_Rx" SG_ 474 NAV_SetNEWSMode_Rq 1;
BA_ "U_V710_MY2023_Tx" SG_ 474 NAV_SetNEWSMode_Rq 1;
BA_ "U_P708_MY2023_Tx" SG_ 474 NAV_SetNEWSMode_Rq 1;
BA_ "U_P702_MY2024_Tx" SG_ 474 NAV_SetNEWSMode_Rq 1;
BA_ "GenSigStartValue" SG_ 474 NAV_SetMid_Rq 15;
BA_ "GenSigSendType" SG_ 474 NAV_SetMid_Rq 3;
BA_ "U_V713N_MY2022_Rx" SG_ 474 NAV_SetMid_Rq 1;
BA_ "U_V713AV_MY2022_Rx" SG_ 474 NAV_SetMid_Rq 1;
BA_ "U_P708_MY2023_Rx" SG_ 474 NAV_SetMid_Rq 1;
BA_ "U_V710_MY2023_Rx" SG_ 474 NAV_SetMid_Rq 1;
BA_ "U_V710_MY2023_Tx" SG_ 474 NAV_SetMid_Rq 1;
BA_ "U_P708_MY2023_Tx" SG_ 474 NAV_SetMid_Rq 1;
BA_ "U_P702_MY2024_Tx" SG_ 474 NAV_SetMid_Rq 1;
BA_ "GenSigSendType" SG_ 474 NAV_SetDSP_Rq 3;
BA_ "U_V713N_MY2022_Rx" SG_ 474 NAV_SetDSP_Rq 1;
BA_ "U_V713AV_MY2022_Rx" SG_ 474 NAV_SetDSP_Rq 1;
BA_ "U_P708_MY2023_Rx" SG_ 474 NAV_SetDSP_Rq 1;
BA_ "U_V710_MY2023_Rx" SG_ 474 NAV_SetDSP_Rq 1;
BA_ "U_V710_MY2023_Tx" SG_ 474 NAV_SetDSP_Rq 1;
BA_ "U_P708_MY2023_Tx" SG_ 474 NAV_SetDSP_Rq 1;
BA_ "U_P702_MY2024_Tx" SG_ 474 NAV_SetDSP_Rq 1;
BA_ "U_V713N_MY2022_Rx" SG_ 474 NAV_SetCurrStatFreq_Rq 1;
BA_ "U_V713AV_MY2022_Rx" SG_ 474 NAV_SetCurrStatFreq_Rq 1;
BA_ "U_P708_MY2023_Rx" SG_ 474 NAV_SetCurrStatFreq_Rq 1;
BA_ "U_V710_MY2023_Rx" SG_ 474 NAV_SetCurrStatFreq_Rq 1;
BA_ "U_V710_MY2023_Tx" SG_ 474 NAV_SetCurrStatFreq_Rq 1;
BA_ "U_P708_MY2023_Tx" SG_ 474 NAV_SetCurrStatFreq_Rq 1;
BA_ "U_P702_MY2024_Tx" SG_ 474 NAV_SetCurrStatFreq_Rq 1;
BA_ "GenSigSendType" SG_ 474 NAV_SetCurrentStatOp_Rq 3;
BA_ "U_V713N_MY2022_Rx" SG_ 474 NAV_SetCurrentStatOp_Rq 1;
BA_ "U_V713AV_MY2022_Rx" SG_ 474 NAV_SetCurrentStatOp_Rq 1;
BA_ "U_P708_MY2023_Rx" SG_ 474 NAV_SetCurrentStatOp_Rq 1;
BA_ "U_V710_MY2023_Rx" SG_ 474 NAV_SetCurrentStatOp_Rq 1;
BA_ "U_V710_MY2023_Tx" SG_ 474 NAV_SetCurrentStatOp_Rq 1;
BA_ "U_P708_MY2023_Tx" SG_ 474 NAV_SetCurrentStatOp_Rq 1;
BA_ "U_P702_MY2024_Tx" SG_ 474 NAV_SetCurrentStatOp_Rq 1;
BA_ "U_V713N_MY2022_Rx" SG_ 474 NAV_SetCurrentPICode_Rq 1;
BA_ "U_V713AV_MY2022_Rx" SG_ 474 NAV_SetCurrentPICode_Rq 1;
BA_ "U_P708_MY2023_Rx" SG_ 474 NAV_SetCurrentPICode_Rq 1;
BA_ "U_V710_MY2023_Rx" SG_ 474 NAV_SetCurrentPICode_Rq 1;
BA_ "U_V710_MY2023_Tx" SG_ 474 NAV_SetCurrentPICode_Rq 1;
BA_ "U_P708_MY2023_Tx" SG_ 474 NAV_SetCurrentPICode_Rq 1;
BA_ "U_P702_MY2024_Tx" SG_ 474 NAV_SetCurrentPICode_Rq 1;
BA_ "U_V713N_MY2022_Rx" SG_ 474 NAV_ARReqstrSystem_Rq 1;
BA_ "U_V713AV_MY2022_Rx" SG_ 474 NAV_ARReqstrSystem_Rq 1;
BA_ "U_P708_MY2023_Rx" SG_ 474 NAV_ARReqstrSystem_Rq 1;
BA_ "U_V710_MY2023_Rx" SG_ 474 NAV_ARReqstrSystem_Rq 1;
BA_ "U_V710_MY2023_Tx" SG_ 474 NAV_ARReqstrSystem_Rq 1;
BA_ "U_P708_MY2023_Tx" SG_ 474 NAV_ARReqstrSystem_Rq 1;
BA_ "U_P702_MY2024_Tx" SG_ 474 NAV_ARReqstrSystem_Rq 1;
BA_ "U_V713N_MY2022_Rx" SG_ 474 NAV_ARReqstrPriority_Rq 1;
BA_ "U_V713AV_MY2022_Rx" SG_ 474 NAV_ARReqstrPriority_Rq 1;
BA_ "U_P708_MY2023_Rx" SG_ 474 NAV_ARReqstrPriority_Rq 1;
BA_ "U_V710_MY2023_Rx" SG_ 474 NAV_ARReqstrPriority_Rq 1;
BA_ "U_V710_MY2023_Tx" SG_ 474 NAV_ARReqstrPriority_Rq 1;
BA_ "U_P708_MY2023_Tx" SG_ 474 NAV_ARReqstrPriority_Rq 1;
BA_ "U_P702_MY2024_Tx" SG_ 474 NAV_ARReqstrPriority_Rq 1;
BA_ "GenSigSendType" SG_ 474 NAV_AROperationType_Rq 3;
BA_ "U_V713N_MY2022_Rx" SG_ 474 NAV_AROperationType_Rq 1;
BA_ "U_V713AV_MY2022_Rx" SG_ 474 NAV_AROperationType_Rq 1;
BA_ "U_P708_MY2023_Rx" SG_ 474 NAV_AROperationType_Rq 1;
BA_ "U_V710_MY2023_Rx" SG_ 474 NAV_AROperationType_Rq 1;
BA_ "U_V710_MY2023_Tx" SG_ 474 NAV_AROperationType_Rq 1;
BA_ "U_P708_MY2023_Tx" SG_ 474 NAV_AROperationType_Rq 1;
BA_ "U_P702_MY2024_Tx" SG_ 474 NAV_AROperationType_Rq 1;
BA_ "U_V713N_MY2022_Rx" SG_ 474 NAV_ARAudioSource_Rq 1;
BA_ "U_V713AV_MY2022_Rx" SG_ 474 NAV_ARAudioSource_Rq 1;
BA_ "U_P708_MY2023_Rx" SG_ 474 NAV_ARAudioSource_Rq 1;
BA_ "U_V710_MY2023_Rx" SG_ 474 NAV_ARAudioSource_Rq 1;
BA_ "U_V710_MY2023_Tx" SG_ 474 NAV_ARAudioSource_Rq 1;
BA_ "U_P708_MY2023_Tx" SG_ 474 NAV_ARAudioSource_Rq 1;
BA_ "U_P702_MY2024_Tx" SG_ 474 NAV_ARAudioSource_Rq 1;
BA_ "GenSigStartValue" SG_ 477 NAV_SetTreble_Rq 15;
BA_ "GenSigSendType" SG_ 477 NAV_SetTreble_Rq 3;
BA_ "U_V713N_MY2022_Rx" SG_ 477 NAV_SetTreble_Rq 1;
BA_ "U_V713AV_MY2022_Rx" SG_ 477 NAV_SetTreble_Rq 1;
BA_ "U_P708_MY2023_Rx" SG_ 477 NAV_SetTreble_Rq 1;
BA_ "U_V710_MY2023_Rx" SG_ 477 NAV_SetTreble_Rq 1;
BA_ "U_V710_MY2023_Tx" SG_ 477 NAV_SetTreble_Rq 1;
BA_ "U_P708_MY2023_Tx" SG_ 477 NAV_SetTreble_Rq 1;
BA_ "U_P702_MY2024_Tx" SG_ 477 NAV_SetTreble_Rq 1;
BA_ "GenSigStartValue" SG_ 477 NAV_SetFader_Rq 15;
BA_ "GenSigSendType" SG_ 477 NAV_SetFader_Rq 3;
BA_ "U_V713N_MY2022_Rx" SG_ 477 NAV_SetFader_Rq 1;
BA_ "U_V713AV_MY2022_Rx" SG_ 477 NAV_SetFader_Rq 1;
BA_ "U_P708_MY2023_Rx" SG_ 477 NAV_SetFader_Rq 1;
BA_ "U_V710_MY2023_Rx" SG_ 477 NAV_SetFader_Rq 1;
BA_ "U_V710_MY2023_Tx" SG_ 477 NAV_SetFader_Rq 1;
BA_ "U_P708_MY2023_Tx" SG_ 477 NAV_SetFader_Rq 1;
BA_ "U_P702_MY2024_Tx" SG_ 477 NAV_SetFader_Rq 1;
BA_ "GenSigStartValue" SG_ 477 NAV_SetBass_Rq 15;
BA_ "GenSigSendType" SG_ 477 NAV_SetBass_Rq 3;
BA_ "U_V713N_MY2022_Rx" SG_ 477 NAV_SetBass_Rq 1;
BA_ "U_V713AV_MY2022_Rx" SG_ 477 NAV_SetBass_Rq 1;
BA_ "U_P708_MY2023_Rx" SG_ 477 NAV_SetBass_Rq 1;
BA_ "U_V710_MY2023_Rx" SG_ 477 NAV_SetBass_Rq 1;
BA_ "U_V710_MY2023_Tx" SG_ 477 NAV_SetBass_Rq 1;
BA_ "U_P708_MY2023_Tx" SG_ 477 NAV_SetBass_Rq 1;
BA_ "U_P702_MY2024_Tx" SG_ 477 NAV_SetBass_Rq 1;
BA_ "GenSigStartValue" SG_ 477 NAV_SetBalance_Rq 15;
BA_ "GenSigSendType" SG_ 477 NAV_SetBalance_Rq 3;
BA_ "U_V713N_MY2022_Rx" SG_ 477 NAV_SetBalance_Rq 1;
BA_ "U_V713AV_MY2022_Rx" SG_ 477 NAV_SetBalance_Rq 1;
BA_ "U_P708_MY2023_Rx" SG_ 477 NAV_SetBalance_Rq 1;
BA_ "U_V710_MY2023_Rx" SG_ 477 NAV_SetBalance_Rq 1;
BA_ "U_V710_MY2023_Tx" SG_ 477 NAV_SetBalance_Rq 1;
BA_ "U_P708_MY2023_Tx" SG_ 477 NAV_SetBalance_Rq 1;
BA_ "U_P702_MY2024_Tx" SG_ 477 NAV_SetBalance_Rq 1;
BA_ "GenSigStartValue" SG_ 477 NAV_SetAVC_Rq 15;
BA_ "GenSigSendType" SG_ 477 NAV_SetAVC_Rq 3;
BA_ "U_V713N_MY2022_Rx" SG_ 477 NAV_SetAVC_Rq 1;
BA_ "U_V713AV_MY2022_Rx" SG_ 477 NAV_SetAVC_Rq 1;
BA_ "U_P708_MY2023_Rx" SG_ 477 NAV_SetAVC_Rq 1;
BA_ "U_V710_MY2023_Rx" SG_ 477 NAV_SetAVC_Rq 1;
BA_ "U_V710_MY2023_Tx" SG_ 477 NAV_SetAVC_Rq 1;
BA_ "U_P708_MY2023_Tx" SG_ 477 NAV_SetAVC_Rq 1;
BA_ "U_P702_MY2024_Tx" SG_ 477 NAV_SetAVC_Rq 1;
BA_ "GenSigSendType" SG_ 477 NAV_SecurtyPINUnlock_Rq 3;
BA_ "U_V713N_MY2022_Rx" SG_ 477 NAV_SecurtyPINUnlock_Rq 1;
BA_ "U_V713AV_MY2022_Rx" SG_ 477 NAV_SecurtyPINUnlock_Rq 1;
BA_ "U_P708_MY2023_Rx" SG_ 477 NAV_SecurtyPINUnlock_Rq 1;
BA_ "U_V710_MY2023_Rx" SG_ 477 NAV_SecurtyPINUnlock_Rq 1;
BA_ "U_V710_MY2023_Tx" SG_ 477 NAV_SecurtyPINUnlock_Rq 1;
BA_ "U_P708_MY2023_Tx" SG_ 477 NAV_SecurtyPINUnlock_Rq 1;
BA_ "U_P702_MY2024_Tx" SG_ 477 NAV_SecurtyPINUnlock_Rq 1;
BA_ "GenSigSendType" SG_ 477 NAV_LoadEjectMode_Rq 3;
BA_ "U_V713N_MY2022_Rx" SG_ 477 NAV_LoadEjectMode_Rq 1;
BA_ "U_V713AV_MY2022_Rx" SG_ 477 NAV_LoadEjectMode_Rq 1;
BA_ "U_P708_MY2023_Rx" SG_ 477 NAV_LoadEjectMode_Rq 1;
BA_ "U_V710_MY2023_Rx" SG_ 477 NAV_LoadEjectMode_Rq 1;
BA_ "U_V710_MY2023_Tx" SG_ 477 NAV_LoadEjectMode_Rq 1;
BA_ "U_P708_MY2023_Tx" SG_ 477 NAV_LoadEjectMode_Rq 1;
BA_ "U_V713N_MY2022_Rx" SG_ 477 NAV_LoadEjectDisc_Rq 1;
BA_ "U_V713AV_MY2022_Rx" SG_ 477 NAV_LoadEjectDisc_Rq 1;
BA_ "U_P708_MY2023_Rx" SG_ 477 NAV_LoadEjectDisc_Rq 1;
BA_ "U_V710_MY2023_Rx" SG_ 477 NAV_LoadEjectDisc_Rq 1;
BA_ "U_V710_MY2023_Tx" SG_ 477 NAV_LoadEjectDisc_Rq 1;
BA_ "U_P708_MY2023_Tx" SG_ 477 NAV_LoadEjectDisc_Rq 1;
BA_ "GenSigSendType" SG_ 260 MFD_SDARS_SetOpMode_Rq 3;
BA_ "U_V713N_MY2022_Rx" SG_ 260 MFD_SDARS_SetOpMode_Rq 1;
BA_ "U_V713AV_MY2022_Rx" SG_ 260 MFD_SDARS_SetOpMode_Rq 1;
BA_ "U_P708_MY2023_Rx" SG_ 260 MFD_SDARS_SetOpMode_Rq 1;
BA_ "U_V710_MY2023_Rx" SG_ 260 MFD_SDARS_SetOpMode_Rq 1;
BA_ "U_P708_MY2023_Tx" SG_ 260 MFD_SDARS_SetOpMode_Rq 1;
BA_ "U_P702_MY2024_Tx" SG_ 260 MFD_SDARS_SetOpMode_Rq 1;
BA_ "GenSigStartValue" SG_ 260 MFD_SDARS_DirectTune_Rq 255;
BA_ "GenSigSendType" SG_ 260 MFD_SDARS_DirectTune_Rq 3;
BA_ "U_V713N_MY2022_Rx" SG_ 260 MFD_SDARS_DirectTune_Rq 1;
BA_ "U_V713AV_MY2022_Rx" SG_ 260 MFD_SDARS_DirectTune_Rq 1;
BA_ "U_P708_MY2023_Rx" SG_ 260 MFD_SDARS_DirectTune_Rq 1;
BA_ "U_V710_MY2023_Rx" SG_ 260 MFD_SDARS_DirectTune_Rq 1;
BA_ "U_P708_MY2023_Tx" SG_ 260 MFD_SDARS_DirectTune_Rq 1;
BA_ "U_P702_MY2024_Tx" SG_ 260 MFD_SDARS_DirectTune_Rq 1;
BA_ "GenSigSendType" SG_ 260 SDARS_GetESN_Rq 3;
BA_ "U_V713N_MY2022_Rx" SG_ 260 SDARS_GetESN_Rq 1;
BA_ "U_V713AV_MY2022_Rx" SG_ 260 SDARS_GetESN_Rq 1;
BA_ "U_P708_MY2023_Rx" SG_ 260 SDARS_GetESN_Rq 1;
BA_ "U_V710_MY2023_Rx" SG_ 260 SDARS_GetESN_Rq 1;
BA_ "U_P708_MY2023_Tx" SG_ 260 SDARS_GetESN_Rq 1;
BA_ "U_P702_MY2024_Tx" SG_ 260 SDARS_GetESN_Rq 1;
BA_ "GenSigSendType" SG_ 260 SDARS_SRReplay_Rq 3;
BA_ "U_V713N_MY2022_Rx" SG_ 260 SDARS_SRReplay_Rq 1;
BA_ "U_V713AV_MY2022_Rx" SG_ 260 SDARS_SRReplay_Rq 1;
BA_ "U_P708_MY2023_Rx" SG_ 260 SDARS_SRReplay_Rq 1;
BA_ "U_V710_MY2023_Rx" SG_ 260 SDARS_SRReplay_Rq 1;
BA_ "U_P708_MY2023_Tx" SG_ 260 SDARS_SRReplay_Rq 1;
BA_ "U_P702_MY2024_Tx" SG_ 260 SDARS_SRReplay_Rq 1;
BA_ "GenSigSendType" SG_ 260 SDARS_SelectCategory_Rq 3;
BA_ "U_V713N_MY2022_Rx" SG_ 260 SDARS_SelectCategory_Rq 1;
BA_ "U_V713AV_MY2022_Rx" SG_ 260 SDARS_SelectCategory_Rq 1;
BA_ "U_P708_MY2023_Rx" SG_ 260 SDARS_SelectCategory_Rq 1;
BA_ "U_V710_MY2023_Rx" SG_ 260 SDARS_SelectCategory_Rq 1;
BA_ "U_P708_MY2023_Tx" SG_ 260 SDARS_SelectCategory_Rq 1;
BA_ "U_P702_MY2024_Tx" SG_ 260 SDARS_SelectCategory_Rq 1;
BA_ "GenSigSendType" SG_ 260 SDARS_InfoRefChanNum_Rq 3;
BA_ "U_V713N_MY2022_Rx" SG_ 260 SDARS_InfoRefChanNum_Rq 1;
BA_ "U_V713AV_MY2022_Rx" SG_ 260 SDARS_InfoRefChanNum_Rq 1;
BA_ "U_P708_MY2023_Rx" SG_ 260 SDARS_InfoRefChanNum_Rq 1;
BA_ "U_V710_MY2023_Rx" SG_ 260 SDARS_InfoRefChanNum_Rq 1;
BA_ "U_P708_MY2023_Tx" SG_ 260 SDARS_InfoRefChanNum_Rq 1;
BA_ "U_P702_MY2024_Tx" SG_ 260 SDARS_InfoRefChanNum_Rq 1;
BA_ "GenSigSendType" SG_ 260 SDARS_FactoryReset_Rq 3;
BA_ "U_V713N_MY2022_Rx" SG_ 260 SDARS_FactoryReset_Rq 1;
BA_ "U_V713AV_MY2022_Rx" SG_ 260 SDARS_FactoryReset_Rq 1;
BA_ "U_P708_MY2023_Rx" SG_ 260 SDARS_FactoryReset_Rq 1;
BA_ "U_V710_MY2023_Rx" SG_ 260 SDARS_FactoryReset_Rq 1;
BA_ "U_P708_MY2023_Tx" SG_ 260 SDARS_FactoryReset_Rq 1;
BA_ "U_P702_MY2024_Tx" SG_ 260 SDARS_FactoryReset_Rq 1;
BA_ "GenSigStartValue" SG_ 476 Nav_SetAudioMixRatio_Rq 31;
BA_ "GenSigSendType" SG_ 476 Nav_SetAudioMixRatio_Rq 3;
BA_ "U_V713N_MY2022_Rx" SG_ 476 Nav_SetAudioMixRatio_Rq 1;
BA_ "U_V713AV_MY2022_Rx" SG_ 476 Nav_SetAudioMixRatio_Rq 1;
BA_ "U_P708_MY2023_Rx" SG_ 476 Nav_SetAudioMixRatio_Rq 1;
BA_ "U_V710_MY2023_Rx" SG_ 476 Nav_SetAudioMixRatio_Rq 1;
BA_ "U_P708_MY2023_Tx" SG_ 476 Nav_SetAudioMixRatio_Rq 1;
BA_ "U_P702_MY2024_Tx" SG_ 476 Nav_SetAudioMixRatio_Rq 1;
BA_ "GenSigSendType" SG_ 476 NAV_SkipCatalouge_Rq 3;
BA_ "U_V713N_MY2022_Rx" SG_ 476 NAV_SkipCatalouge_Rq 1;
BA_ "U_V713AV_MY2022_Rx" SG_ 476 NAV_SkipCatalouge_Rq 1;
BA_ "U_P708_MY2023_Rx" SG_ 476 NAV_SkipCatalouge_Rq 1;
BA_ "U_V710_MY2023_Rx" SG_ 476 NAV_SkipCatalouge_Rq 1;
BA_ "U_P708_MY2023_Tx" SG_ 476 NAV_SkipCatalouge_Rq 1;
BA_ "U_P702_MY2024_Tx" SG_ 476 NAV_SkipCatalouge_Rq 1;
BA_ "GenSigSendType" SG_ 476 NAV_SetOperationMode_Rq 3;
BA_ "U_V713N_MY2022_Rx" SG_ 476 NAV_SetOperationMode_Rq 1;
BA_ "U_V713AV_MY2022_Rx" SG_ 476 NAV_SetOperationMode_Rq 1;
BA_ "U_P708_MY2023_Rx" SG_ 476 NAV_SetOperationMode_Rq 1;
BA_ "U_V710_MY2023_Rx" SG_ 476 NAV_SetOperationMode_Rq 1;
BA_ "U_P708_MY2023_Tx" SG_ 476 NAV_SetOperationMode_Rq 1;
BA_ "U_P702_MY2024_Tx" SG_ 476 NAV_SetOperationMode_Rq 1;
BA_ "GenSigSendType" SG_ 476 NAV_SetDSPProgram_Rq 3;
BA_ "U_V713N_MY2022_Rx" SG_ 476 NAV_SetDSPProgram_Rq 1;
BA_ "U_V713AV_MY2022_Rx" SG_ 476 NAV_SetDSPProgram_Rq 1;
BA_ "U_P708_MY2023_Rx" SG_ 476 NAV_SetDSPProgram_Rq 1;
BA_ "U_V710_MY2023_Rx" SG_ 476 NAV_SetDSPProgram_Rq 1;
BA_ "U_P708_MY2023_Tx" SG_ 476 NAV_SetDSPProgram_Rq 1;
BA_ "U_P702_MY2024_Tx" SG_ 476 NAV_SetDSPProgram_Rq 1;
BA_ "GenSigSendType" SG_ 490 HMI_SetCompression_Rq 3;
BA_ "U_V713N_MY2022_Rx" SG_ 490 HMI_SetCompression_Rq 1;
BA_ "U_V713AV_MY2022_Rx" SG_ 490 HMI_SetCompression_Rq 1;
BA_ "U_P708_MY2023_Rx" SG_ 490 HMI_SetCompression_Rq 1;
BA_ "U_V710_MY2023_Rx" SG_ 490 HMI_SetCompression_Rq 1;
BA_ "U_P708_MY2023_Tx" SG_ 490 HMI_SetCompression_Rq 1;
BA_ "U_P702_MY2024_Tx" SG_ 490 HMI_SetCompression_Rq 1;
BA_ "GenSigSendType" SG_ 490 HMI_SkipTrack_Rq 3;
BA_ "U_V713N_MY2022_Rx" SG_ 490 HMI_SkipTrack_Rq 1;
BA_ "U_V713AV_MY2022_Rx" SG_ 490 HMI_SkipTrack_Rq 1;
BA_ "U_P708_MY2023_Rx" SG_ 490 HMI_SkipTrack_Rq 1;
BA_ "U_V710_MY2023_Rx" SG_ 490 HMI_SkipTrack_Rq 1;
BA_ "U_P708_MY2023_Tx" SG_ 490 HMI_SkipTrack_Rq 1;
BA_ "U_P702_MY2024_Tx" SG_ 490 HMI_SkipTrack_Rq 1;
BA_ "GenSigSendType" SG_ 1916 TesterPhysicalResRACM 3;
BA_ "U_CDX74X_MY2024_Tx" SG_ 1916 TesterPhysicalResRACM 1;
BA_ "GenSigSendType" SG_ 1908 TesterPhysicalReqRACM 3;
BA_ "U_CDX74X_MY2024_Rx" SG_ 1908 TesterPhysicalReqRACM 1;
BA_ "GenSigStartValue" SG_ 1432 RACM_GWOnBoardTester 255;
BA_ "U_CDX74X_MY2024_Tx" SG_ 1432 RACM_GWOnBoardTester 1;
BA_ "GenSigStartValue" SG_ 1432 RACM_GWNMProxy 255;
BA_ "U_CDX74X_MY2024_Tx" SG_ 1432 RACM_GWNMProxy 1;
BA_ "GenSigStartValue" SG_ 1432 RACM_AutoSarNMReserved4 255;
BA_ "U_CDX74X_MY2024_Tx" SG_ 1432 RACM_AutoSarNMReserved4 1;
BA_ "GenSigStartValue" SG_ 1432 RACM_AutoSarNMReserved3 255;
BA_ "U_CDX74X_MY2024_Tx" SG_ 1432 RACM_AutoSarNMReserved3 1;
BA_ "GenSigStartValue" SG_ 1432 RACM_AutoSarNMReserved2 255;
BA_ "U_CDX74X_MY2024_Tx" SG_ 1432 RACM_AutoSarNMReserved2 1;
BA_ "GenSigStartValue" SG_ 1432 RACM_AutoSarNMReserved1 255;
BA_ "U_CDX74X_MY2024_Tx" SG_ 1432 RACM_AutoSarNMReserved1 1;
BA_ "GenSigStartValue" SG_ 1432 RACM_AutoSarNMNodeId 152;
BA_ "U_CDX74X_MY2024_Tx" SG_ 1432 RACM_AutoSarNMNodeId 1;
BA_ "U_CDX74X_MY2024_Tx" SG_ 1432 RACM_AutoSarNMControl 1;
BA_ "GenSigSendType" SG_ 1923 TesterPhysicalReqDSP 3;
BA_ "U_CDX74X_MY2024_Rx" SG_ 1923 TesterPhysicalReqDSP 1;
BA_ "U_V710_MY2023_Rx" SG_ 1923 TesterPhysicalReqDSP 1;
BA_ "GenSigSendType" SG_ 1931 TesterPhysicalResDSP 3;
BA_ "U_CDX74X_MY2024_Tx" SG_ 1931 TesterPhysicalResDSP 1;
BA_ "U_V710_MY2023_Tx" SG_ 1931 TesterPhysicalResDSP 1;
BA_ "GenSigStartValue" SG_ 896 BptDly_T_Actl 62;
BA_ "U_V710_MY2023_Rx" SG_ 896 BptDly_T_Actl 1;
BA_ "U_P708_MY2023_Rx" SG_ 896 BptDly_T_Actl 1;
BA_ "U_P702_MY2024_Rx" SG_ 896 BptDly_T_Actl 1;
BA_ "GenSigStartValue" SG_ 896 VehElAvgTrip1_Eff_Dsply 126;
BA_ "U_V710_MY2023_Rx" SG_ 896 VehElAvgTrip1_Eff_Dsply 1;
BA_ "U_P708_MY2023_Rx" SG_ 896 VehElAvgTrip1_Eff_Dsply 1;
BA_ "U_P702_MY2024_Rx" SG_ 896 VehElAvgTrip1_Eff_Dsply 1;
BA_ "GenSigStartValue" SG_ 896 Trip1SumDrvE_Pc_Dsply 1022;
BA_ "U_V710_MY2023_Rx" SG_ 896 Trip1SumDrvE_Pc_Dsply 1;
BA_ "U_P708_MY2023_Rx" SG_ 896 Trip1SumDrvE_Pc_Dsply 1;
BA_ "U_P702_MY2024_Rx" SG_ 896 Trip1SumDrvE_Pc_Dsply 1;
BA_ "GenSigStartValue" SG_ 896 Trip1ExtFctrE_Pc_Dsply 1022;
BA_ "U_V710_MY2023_Rx" SG_ 896 Trip1ExtFctrE_Pc_Dsply 1;
BA_ "U_P708_MY2023_Rx" SG_ 896 Trip1ExtFctrE_Pc_Dsply 1;
BA_ "U_P702_MY2024_Rx" SG_ 896 Trip1ExtFctrE_Pc_Dsply 1;
BA_ "GenSigStartValue" SG_ 896 Trip1ClimE_Pc_Dsply 1022;
BA_ "U_V710_MY2023_Rx" SG_ 896 Trip1ClimE_Pc_Dsply 1;
BA_ "U_P708_MY2023_Rx" SG_ 896 Trip1ClimE_Pc_Dsply 1;
BA_ "U_P702_MY2024_Rx" SG_ 896 Trip1ClimE_Pc_Dsply 1;
BA_ "GenSigStartValue" SG_ 896 Trip1BattULoE_Pc_Dsply 1022;
BA_ "U_V710_MY2023_Rx" SG_ 896 Trip1BattULoE_Pc_Dsply 1;
BA_ "U_P708_MY2023_Rx" SG_ 896 Trip1BattULoE_Pc_Dsply 1;
BA_ "U_P702_MY2024_Rx" SG_ 896 Trip1BattULoE_Pc_Dsply 1;
BA_ "GenSigStartValue" SG_ 897 VehElAvgTrip2_Eff_Dsply 126;
BA_ "U_V710_MY2023_Rx" SG_ 897 VehElAvgTrip2_Eff_Dsply 1;
BA_ "U_P708_MY2023_Rx" SG_ 897 VehElAvgTrip2_Eff_Dsply 1;
BA_ "U_P702_MY2024_Rx" SG_ 897 VehElAvgTrip2_Eff_Dsply 1;
BA_ "GenSigStartValue" SG_ 897 Trip2SumDrvE_Pc_Dsply 1022;
BA_ "U_V710_MY2023_Rx" SG_ 897 Trip2SumDrvE_Pc_Dsply 1;
BA_ "U_P708_MY2023_Rx" SG_ 897 Trip2SumDrvE_Pc_Dsply 1;
BA_ "U_P702_MY2024_Rx" SG_ 897 Trip2SumDrvE_Pc_Dsply 1;
BA_ "GenSigStartValue" SG_ 897 Trip2ExtFctrE_Pc_Dsply 1022;
BA_ "U_V710_MY2023_Rx" SG_ 897 Trip2ExtFctrE_Pc_Dsply 1;
BA_ "U_P708_MY2023_Rx" SG_ 897 Trip2ExtFctrE_Pc_Dsply 1;
BA_ "U_P702_MY2024_Rx" SG_ 897 Trip2ExtFctrE_Pc_Dsply 1;
BA_ "GenSigStartValue" SG_ 897 Trip2ClimE_Pc_Dsply 1022;
BA_ "U_V710_MY2023_Rx" SG_ 897 Trip2ClimE_Pc_Dsply 1;
BA_ "U_P708_MY2023_Rx" SG_ 897 Trip2ClimE_Pc_Dsply 1;
BA_ "U_P702_MY2024_Rx" SG_ 897 Trip2ClimE_Pc_Dsply 1;
BA_ "GenSigStartValue" SG_ 897 Trip2BattULoE_Pc_Dsply 1022;
BA_ "U_V710_MY2023_Rx" SG_ 897 Trip2BattULoE_Pc_Dsply 1;
BA_ "U_P708_MY2023_Rx" SG_ 897 Trip2BattULoE_Pc_Dsply 1;
BA_ "U_P702_MY2024_Rx" SG_ 897 Trip2BattULoE_Pc_Dsply 1;
BA_ "U_V713N_MY2022_Rx" SG_ 502 Dsp_StartItemIndexRq 1;
BA_ "U_V713AV_MY2022_Rx" SG_ 502 Dsp_StartItemIndexRq 1;
BA_ "U_P708_MY2023_Rx" SG_ 502 Dsp_StartItemIndexRq 1;
BA_ "U_V710_MY2023_Rx" SG_ 502 Dsp_StartItemIndexRq 1;
BA_ "U_P708_MY2023_Tx" SG_ 502 Dsp_StartItemIndexRq 1;
BA_ "U_P702_MY2024_Tx" SG_ 502 Dsp_StartItemIndexRq 1;
BA_ "U_V713N_MY2022_Rx" SG_ 502 Dsp_NbrOfItems2_Rq 1;
BA_ "U_V713AV_MY2022_Rx" SG_ 502 Dsp_NbrOfItems2_Rq 1;
BA_ "U_P708_MY2023_Rx" SG_ 502 Dsp_NbrOfItems2_Rq 1;
BA_ "U_V710_MY2023_Rx" SG_ 502 Dsp_NbrOfItems2_Rq 1;
BA_ "U_P708_MY2023_Tx" SG_ 502 Dsp_NbrOfItems2_Rq 1;
BA_ "U_P702_MY2024_Tx" SG_ 502 Dsp_NbrOfItems2_Rq 1;
BA_ "U_V713N_MY2022_Rx" SG_ 502 Dsp_ItemNameLength2_Rq 1;
BA_ "U_V713AV_MY2022_Rx" SG_ 502 Dsp_ItemNameLength2_Rq 1;
BA_ "U_P708_MY2023_Rx" SG_ 502 Dsp_ItemNameLength2_Rq 1;
BA_ "U_V710_MY2023_Rx" SG_ 502 Dsp_ItemNameLength2_Rq 1;
BA_ "U_P708_MY2023_Tx" SG_ 502 Dsp_ItemNameLength2_Rq 1;
BA_ "U_P702_MY2024_Tx" SG_ 502 Dsp_ItemNameLength2_Rq 1;
BA_ "U_V713N_MY2022_Rx" SG_ 502 Dsp_FolderNumber2_Rq 1;
BA_ "U_V713AV_MY2022_Rx" SG_ 502 Dsp_FolderNumber2_Rq 1;
BA_ "U_P708_MY2023_Rx" SG_ 502 Dsp_FolderNumber2_Rq 1;
BA_ "U_V710_MY2023_Rx" SG_ 502 Dsp_FolderNumber2_Rq 1;
BA_ "U_P708_MY2023_Tx" SG_ 502 Dsp_FolderNumber2_Rq 1;
BA_ "U_P702_MY2024_Tx" SG_ 502 Dsp_FolderNumber2_Rq 1;
BA_ "U_V713N_MY2022_Rx" SG_ 502 Dsp_FolderContent_Rq 1;
BA_ "U_V713AV_MY2022_Rx" SG_ 502 Dsp_FolderContent_Rq 1;
BA_ "U_P708_MY2023_Rx" SG_ 502 Dsp_FolderContent_Rq 1;
BA_ "U_V710_MY2023_Rx" SG_ 502 Dsp_FolderContent_Rq 1;
BA_ "U_P708_MY2023_Tx" SG_ 502 Dsp_FolderContent_Rq 1;
BA_ "U_P702_MY2024_Tx" SG_ 502 Dsp_FolderContent_Rq 1;
BA_ "U_V713N_MY2022_Rx" SG_ 502 Dsp_CutItem2_Rq 1;
BA_ "U_V713AV_MY2022_Rx" SG_ 502 Dsp_CutItem2_Rq 1;
BA_ "U_P708_MY2023_Rx" SG_ 502 Dsp_CutItem2_Rq 1;
BA_ "U_V710_MY2023_Rx" SG_ 502 Dsp_CutItem2_Rq 1;
BA_ "U_P708_MY2023_Tx" SG_ 502 Dsp_CutItem2_Rq 1;
BA_ "U_P702_MY2024_Tx" SG_ 502 Dsp_CutItem2_Rq 1;
BA_ "GenSigSendType" SG_ 502 Dsp_AudioSourceSel2_Rq 3;
BA_ "U_V713N_MY2022_Rx" SG_ 502 Dsp_AudioSourceSel2_Rq 1;
BA_ "U_V713AV_MY2022_Rx" SG_ 502 Dsp_AudioSourceSel2_Rq 1;
BA_ "U_P708_MY2023_Rx" SG_ 502 Dsp_AudioSourceSel2_Rq 1;
BA_ "U_V710_MY2023_Rx" SG_ 502 Dsp_AudioSourceSel2_Rq 1;
BA_ "U_P708_MY2023_Tx" SG_ 502 Dsp_AudioSourceSel2_Rq 1;
BA_ "U_P702_MY2024_Tx" SG_ 502 Dsp_AudioSourceSel2_Rq 1;
BA_ "GenSigStartValue" SG_ 955 Tire_Temp_RF_Data 253;
BA_ "U_V713N_MY2022_Rx" SG_ 955 Tire_Temp_RF_Data 1;
BA_ "U_V713AV_MY2022_Rx" SG_ 955 Tire_Temp_RF_Data 1;
BA_ "U_P708_MY2023_Rx" SG_ 955 Tire_Temp_RF_Data 1;
BA_ "U_V710_MY2023_Rx" SG_ 955 Tire_Temp_RF_Data 1;
BA_ "U_P702_MY2024_Rx" SG_ 955 Tire_Temp_RF_Data 1;
BA_ "GenSigStartValue" SG_ 955 Tire_Temp_ORR_Data 253;
BA_ "U_V713N_MY2022_Rx" SG_ 955 Tire_Temp_ORR_Data 1;
BA_ "U_V713AV_MY2022_Rx" SG_ 955 Tire_Temp_ORR_Data 1;
BA_ "U_P708_MY2023_Rx" SG_ 955 Tire_Temp_ORR_Data 1;
BA_ "U_V710_MY2023_Rx" SG_ 955 Tire_Temp_ORR_Data 1;
BA_ "U_P702_MY2024_Rx" SG_ 955 Tire_Temp_ORR_Data 1;
BA_ "GenSigStartValue" SG_ 955 Tire_Temp_OLR_Data 253;
BA_ "U_V713N_MY2022_Rx" SG_ 955 Tire_Temp_OLR_Data 1;
BA_ "U_V713AV_MY2022_Rx" SG_ 955 Tire_Temp_OLR_Data 1;
BA_ "U_P708_MY2023_Rx" SG_ 955 Tire_Temp_OLR_Data 1;
BA_ "U_V710_MY2023_Rx" SG_ 955 Tire_Temp_OLR_Data 1;
BA_ "U_P702_MY2024_Rx" SG_ 955 Tire_Temp_OLR_Data 1;
BA_ "GenSigStartValue" SG_ 955 Tire_Temp_LF_Data 253;
BA_ "U_V713N_MY2022_Rx" SG_ 955 Tire_Temp_LF_Data 1;
BA_ "U_V713AV_MY2022_Rx" SG_ 955 Tire_Temp_LF_Data 1;
BA_ "U_P708_MY2023_Rx" SG_ 955 Tire_Temp_LF_Data 1;
BA_ "U_V710_MY2023_Rx" SG_ 955 Tire_Temp_LF_Data 1;
BA_ "U_P702_MY2024_Rx" SG_ 955 Tire_Temp_LF_Data 1;
BA_ "GenSigStartValue" SG_ 955 Tire_Temp_IRR_Data 253;
BA_ "U_V713N_MY2022_Rx" SG_ 955 Tire_Temp_IRR_Data 1;
BA_ "U_V713AV_MY2022_Rx" SG_ 955 Tire_Temp_IRR_Data 1;
BA_ "U_P708_MY2023_Rx" SG_ 955 Tire_Temp_IRR_Data 1;
BA_ "U_V710_MY2023_Rx" SG_ 955 Tire_Temp_IRR_Data 1;
BA_ "U_P702_MY2024_Rx" SG_ 955 Tire_Temp_IRR_Data 1;
BA_ "GenSigStartValue" SG_ 955 Tire_Temp_ILR_Data 253;
BA_ "U_V713N_MY2022_Rx" SG_ 955 Tire_Temp_ILR_Data 1;
BA_ "U_V713AV_MY2022_Rx" SG_ 955 Tire_Temp_ILR_Data 1;
BA_ "U_P708_MY2023_Rx" SG_ 955 Tire_Temp_ILR_Data 1;
BA_ "U_V710_MY2023_Rx" SG_ 955 Tire_Temp_ILR_Data 1;
BA_ "U_P702_MY2024_Rx" SG_ 955 Tire_Temp_ILR_Data 1;
BA_ "GenSigSendType" SG_ 1116 TrlrAidSetup_D2_Rq 3;
BA_ "U_V710_MY2023_Tx" SG_ 1116 TrlrAidSetup_D2_Rq 1;
BA_ "U_P708_MY2023_Tx" SG_ 1116 TrlrAidSetup_D2_Rq 1;
BA_ "U_P702_MY2024_Tx" SG_ 1116 TrlrAidSetup_D2_Rq 1;
BA_ "GenSigSendType" SG_ 1116 TrlrAidEnbl_D2_Rq 3;
BA_ "U_V710_MY2023_Tx" SG_ 1116 TrlrAidEnbl_D2_Rq 1;
BA_ "U_P708_MY2023_Tx" SG_ 1116 TrlrAidEnbl_D2_Rq 1;
BA_ "U_P702_MY2024_Tx" SG_ 1116 TrlrAidEnbl_D2_Rq 1;
BA_ "GenSigSendType" SG_ 1116 TlightTest_D_Mnu 3;
BA_ "ECGUsedRxSignal" SG_ 1116 TlightTest_D_Mnu 1;
BA_ "U_V713N_MY2022_Rx" SG_ 1116 TlightTest_D_Mnu 1;
BA_ "U_V713AV_MY2022_Rx" SG_ 1116 TlightTest_D_Mnu 1;
BA_ "U_CDX74X_MY2024_Rx" SG_ 1116 TlightTest_D_Mnu 1;
BA_ "U_V710_MY2023_Rx" SG_ 1116 TlightTest_D_Mnu 1;
BA_ "U_V710_MY2023_Tx" SG_ 1116 TlightTest_D_Mnu 1;
BA_ "U_P708_MY2023_Tx" SG_ 1116 TlightTest_D_Mnu 1;
BA_ "U_P702_MY2024_Tx" SG_ 1116 TlightTest_D_Mnu 1;
BA_ "U_V710_MY2023_Tx" SG_ 1116 TrlrTrgtToBmpr_L_Actl 1;
BA_ "U_P708_MY2023_Tx" SG_ 1116 TrlrTrgtToBmpr_L_Actl 1;
BA_ "U_P702_MY2024_Tx" SG_ 1116 TrlrTrgtToBmpr_L_Actl 1;
BA_ "U_V710_MY2023_Tx" SG_ 1116 TrlrTrgtPtrnId_No_Mem 1;
BA_ "U_P708_MY2023_Tx" SG_ 1116 TrlrTrgtPtrnId_No_Mem 1;
BA_ "U_P702_MY2024_Tx" SG_ 1116 TrlrTrgtPtrnId_No_Mem 1;
BA_ "GenSigSendType" SG_ 1116 TrlrRvrseCancl_B_Rq 3;
BA_ "U_V710_MY2023_Tx" SG_ 1116 TrlrRvrseCancl_B_Rq 1;
BA_ "U_P708_MY2023_Tx" SG_ 1116 TrlrRvrseCancl_B_Rq 1;
BA_ "U_P702_MY2024_Tx" SG_ 1116 TrlrRvrseCancl_B_Rq 1;
BA_ "GenSigSendType" SG_ 1116 TrlrIdType_D_Stat 3;
BA_ "U_V710_MY2023_Tx" SG_ 1116 TrlrIdType_D_Stat 1;
BA_ "U_P708_MY2023_Tx" SG_ 1116 TrlrIdType_D_Stat 1;
BA_ "U_P702_MY2024_Tx" SG_ 1116 TrlrIdType_D_Stat 1;
BA_ "U_V710_MY2023_Tx" SG_ 1116 TrlrId_No_Actl 1;
BA_ "U_P708_MY2023_Tx" SG_ 1116 TrlrId_No_Actl 1;
BA_ "U_P702_MY2024_Tx" SG_ 1116 TrlrId_No_Actl 1;
BA_ "U_V710_MY2023_Tx" SG_ 1116 TrlrBallToBmpr_L_Actl 1;
BA_ "U_P708_MY2023_Tx" SG_ 1116 TrlrBallToBmpr_L_Actl 1;
BA_ "U_P702_MY2024_Tx" SG_ 1116 TrlrBallToBmpr_L_Actl 1;
BA_ "U_V710_MY2023_Tx" SG_ 1116 TrlrAxleToBmpr_L_Actl 1;
BA_ "U_P708_MY2023_Tx" SG_ 1116 TrlrAxleToBmpr_L_Actl 1;
BA_ "U_P702_MY2024_Tx" SG_ 1116 TrlrAxleToBmpr_L_Actl 1;
BA_ "GenSigSendType" SG_ 1116 TrlrAnOffstDir_D_Mem 3;
BA_ "U_V710_MY2023_Tx" SG_ 1116 TrlrAnOffstDir_D_Mem 1;
BA_ "U_P708_MY2023_Tx" SG_ 1116 TrlrAnOffstDir_D_Mem 1;
BA_ "U_P702_MY2024_Tx" SG_ 1116 TrlrAnOffstDir_D_Mem 1;
BA_ "U_V710_MY2023_Tx" SG_ 1116 TrlrAnOffst_An_Mem 1;
BA_ "U_P708_MY2023_Tx" SG_ 1116 TrlrAnOffst_An_Mem 1;
BA_ "U_P702_MY2024_Tx" SG_ 1116 TrlrAnOffst_An_Mem 1;
BA_ "U_V710_MY2023_Tx" SG_ 1116 TrlrTrgtOffst_L_Actl 1;
BA_ "U_P708_MY2023_Tx" SG_ 1116 TrlrTrgtOffst_L_Actl 1;
BA_ "U_P702_MY2024_Tx" SG_ 1116 TrlrTrgtOffst_L_Actl 1;
BA_ "GenSigStartValue" SG_ 608 EvseDcChrgIso_D_Stat 6;
BA_ "U_V713N_MY2022_Rx" SG_ 608 DcChrgSrvcRqd_B_Rq 1;
BA_ "U_V713AV_MY2022_Rx" SG_ 608 DcChrgSrvcRqd_B_Rq 1;
BA_ "U_P708_MY2023_Rx" SG_ 608 DcChrgSrvcRqd_B_Rq 1;
BA_ "WakeupSignal" SG_ 608 DcChrgWarnLamp_B_Rq 1;
BA_ "GenSigStartValue" SG_ 608 EvseChrg2_Pw_Mx 32766;
BA_ "U_V713AV_MY2022_Rx" SG_ 1237 ApaSlotRef2Y_L_Actl 1;
BA_ "U_P708_MY2023_Rx" SG_ 1237 ApaSlotRef2Y_L_Actl 1;
BA_ "U_V710_MY2023_Rx" SG_ 1237 ApaSlotRef2Y_L_Actl 1;
BA_ "U_P702_MY2024_Rx" SG_ 1237 ApaSlotRef2Y_L_Actl 1;
BA_ "U_V713AV_MY2022_Rx" SG_ 1237 ApaSlotRef2X_L_Actl 1;
BA_ "U_P708_MY2023_Rx" SG_ 1237 ApaSlotRef2X_L_Actl 1;
BA_ "U_V710_MY2023_Rx" SG_ 1237 ApaSlotRef2X_L_Actl 1;
BA_ "U_P702_MY2024_Rx" SG_ 1237 ApaSlotRef2X_L_Actl 1;
BA_ "U_V713AV_MY2022_Rx" SG_ 1237 ApaSlotRef1Y_L_Actl 1;
BA_ "U_P708_MY2023_Rx" SG_ 1237 ApaSlotRef1Y_L_Actl 1;
BA_ "U_V710_MY2023_Rx" SG_ 1237 ApaSlotRef1Y_L_Actl 1;
BA_ "U_P702_MY2024_Rx" SG_ 1237 ApaSlotRef1Y_L_Actl 1;
BA_ "U_V713AV_MY2022_Rx" SG_ 1237 ApaSlotRef1X_L_Actl 1;
BA_ "U_P708_MY2023_Rx" SG_ 1237 ApaSlotRef1X_L_Actl 1;
BA_ "U_V710_MY2023_Rx" SG_ 1237 ApaSlotRef1X_L_Actl 1;
BA_ "U_P702_MY2024_Rx" SG_ 1237 ApaSlotRef1X_L_Actl 1;
BA_ "U_V713AV_MY2022_Tx" SG_ 838 FohStrtDay_T_Rq 1;
BA_ "U_P708_MY2023_Tx" SG_ 838 FohStrtDay_T_Rq 1;
BA_ "U_V710_MY2023_Tx" SG_ 838 FohStrtDay_T_Rq 1;
BA_ "U_P702_MY2024_Tx" SG_ 838 FohStrtDay_T_Rq 1;
BA_ "GenSigStartValue" SG_ 838 FohStop_B_Rq 3;
BA_ "U_V710_MY2023_Tx" SG_ 838 FohStop_B_Rq 1;
BA_ "U_V713AV_MY2022_Tx" SG_ 838 FohStop_B_Rq 1;
BA_ "U_P708_MY2023_Tx" SG_ 838 FohStop_B_Rq 1;
BA_ "U_P702_MY2024_Tx" SG_ 838 FohStop_B_Rq 1;
BA_ "GenSigStartValue" SG_ 838 FohTAllEnable_B_Rq 3;
BA_ "U_V710_MY2023_Tx" SG_ 838 FohTAllEnable_B_Rq 1;
BA_ "U_V713AV_MY2022_Tx" SG_ 838 FohTAllEnable_B_Rq 1;
BA_ "U_P708_MY2023_Tx" SG_ 838 FohTAllEnable_B_Rq 1;
BA_ "U_P702_MY2024_Tx" SG_ 838 FohTAllEnable_B_Rq 1;
BA_ "U_V710_MY2023_Tx" SG_ 838 FohT2Mnte_T_Rq 1;
BA_ "U_V713AV_MY2022_Tx" SG_ 838 FohT2Mnte_T_Rq 1;
BA_ "U_P708_MY2023_Tx" SG_ 838 FohT2Mnte_T_Rq 1;
BA_ "U_P702_MY2024_Tx" SG_ 838 FohT2Mnte_T_Rq 1;
BA_ "U_V710_MY2023_Tx" SG_ 838 FohT2Hr_T_Rq 1;
BA_ "U_V713AV_MY2022_Tx" SG_ 838 FohT2Hr_T_Rq 1;
BA_ "U_P708_MY2023_Tx" SG_ 838 FohT2Hr_T_Rq 1;
BA_ "U_P702_MY2024_Tx" SG_ 838 FohT2Hr_T_Rq 1;
BA_ "U_V710_MY2023_Tx" SG_ 838 FohT2Enable_B_Rq 1;
BA_ "U_V713AV_MY2022_Tx" SG_ 838 FohT2Enable_B_Rq 1;
BA_ "U_P708_MY2023_Tx" SG_ 838 FohT2Enable_B_Rq 1;
BA_ "U_P702_MY2024_Tx" SG_ 838 FohT2Enable_B_Rq 1;
BA_ "U_V710_MY2023_Tx" SG_ 838 FohT1Mnte_T_Rq 1;
BA_ "U_V713AV_MY2022_Tx" SG_ 838 FohT1Mnte_T_Rq 1;
BA_ "U_P708_MY2023_Tx" SG_ 838 FohT1Mnte_T_Rq 1;
BA_ "U_P702_MY2024_Tx" SG_ 838 FohT1Mnte_T_Rq 1;
BA_ "U_V710_MY2023_Tx" SG_ 838 FohT1Hr_T_Rq 1;
BA_ "U_V713AV_MY2022_Tx" SG_ 838 FohT1Hr_T_Rq 1;
BA_ "U_P708_MY2023_Tx" SG_ 838 FohT1Hr_T_Rq 1;
BA_ "U_P702_MY2024_Tx" SG_ 838 FohT1Hr_T_Rq 1;
BA_ "U_V710_MY2023_Tx" SG_ 838 FohT1Enable_B_Rq 1;
BA_ "U_V713AV_MY2022_Tx" SG_ 838 FohT1Enable_B_Rq 1;
BA_ "U_P708_MY2023_Tx" SG_ 838 FohT1Enable_B_Rq 1;
BA_ "U_P702_MY2024_Tx" SG_ 838 FohT1Enable_B_Rq 1;
BA_ "U_V710_MY2023_Tx" SG_ 838 FohStrtMnte_T_Rq 1;
BA_ "U_V713AV_MY2022_Tx" SG_ 838 FohStrtMnte_T_Rq 1;
BA_ "U_P708_MY2023_Tx" SG_ 838 FohStrtMnte_T_Rq 1;
BA_ "U_P702_MY2024_Tx" SG_ 838 FohStrtMnte_T_Rq 1;
BA_ "U_V710_MY2023_Tx" SG_ 838 FohStrtHr_T_Rq 1;
BA_ "U_V713AV_MY2022_Tx" SG_ 838 FohStrtHr_T_Rq 1;
BA_ "U_P708_MY2023_Tx" SG_ 838 FohStrtHr_T_Rq 1;
BA_ "U_P702_MY2024_Tx" SG_ 838 FohStrtHr_T_Rq 1;
BA_ "U_V710_MY2023_Tx" SG_ 838 FohStrtEnable_B_Rq 1;
BA_ "U_V713AV_MY2022_Tx" SG_ 838 FohStrtEnable_B_Rq 1;
BA_ "U_P708_MY2023_Tx" SG_ 838 FohStrtEnable_B_Rq 1;
BA_ "U_P702_MY2024_Tx" SG_ 838 FohStrtEnable_B_Rq 1;
BA_ "GenSigStartValue" SG_ 838 FohContOn_B_Rq 3;
BA_ "U_V710_MY2023_Tx" SG_ 838 FohContOn_B_Rq 1;
BA_ "U_V713AV_MY2022_Tx" SG_ 838 FohContOn_B_Rq 1;
BA_ "U_P708_MY2023_Tx" SG_ 838 FohContOn_B_Rq 1;
BA_ "U_P702_MY2024_Tx" SG_ 838 FohContOn_B_Rq 1;
BA_ "U_V713AV_MY2022_Rx" SG_ 1255 BalrRight4Threat_D_Stat 1;
BA_ "U_P708_MY2023_Rx" SG_ 1255 BalrRight4Threat_D_Stat 1;
BA_ "U_V710_MY2023_Rx" SG_ 1255 BalrRight4Threat_D_Stat 1;
BA_ "U_P702_MY2024_Rx" SG_ 1255 BalrRight4Threat_D_Stat 1;
BA_ "U_V713AV_MY2022_Rx" SG_ 1255 BalrRight4Prev3Y_L_Actl 1;
BA_ "U_P708_MY2023_Rx" SG_ 1255 BalrRight4Prev3Y_L_Actl 1;
BA_ "U_V710_MY2023_Rx" SG_ 1255 BalrRight4Prev3Y_L_Actl 1;
BA_ "U_P702_MY2024_Rx" SG_ 1255 BalrRight4Prev3Y_L_Actl 1;
BA_ "U_V713AV_MY2022_Rx" SG_ 1255 BalrRight4Prev3X_L_Actl 1;
BA_ "U_P708_MY2023_Rx" SG_ 1255 BalrRight4Prev3X_L_Actl 1;
BA_ "U_V710_MY2023_Rx" SG_ 1255 BalrRight4Prev3X_L_Actl 1;
BA_ "U_P702_MY2024_Rx" SG_ 1255 BalrRight4Prev3X_L_Actl 1;
BA_ "U_V713AV_MY2022_Rx" SG_ 1255 BalrRight4Prev2Y_L_Actl 1;
BA_ "U_P708_MY2023_Rx" SG_ 1255 BalrRight4Prev2Y_L_Actl 1;
BA_ "U_V710_MY2023_Rx" SG_ 1255 BalrRight4Prev2Y_L_Actl 1;
BA_ "U_P702_MY2024_Rx" SG_ 1255 BalrRight4Prev2Y_L_Actl 1;
BA_ "U_V713AV_MY2022_Rx" SG_ 1255 BalrRight4Prev2X_L_Actl 1;
BA_ "U_P708_MY2023_Rx" SG_ 1255 BalrRight4Prev2X_L_Actl 1;
BA_ "U_V710_MY2023_Rx" SG_ 1255 BalrRight4Prev2X_L_Actl 1;
BA_ "U_P702_MY2024_Rx" SG_ 1255 BalrRight4Prev2X_L_Actl 1;
BA_ "U_V713AV_MY2022_Rx" SG_ 1255 BalrRight4Prev1Y_L_Actl 1;
BA_ "U_P708_MY2023_Rx" SG_ 1255 BalrRight4Prev1Y_L_Actl 1;
BA_ "U_V710_MY2023_Rx" SG_ 1255 BalrRight4Prev1Y_L_Actl 1;
BA_ "U_P702_MY2024_Rx" SG_ 1255 BalrRight4Prev1Y_L_Actl 1;
BA_ "U_V713AV_MY2022_Rx" SG_ 1255 BalrRight4Prev1X_L_Actl 1;
BA_ "U_P708_MY2023_Rx" SG_ 1255 BalrRight4Prev1X_L_Actl 1;
BA_ "U_V710_MY2023_Rx" SG_ 1255 BalrRight4Prev1X_L_Actl 1;
BA_ "U_P702_MY2024_Rx" SG_ 1255 BalrRight4Prev1X_L_Actl 1;
BA_ "U_V713AV_MY2022_Rx" SG_ 1255 BalrRight4Fast_B_Stat 1;
BA_ "U_P708_MY2023_Rx" SG_ 1255 BalrRight4Fast_B_Stat 1;
BA_ "U_V710_MY2023_Rx" SG_ 1255 BalrRight4Fast_B_Stat 1;
BA_ "U_P702_MY2024_Rx" SG_ 1255 BalrRight4Fast_B_Stat 1;
BA_ "U_V713AV_MY2022_Rx" SG_ 1255 BalrRight4Dsply_B_Stat 1;
BA_ "U_P708_MY2023_Rx" SG_ 1255 BalrRight4Dsply_B_Stat 1;
BA_ "U_V710_MY2023_Rx" SG_ 1255 BalrRight4Dsply_B_Stat 1;
BA_ "U_P702_MY2024_Rx" SG_ 1255 BalrRight4Dsply_B_Stat 1;
BA_ "U_V713AV_MY2022_Rx" SG_ 1255 BalrRight4CurntY_L_Actl 1;
BA_ "U_P708_MY2023_Rx" SG_ 1255 BalrRight4CurntY_L_Actl 1;
BA_ "U_V710_MY2023_Rx" SG_ 1255 BalrRight4CurntY_L_Actl 1;
BA_ "U_P702_MY2024_Rx" SG_ 1255 BalrRight4CurntY_L_Actl 1;
BA_ "U_V713AV_MY2022_Rx" SG_ 1255 BalrRight4CurntX_L_Actl 1;
BA_ "U_P708_MY2023_Rx" SG_ 1255 BalrRight4CurntX_L_Actl 1;
BA_ "U_V710_MY2023_Rx" SG_ 1255 BalrRight4CurntX_L_Actl 1;
BA_ "U_P702_MY2024_Rx" SG_ 1255 BalrRight4CurntX_L_Actl 1;
BA_ "U_V713AV_MY2022_Rx" SG_ 1254 BalrRight3Threat_D_Stat 1;
BA_ "U_P708_MY2023_Rx" SG_ 1254 BalrRight3Threat_D_Stat 1;
BA_ "U_V710_MY2023_Rx" SG_ 1254 BalrRight3Threat_D_Stat 1;
BA_ "U_P702_MY2024_Rx" SG_ 1254 BalrRight3Threat_D_Stat 1;
BA_ "U_V713AV_MY2022_Rx" SG_ 1254 BalrRight3Prev3Y_L_Actl 1;
BA_ "U_P708_MY2023_Rx" SG_ 1254 BalrRight3Prev3Y_L_Actl 1;
BA_ "U_V710_MY2023_Rx" SG_ 1254 BalrRight3Prev3Y_L_Actl 1;
BA_ "U_P702_MY2024_Rx" SG_ 1254 BalrRight3Prev3Y_L_Actl 1;
BA_ "U_V713AV_MY2022_Rx" SG_ 1254 BalrRight3Prev3X_L_Actl 1;
BA_ "U_P708_MY2023_Rx" SG_ 1254 BalrRight3Prev3X_L_Actl 1;
BA_ "U_V710_MY2023_Rx" SG_ 1254 BalrRight3Prev3X_L_Actl 1;
BA_ "U_P702_MY2024_Rx" SG_ 1254 BalrRight3Prev3X_L_Actl 1;
BA_ "U_V713AV_MY2022_Rx" SG_ 1254 BalrRight3Prev2Y_L_Actl 1;
BA_ "U_P708_MY2023_Rx" SG_ 1254 BalrRight3Prev2Y_L_Actl 1;
BA_ "U_V710_MY2023_Rx" SG_ 1254 BalrRight3Prev2Y_L_Actl 1;
BA_ "U_P702_MY2024_Rx" SG_ 1254 BalrRight3Prev2Y_L_Actl 1;
BA_ "U_V713AV_MY2022_Rx" SG_ 1254 BalrRight3Prev2X_L_Actl 1;
BA_ "U_P708_MY2023_Rx" SG_ 1254 BalrRight3Prev2X_L_Actl 1;
BA_ "U_V710_MY2023_Rx" SG_ 1254 BalrRight3Prev2X_L_Actl 1;
BA_ "U_P702_MY2024_Rx" SG_ 1254 BalrRight3Prev2X_L_Actl 1;
BA_ "U_V713AV_MY2022_Rx" SG_ 1254 BalrRight3Prev1Y_L_Actl 1;
BA_ "U_P708_MY2023_Rx" SG_ 1254 BalrRight3Prev1Y_L_Actl 1;
BA_ "U_V710_MY2023_Rx" SG_ 1254 BalrRight3Prev1Y_L_Actl 1;
BA_ "U_P702_MY2024_Rx" SG_ 1254 BalrRight3Prev1Y_L_Actl 1;
BA_ "U_V713AV_MY2022_Rx" SG_ 1254 BalrRight3Prev1X_L_Actl 1;
BA_ "U_P708_MY2023_Rx" SG_ 1254 BalrRight3Prev1X_L_Actl 1;
BA_ "U_V710_MY2023_Rx" SG_ 1254 BalrRight3Prev1X_L_Actl 1;
BA_ "U_P702_MY2024_Rx" SG_ 1254 BalrRight3Prev1X_L_Actl 1;
BA_ "U_V713AV_MY2022_Rx" SG_ 1254 BalrRight3Fast_B_Stat 1;
BA_ "U_P708_MY2023_Rx" SG_ 1254 BalrRight3Fast_B_Stat 1;
BA_ "U_V710_MY2023_Rx" SG_ 1254 BalrRight3Fast_B_Stat 1;
BA_ "U_P702_MY2024_Rx" SG_ 1254 BalrRight3Fast_B_Stat 1;
BA_ "U_V713AV_MY2022_Rx" SG_ 1254 BalrRight3Dsply_B_Stat 1;
BA_ "U_P708_MY2023_Rx" SG_ 1254 BalrRight3Dsply_B_Stat 1;
BA_ "U_V710_MY2023_Rx" SG_ 1254 BalrRight3Dsply_B_Stat 1;
BA_ "U_P702_MY2024_Rx" SG_ 1254 BalrRight3Dsply_B_Stat 1;
BA_ "U_V713AV_MY2022_Rx" SG_ 1254 BalrRight3CurntY_L_Actl 1;
BA_ "U_P708_MY2023_Rx" SG_ 1254 BalrRight3CurntY_L_Actl 1;
BA_ "U_V710_MY2023_Rx" SG_ 1254 BalrRight3CurntY_L_Actl 1;
BA_ "U_P702_MY2024_Rx" SG_ 1254 BalrRight3CurntY_L_Actl 1;
BA_ "U_V713AV_MY2022_Rx" SG_ 1254 BalrRight3CurntX_L_Actl 1;
BA_ "U_P708_MY2023_Rx" SG_ 1254 BalrRight3CurntX_L_Actl 1;
BA_ "U_V710_MY2023_Rx" SG_ 1254 BalrRight3CurntX_L_Actl 1;
BA_ "U_P702_MY2024_Rx" SG_ 1254 BalrRight3CurntX_L_Actl 1;
BA_ "U_V713AV_MY2022_Rx" SG_ 1253 BalrRight2Prev3Y_L_Actl 1;
BA_ "U_P708_MY2023_Rx" SG_ 1253 BalrRight2Prev3Y_L_Actl 1;
BA_ "U_V710_MY2023_Rx" SG_ 1253 BalrRight2Prev3Y_L_Actl 1;
BA_ "U_P702_MY2024_Rx" SG_ 1253 BalrRight2Prev3Y_L_Actl 1;
BA_ "U_V713AV_MY2022_Rx" SG_ 1253 BalrRight2Prev3X_L_Actl 1;
BA_ "U_P708_MY2023_Rx" SG_ 1253 BalrRight2Prev3X_L_Actl 1;
BA_ "U_V710_MY2023_Rx" SG_ 1253 BalrRight2Prev3X_L_Actl 1;
BA_ "U_P702_MY2024_Rx" SG_ 1253 BalrRight2Prev3X_L_Actl 1;
BA_ "U_V713AV_MY2022_Rx" SG_ 1253 BalrRight2Threat_D_Stat 1;
BA_ "U_P708_MY2023_Rx" SG_ 1253 BalrRight2Threat_D_Stat 1;
BA_ "U_V710_MY2023_Rx" SG_ 1253 BalrRight2Threat_D_Stat 1;
BA_ "U_P702_MY2024_Rx" SG_ 1253 BalrRight2Threat_D_Stat 1;
BA_ "U_V713AV_MY2022_Rx" SG_ 1253 BalrRight2Prev2Y_L_Actl 1;
BA_ "U_P708_MY2023_Rx" SG_ 1253 BalrRight2Prev2Y_L_Actl 1;
BA_ "U_V710_MY2023_Rx" SG_ 1253 BalrRight2Prev2Y_L_Actl 1;
BA_ "U_P702_MY2024_Rx" SG_ 1253 BalrRight2Prev2Y_L_Actl 1;
BA_ "U_V713AV_MY2022_Rx" SG_ 1253 BalrRight2Prev2X_L_Actl 1;
BA_ "U_P708_MY2023_Rx" SG_ 1253 BalrRight2Prev2X_L_Actl 1;
BA_ "U_V710_MY2023_Rx" SG_ 1253 BalrRight2Prev2X_L_Actl 1;
BA_ "U_P702_MY2024_Rx" SG_ 1253 BalrRight2Prev2X_L_Actl 1;
BA_ "U_V713AV_MY2022_Rx" SG_ 1253 BalrRight2Prev1Y_L_Actl 1;
BA_ "U_P708_MY2023_Rx" SG_ 1253 BalrRight2Prev1Y_L_Actl 1;
BA_ "U_V710_MY2023_Rx" SG_ 1253 BalrRight2Prev1Y_L_Actl 1;
BA_ "U_P702_MY2024_Rx" SG_ 1253 BalrRight2Prev1Y_L_Actl 1;
BA_ "U_V713AV_MY2022_Rx" SG_ 1253 BalrRight2Prev1X_L_Actl 1;
BA_ "U_P708_MY2023_Rx" SG_ 1253 BalrRight2Prev1X_L_Actl 1;
BA_ "U_V710_MY2023_Rx" SG_ 1253 BalrRight2Prev1X_L_Actl 1;
BA_ "U_P702_MY2024_Rx" SG_ 1253 BalrRight2Prev1X_L_Actl 1;
BA_ "U_V713AV_MY2022_Rx" SG_ 1253 BalrRight2Fast_B_Stat 1;
BA_ "U_P708_MY2023_Rx" SG_ 1253 BalrRight2Fast_B_Stat 1;
BA_ "U_V710_MY2023_Rx" SG_ 1253 BalrRight2Fast_B_Stat 1;
BA_ "U_P702_MY2024_Rx" SG_ 1253 BalrRight2Fast_B_Stat 1;
BA_ "U_V713AV_MY2022_Rx" SG_ 1253 BalrRight2Dsply_B_Stat 1;
BA_ "U_P708_MY2023_Rx" SG_ 1253 BalrRight2Dsply_B_Stat 1;
BA_ "U_V710_MY2023_Rx" SG_ 1253 BalrRight2Dsply_B_Stat 1;
BA_ "U_P702_MY2024_Rx" SG_ 1253 BalrRight2Dsply_B_Stat 1;
BA_ "U_V713AV_MY2022_Rx" SG_ 1253 BalrRight2CurntY_L_Actl 1;
BA_ "U_P708_MY2023_Rx" SG_ 1253 BalrRight2CurntY_L_Actl 1;
BA_ "U_V710_MY2023_Rx" SG_ 1253 BalrRight2CurntY_L_Actl 1;
BA_ "U_P702_MY2024_Rx" SG_ 1253 BalrRight2CurntY_L_Actl 1;
BA_ "U_V713AV_MY2022_Rx" SG_ 1253 BalrRight2CurntX_L_Actl 1;
BA_ "U_P708_MY2023_Rx" SG_ 1253 BalrRight2CurntX_L_Actl 1;
BA_ "U_V710_MY2023_Rx" SG_ 1253 BalrRight2CurntX_L_Actl 1;
BA_ "U_P702_MY2024_Rx" SG_ 1253 BalrRight2CurntX_L_Actl 1;
BA_ "U_V713AV_MY2022_Rx" SG_ 1252 BalrRight1Prev3Y_L_Actl 1;
BA_ "U_P708_MY2023_Rx" SG_ 1252 BalrRight1Prev3Y_L_Actl 1;
BA_ "U_V710_MY2023_Rx" SG_ 1252 BalrRight1Prev3Y_L_Actl 1;
BA_ "U_P702_MY2024_Rx" SG_ 1252 BalrRight1Prev3Y_L_Actl 1;
BA_ "U_V713AV_MY2022_Rx" SG_ 1252 BalrRight1Prev3X_L_Actl 1;
BA_ "U_P708_MY2023_Rx" SG_ 1252 BalrRight1Prev3X_L_Actl 1;
BA_ "U_V710_MY2023_Rx" SG_ 1252 BalrRight1Prev3X_L_Actl 1;
BA_ "U_P702_MY2024_Rx" SG_ 1252 BalrRight1Prev3X_L_Actl 1;
BA_ "U_V713AV_MY2022_Rx" SG_ 1252 BalrRight1Threat_D_Stat 1;
BA_ "U_P708_MY2023_Rx" SG_ 1252 BalrRight1Threat_D_Stat 1;
BA_ "U_V710_MY2023_Rx" SG_ 1252 BalrRight1Threat_D_Stat 1;
BA_ "U_P702_MY2024_Rx" SG_ 1252 BalrRight1Threat_D_Stat 1;
BA_ "U_V713AV_MY2022_Rx" SG_ 1252 BalrRight1Prev2Y_L_Actl 1;
BA_ "U_P708_MY2023_Rx" SG_ 1252 BalrRight1Prev2Y_L_Actl 1;
BA_ "U_V710_MY2023_Rx" SG_ 1252 BalrRight1Prev2Y_L_Actl 1;
BA_ "U_P702_MY2024_Rx" SG_ 1252 BalrRight1Prev2Y_L_Actl 1;
BA_ "U_V713AV_MY2022_Rx" SG_ 1252 BalrRight1Prev2X_L_Actl 1;
BA_ "U_P708_MY2023_Rx" SG_ 1252 BalrRight1Prev2X_L_Actl 1;
BA_ "U_V710_MY2023_Rx" SG_ 1252 BalrRight1Prev2X_L_Actl 1;
BA_ "U_P702_MY2024_Rx" SG_ 1252 BalrRight1Prev2X_L_Actl 1;
BA_ "U_V713AV_MY2022_Rx" SG_ 1252 BalrRight1Prev1Y_L_Actl 1;
BA_ "U_P708_MY2023_Rx" SG_ 1252 BalrRight1Prev1Y_L_Actl 1;
BA_ "U_V710_MY2023_Rx" SG_ 1252 BalrRight1Prev1Y_L_Actl 1;
BA_ "U_P702_MY2024_Rx" SG_ 1252 BalrRight1Prev1Y_L_Actl 1;
BA_ "U_V713AV_MY2022_Rx" SG_ 1252 BalrRight1Prev1X_L_Actl 1;
BA_ "U_P708_MY2023_Rx" SG_ 1252 BalrRight1Prev1X_L_Actl 1;
BA_ "U_V710_MY2023_Rx" SG_ 1252 BalrRight1Prev1X_L_Actl 1;
BA_ "U_P702_MY2024_Rx" SG_ 1252 BalrRight1Prev1X_L_Actl 1;
BA_ "U_V713AV_MY2022_Rx" SG_ 1252 BalrRight1Fast_B_Stat 1;
BA_ "U_P708_MY2023_Rx" SG_ 1252 BalrRight1Fast_B_Stat 1;
BA_ "U_V710_MY2023_Rx" SG_ 1252 BalrRight1Fast_B_Stat 1;
BA_ "U_P702_MY2024_Rx" SG_ 1252 BalrRight1Fast_B_Stat 1;
BA_ "U_V713AV_MY2022_Rx" SG_ 1252 BalrRight1Dsply_B_Stat 1;
BA_ "U_P708_MY2023_Rx" SG_ 1252 BalrRight1Dsply_B_Stat 1;
BA_ "U_V710_MY2023_Rx" SG_ 1252 BalrRight1Dsply_B_Stat 1;
BA_ "U_P702_MY2024_Rx" SG_ 1252 BalrRight1Dsply_B_Stat 1;
BA_ "U_V713AV_MY2022_Rx" SG_ 1252 BalrRight1CurntY_L_Actl 1;
BA_ "U_P708_MY2023_Rx" SG_ 1252 BalrRight1CurntY_L_Actl 1;
BA_ "U_V710_MY2023_Rx" SG_ 1252 BalrRight1CurntY_L_Actl 1;
BA_ "U_P702_MY2024_Rx" SG_ 1252 BalrRight1CurntY_L_Actl 1;
BA_ "U_V713AV_MY2022_Rx" SG_ 1252 BalrRight1CurntX_L_Actl 1;
BA_ "U_P708_MY2023_Rx" SG_ 1252 BalrRight1CurntX_L_Actl 1;
BA_ "U_V710_MY2023_Rx" SG_ 1252 BalrRight1CurntX_L_Actl 1;
BA_ "U_P702_MY2024_Rx" SG_ 1252 BalrRight1CurntX_L_Actl 1;
BA_ "U_V713AV_MY2022_Rx" SG_ 1251 BalrLeft4Threat_D_Stat 1;
BA_ "U_P708_MY2023_Rx" SG_ 1251 BalrLeft4Threat_D_Stat 1;
BA_ "U_V710_MY2023_Rx" SG_ 1251 BalrLeft4Threat_D_Stat 1;
BA_ "U_P702_MY2024_Rx" SG_ 1251 BalrLeft4Threat_D_Stat 1;
BA_ "U_V713AV_MY2022_Rx" SG_ 1251 BalrLeft4Prev3Y_L_Actl 1;
BA_ "U_P708_MY2023_Rx" SG_ 1251 BalrLeft4Prev3Y_L_Actl 1;
BA_ "U_V710_MY2023_Rx" SG_ 1251 BalrLeft4Prev3Y_L_Actl 1;
BA_ "U_P702_MY2024_Rx" SG_ 1251 BalrLeft4Prev3Y_L_Actl 1;
BA_ "U_V713AV_MY2022_Rx" SG_ 1251 BalrLeft4Prev3X_L_Actl 1;
BA_ "U_P708_MY2023_Rx" SG_ 1251 BalrLeft4Prev3X_L_Actl 1;
BA_ "U_V710_MY2023_Rx" SG_ 1251 BalrLeft4Prev3X_L_Actl 1;
BA_ "U_P702_MY2024_Rx" SG_ 1251 BalrLeft4Prev3X_L_Actl 1;
BA_ "U_V713AV_MY2022_Rx" SG_ 1251 BalrLeft4Prev2Y_L_Actl 1;
BA_ "U_P708_MY2023_Rx" SG_ 1251 BalrLeft4Prev2Y_L_Actl 1;
BA_ "U_V710_MY2023_Rx" SG_ 1251 BalrLeft4Prev2Y_L_Actl 1;
BA_ "U_P702_MY2024_Rx" SG_ 1251 BalrLeft4Prev2Y_L_Actl 1;
BA_ "U_V713AV_MY2022_Rx" SG_ 1251 BalrLeft4Prev2X_L_Actl 1;
BA_ "U_P708_MY2023_Rx" SG_ 1251 BalrLeft4Prev2X_L_Actl 1;
BA_ "U_V710_MY2023_Rx" SG_ 1251 BalrLeft4Prev2X_L_Actl 1;
BA_ "U_P702_MY2024_Rx" SG_ 1251 BalrLeft4Prev2X_L_Actl 1;
BA_ "U_V713AV_MY2022_Rx" SG_ 1251 BalrLeft4Prev1Y_L_Actl 1;
BA_ "U_P708_MY2023_Rx" SG_ 1251 BalrLeft4Prev1Y_L_Actl 1;
BA_ "U_V710_MY2023_Rx" SG_ 1251 BalrLeft4Prev1Y_L_Actl 1;
BA_ "U_P702_MY2024_Rx" SG_ 1251 BalrLeft4Prev1Y_L_Actl 1;
BA_ "U_V713AV_MY2022_Rx" SG_ 1251 BalrLeft4Prev1X_L_Actl 1;
BA_ "U_P708_MY2023_Rx" SG_ 1251 BalrLeft4Prev1X_L_Actl 1;
BA_ "U_V710_MY2023_Rx" SG_ 1251 BalrLeft4Prev1X_L_Actl 1;
BA_ "U_P702_MY2024_Rx" SG_ 1251 BalrLeft4Prev1X_L_Actl 1;
BA_ "U_V713AV_MY2022_Rx" SG_ 1251 BalrLeft4Fast_B_Stat 1;
BA_ "U_P708_MY2023_Rx" SG_ 1251 BalrLeft4Fast_B_Stat 1;
BA_ "U_V710_MY2023_Rx" SG_ 1251 BalrLeft4Fast_B_Stat 1;
BA_ "U_P702_MY2024_Rx" SG_ 1251 BalrLeft4Fast_B_Stat 1;
BA_ "U_V713AV_MY2022_Rx" SG_ 1251 BalrLeft4Dsply_B_Stat 1;
BA_ "U_P708_MY2023_Rx" SG_ 1251 BalrLeft4Dsply_B_Stat 1;
BA_ "U_V710_MY2023_Rx" SG_ 1251 BalrLeft4Dsply_B_Stat 1;
BA_ "U_P702_MY2024_Rx" SG_ 1251 BalrLeft4Dsply_B_Stat 1;
BA_ "U_V713AV_MY2022_Rx" SG_ 1251 BalrLeft4CurntY_L_Actl 1;
BA_ "U_P708_MY2023_Rx" SG_ 1251 BalrLeft4CurntY_L_Actl 1;
BA_ "U_V710_MY2023_Rx" SG_ 1251 BalrLeft4CurntY_L_Actl 1;
BA_ "U_P702_MY2024_Rx" SG_ 1251 BalrLeft4CurntY_L_Actl 1;
BA_ "U_V713AV_MY2022_Rx" SG_ 1251 BalrLeft4CurntX_L_Actl 1;
BA_ "U_P708_MY2023_Rx" SG_ 1251 BalrLeft4CurntX_L_Actl 1;
BA_ "U_V710_MY2023_Rx" SG_ 1251 BalrLeft4CurntX_L_Actl 1;
BA_ "U_P702_MY2024_Rx" SG_ 1251 BalrLeft4CurntX_L_Actl 1;
BA_ "U_V713AV_MY2022_Rx" SG_ 1250 BalrLeft3Threat_D_Stat 1;
BA_ "U_P708_MY2023_Rx" SG_ 1250 BalrLeft3Threat_D_Stat 1;
BA_ "U_V710_MY2023_Rx" SG_ 1250 BalrLeft3Threat_D_Stat 1;
BA_ "U_P702_MY2024_Rx" SG_ 1250 BalrLeft3Threat_D_Stat 1;
BA_ "U_V713AV_MY2022_Rx" SG_ 1250 BalrLeft3Prev3Y_L_Actl 1;
BA_ "U_P708_MY2023_Rx" SG_ 1250 BalrLeft3Prev3Y_L_Actl 1;
BA_ "U_V710_MY2023_Rx" SG_ 1250 BalrLeft3Prev3Y_L_Actl 1;
BA_ "U_P702_MY2024_Rx" SG_ 1250 BalrLeft3Prev3Y_L_Actl 1;
BA_ "U_V713AV_MY2022_Rx" SG_ 1250 BalrLeft3Prev3X_L_Actl 1;
BA_ "U_P708_MY2023_Rx" SG_ 1250 BalrLeft3Prev3X_L_Actl 1;
BA_ "U_V710_MY2023_Rx" SG_ 1250 BalrLeft3Prev3X_L_Actl 1;
BA_ "U_P702_MY2024_Rx" SG_ 1250 BalrLeft3Prev3X_L_Actl 1;
BA_ "U_V713AV_MY2022_Rx" SG_ 1250 BalrLeft3Prev2Y_L_Actl 1;
BA_ "U_P708_MY2023_Rx" SG_ 1250 BalrLeft3Prev2Y_L_Actl 1;
BA_ "U_V710_MY2023_Rx" SG_ 1250 BalrLeft3Prev2Y_L_Actl 1;
BA_ "U_P702_MY2024_Rx" SG_ 1250 BalrLeft3Prev2Y_L_Actl 1;
BA_ "U_V713AV_MY2022_Rx" SG_ 1250 BalrLeft3Prev2X_L_Actl 1;
BA_ "U_P708_MY2023_Rx" SG_ 1250 BalrLeft3Prev2X_L_Actl 1;
BA_ "U_V710_MY2023_Rx" SG_ 1250 BalrLeft3Prev2X_L_Actl 1;
BA_ "U_P702_MY2024_Rx" SG_ 1250 BalrLeft3Prev2X_L_Actl 1;
BA_ "U_V713AV_MY2022_Rx" SG_ 1250 BalrLeft3Prev1Y_L_Actl 1;
BA_ "U_P708_MY2023_Rx" SG_ 1250 BalrLeft3Prev1Y_L_Actl 1;
BA_ "U_V710_MY2023_Rx" SG_ 1250 BalrLeft3Prev1Y_L_Actl 1;
BA_ "U_P702_MY2024_Rx" SG_ 1250 BalrLeft3Prev1Y_L_Actl 1;
BA_ "U_V713AV_MY2022_Rx" SG_ 1250 BalrLeft3Prev1X_L_Actl 1;
BA_ "U_P708_MY2023_Rx" SG_ 1250 BalrLeft3Prev1X_L_Actl 1;
BA_ "U_V710_MY2023_Rx" SG_ 1250 BalrLeft3Prev1X_L_Actl 1;
BA_ "U_P702_MY2024_Rx" SG_ 1250 BalrLeft3Prev1X_L_Actl 1;
BA_ "U_V713AV_MY2022_Rx" SG_ 1250 BalrLeft3Fast_B_Stat 1;
BA_ "U_P708_MY2023_Rx" SG_ 1250 BalrLeft3Fast_B_Stat 1;
BA_ "U_V710_MY2023_Rx" SG_ 1250 BalrLeft3Fast_B_Stat 1;
BA_ "U_P702_MY2024_Rx" SG_ 1250 BalrLeft3Fast_B_Stat 1;
BA_ "U_V713AV_MY2022_Rx" SG_ 1250 BalrLeft3Dsply_B_Stat 1;
BA_ "U_P708_MY2023_Rx" SG_ 1250 BalrLeft3Dsply_B_Stat 1;
BA_ "U_V710_MY2023_Rx" SG_ 1250 BalrLeft3Dsply_B_Stat 1;
BA_ "U_P702_MY2024_Rx" SG_ 1250 BalrLeft3Dsply_B_Stat 1;
BA_ "U_V713AV_MY2022_Rx" SG_ 1250 BalrLeft3CurntY_L_Actl 1;
BA_ "U_P708_MY2023_Rx" SG_ 1250 BalrLeft3CurntY_L_Actl 1;
BA_ "U_V710_MY2023_Rx" SG_ 1250 BalrLeft3CurntY_L_Actl 1;
BA_ "U_P702_MY2024_Rx" SG_ 1250 BalrLeft3CurntY_L_Actl 1;
BA_ "U_V713AV_MY2022_Rx" SG_ 1250 BalrLeft3CurntX_L_Actl 1;
BA_ "U_P708_MY2023_Rx" SG_ 1250 BalrLeft3CurntX_L_Actl 1;
BA_ "U_V710_MY2023_Rx" SG_ 1250 BalrLeft3CurntX_L_Actl 1;
BA_ "U_P702_MY2024_Rx" SG_ 1250 BalrLeft3CurntX_L_Actl 1;
BA_ "U_V713AV_MY2022_Rx" SG_ 1249 BalrLeft2Prev3Y_L_Actl 1;
BA_ "U_P708_MY2023_Rx" SG_ 1249 BalrLeft2Prev3Y_L_Actl 1;
BA_ "U_V710_MY2023_Rx" SG_ 1249 BalrLeft2Prev3Y_L_Actl 1;
BA_ "U_P702_MY2024_Rx" SG_ 1249 BalrLeft2Prev3Y_L_Actl 1;
BA_ "U_V713AV_MY2022_Rx" SG_ 1249 BalrLeft2Prev3X_L_Actl 1;
BA_ "U_P708_MY2023_Rx" SG_ 1249 BalrLeft2Prev3X_L_Actl 1;
BA_ "U_V710_MY2023_Rx" SG_ 1249 BalrLeft2Prev3X_L_Actl 1;
BA_ "U_P702_MY2024_Rx" SG_ 1249 BalrLeft2Prev3X_L_Actl 1;
BA_ "U_V713AV_MY2022_Rx" SG_ 1249 BalrLeft2Threat_D_Stat 1;
BA_ "U_P708_MY2023_Rx" SG_ 1249 BalrLeft2Threat_D_Stat 1;
BA_ "U_V710_MY2023_Rx" SG_ 1249 BalrLeft2Threat_D_Stat 1;
BA_ "U_P702_MY2024_Rx" SG_ 1249 BalrLeft2Threat_D_Stat 1;
BA_ "U_V713AV_MY2022_Rx" SG_ 1249 BalrLeft2Prev2Y_L_Actl 1;
BA_ "U_P708_MY2023_Rx" SG_ 1249 BalrLeft2Prev2Y_L_Actl 1;
BA_ "U_V710_MY2023_Rx" SG_ 1249 BalrLeft2Prev2Y_L_Actl 1;
BA_ "U_P702_MY2024_Rx" SG_ 1249 BalrLeft2Prev2Y_L_Actl 1;
BA_ "U_V713AV_MY2022_Rx" SG_ 1249 BalrLeft2Prev2X_L_Actl 1;
BA_ "U_P708_MY2023_Rx" SG_ 1249 BalrLeft2Prev2X_L_Actl 1;
BA_ "U_V710_MY2023_Rx" SG_ 1249 BalrLeft2Prev2X_L_Actl 1;
BA_ "U_P702_MY2024_Rx" SG_ 1249 BalrLeft2Prev2X_L_Actl 1;
BA_ "U_V713AV_MY2022_Rx" SG_ 1249 BalrLeft2Prev1Y_L_Actl 1;
BA_ "U_P708_MY2023_Rx" SG_ 1249 BalrLeft2Prev1Y_L_Actl 1;
BA_ "U_V710_MY2023_Rx" SG_ 1249 BalrLeft2Prev1Y_L_Actl 1;
BA_ "U_P702_MY2024_Rx" SG_ 1249 BalrLeft2Prev1Y_L_Actl 1;
BA_ "U_V713AV_MY2022_Rx" SG_ 1249 BalrLeft2Prev1X_L_Actl 1;
BA_ "U_P708_MY2023_Rx" SG_ 1249 BalrLeft2Prev1X_L_Actl 1;
BA_ "U_V710_MY2023_Rx" SG_ 1249 BalrLeft2Prev1X_L_Actl 1;
BA_ "U_P702_MY2024_Rx" SG_ 1249 BalrLeft2Prev1X_L_Actl 1;
BA_ "U_V713AV_MY2022_Rx" SG_ 1249 BalrLeft2Fast_B_Stat 1;
BA_ "U_P708_MY2023_Rx" SG_ 1249 BalrLeft2Fast_B_Stat 1;
BA_ "U_V710_MY2023_Rx" SG_ 1249 BalrLeft2Fast_B_Stat 1;
BA_ "U_P702_MY2024_Rx" SG_ 1249 BalrLeft2Fast_B_Stat 1;
BA_ "U_V713AV_MY2022_Rx" SG_ 1249 BalrLeft2Dsply_B_Stat 1;
BA_ "U_P708_MY2023_Rx" SG_ 1249 BalrLeft2Dsply_B_Stat 1;
BA_ "U_V710_MY2023_Rx" SG_ 1249 BalrLeft2Dsply_B_Stat 1;
BA_ "U_P702_MY2024_Rx" SG_ 1249 BalrLeft2Dsply_B_Stat 1;
BA_ "U_V713AV_MY2022_Rx" SG_ 1249 BalrLeft2CurntY_L_Actl 1;
BA_ "U_P708_MY2023_Rx" SG_ 1249 BalrLeft2CurntY_L_Actl 1;
BA_ "U_V710_MY2023_Rx" SG_ 1249 BalrLeft2CurntY_L_Actl 1;
BA_ "U_P702_MY2024_Rx" SG_ 1249 BalrLeft2CurntY_L_Actl 1;
BA_ "U_V713AV_MY2022_Rx" SG_ 1249 BalrLeft2CurntX_L_Actl 1;
BA_ "U_P708_MY2023_Rx" SG_ 1249 BalrLeft2CurntX_L_Actl 1;
BA_ "U_V710_MY2023_Rx" SG_ 1249 BalrLeft2CurntX_L_Actl 1;
BA_ "U_P702_MY2024_Rx" SG_ 1249 BalrLeft2CurntX_L_Actl 1;
BA_ "U_V713AV_MY2022_Rx" SG_ 1248 BalrLeft1Threat_D_Stat 1;
BA_ "U_P708_MY2023_Rx" SG_ 1248 BalrLeft1Threat_D_Stat 1;
BA_ "U_V710_MY2023_Rx" SG_ 1248 BalrLeft1Threat_D_Stat 1;
BA_ "U_P702_MY2024_Rx" SG_ 1248 BalrLeft1Threat_D_Stat 1;
BA_ "U_V713AV_MY2022_Rx" SG_ 1248 BalrLeft1Prev3Y_L_Actl 1;
BA_ "U_P708_MY2023_Rx" SG_ 1248 BalrLeft1Prev3Y_L_Actl 1;
BA_ "U_V710_MY2023_Rx" SG_ 1248 BalrLeft1Prev3Y_L_Actl 1;
BA_ "U_P702_MY2024_Rx" SG_ 1248 BalrLeft1Prev3Y_L_Actl 1;
BA_ "U_V713AV_MY2022_Rx" SG_ 1248 BalrLeft1Prev3X_L_Actl 1;
BA_ "U_P708_MY2023_Rx" SG_ 1248 BalrLeft1Prev3X_L_Actl 1;
BA_ "U_V710_MY2023_Rx" SG_ 1248 BalrLeft1Prev3X_L_Actl 1;
BA_ "U_P702_MY2024_Rx" SG_ 1248 BalrLeft1Prev3X_L_Actl 1;
BA_ "U_V713AV_MY2022_Rx" SG_ 1248 BalrLeft1Prev2Y_L_Actl 1;
BA_ "U_P708_MY2023_Rx" SG_ 1248 BalrLeft1Prev2Y_L_Actl 1;
BA_ "U_V710_MY2023_Rx" SG_ 1248 BalrLeft1Prev2Y_L_Actl 1;
BA_ "U_P702_MY2024_Rx" SG_ 1248 BalrLeft1Prev2Y_L_Actl 1;
BA_ "U_V713AV_MY2022_Rx" SG_ 1248 BalrLeft1Prev2X_L_Actl 1;
BA_ "U_P708_MY2023_Rx" SG_ 1248 BalrLeft1Prev2X_L_Actl 1;
BA_ "U_V710_MY2023_Rx" SG_ 1248 BalrLeft1Prev2X_L_Actl 1;
BA_ "U_P702_MY2024_Rx" SG_ 1248 BalrLeft1Prev2X_L_Actl 1;
BA_ "U_V713AV_MY2022_Rx" SG_ 1248 BalrLeft1Prev1Y_L_Actl 1;
BA_ "U_P708_MY2023_Rx" SG_ 1248 BalrLeft1Prev1Y_L_Actl 1;
BA_ "U_V710_MY2023_Rx" SG_ 1248 BalrLeft1Prev1Y_L_Actl 1;
BA_ "U_P702_MY2024_Rx" SG_ 1248 BalrLeft1Prev1Y_L_Actl 1;
BA_ "U_V713AV_MY2022_Rx" SG_ 1248 BalrLeft1Prev1X_L_Actl 1;
BA_ "U_P708_MY2023_Rx" SG_ 1248 BalrLeft1Prev1X_L_Actl 1;
BA_ "U_V710_MY2023_Rx" SG_ 1248 BalrLeft1Prev1X_L_Actl 1;
BA_ "U_P702_MY2024_Rx" SG_ 1248 BalrLeft1Prev1X_L_Actl 1;
BA_ "U_V713AV_MY2022_Rx" SG_ 1248 BalrLeft1Fast_B_Stat 1;
BA_ "U_P708_MY2023_Rx" SG_ 1248 BalrLeft1Fast_B_Stat 1;
BA_ "U_V710_MY2023_Rx" SG_ 1248 BalrLeft1Fast_B_Stat 1;
BA_ "U_P702_MY2024_Rx" SG_ 1248 BalrLeft1Fast_B_Stat 1;
BA_ "U_V713AV_MY2022_Rx" SG_ 1248 BalrLeft1Dsply_B_Stat 1;
BA_ "U_P708_MY2023_Rx" SG_ 1248 BalrLeft1Dsply_B_Stat 1;
BA_ "U_V710_MY2023_Rx" SG_ 1248 BalrLeft1Dsply_B_Stat 1;
BA_ "U_P702_MY2024_Rx" SG_ 1248 BalrLeft1Dsply_B_Stat 1;
BA_ "U_V713AV_MY2022_Rx" SG_ 1248 BalrLeft1CurntY_L_Actl 1;
BA_ "U_P708_MY2023_Rx" SG_ 1248 BalrLeft1CurntY_L_Actl 1;
BA_ "U_V710_MY2023_Rx" SG_ 1248 BalrLeft1CurntY_L_Actl 1;
BA_ "U_P702_MY2024_Rx" SG_ 1248 BalrLeft1CurntY_L_Actl 1;
BA_ "U_V713AV_MY2022_Rx" SG_ 1248 BalrLeft1CurntX_L_Actl 1;
BA_ "U_P708_MY2023_Rx" SG_ 1248 BalrLeft1CurntX_L_Actl 1;
BA_ "U_V710_MY2023_Rx" SG_ 1248 BalrLeft1CurntX_L_Actl 1;
BA_ "U_P702_MY2024_Rx" SG_ 1248 BalrLeft1CurntX_L_Actl 1;
BA_ "U_V710_MY2023_Tx" SG_ 529 OnbChrgToPcWknd_D_Actl 1;
BA_ "U_P708_MY2023_Tx" SG_ 529 OnbChrgToPcWknd_D_Actl 1;
BA_ "U_P702_MY2024_Tx" SG_ 529 OnbChrgToPcWknd_D_Actl 1;
BA_ "U_V710_MY2023_Tx" SG_ 529 OnbChrgToPcWkdy_D_Actl 1;
BA_ "U_P708_MY2023_Tx" SG_ 529 OnbChrgToPcWkdy_D_Actl 1;
BA_ "U_P702_MY2024_Tx" SG_ 529 OnbChrgToPcWkdy_D_Actl 1;
BA_ "U_V710_MY2023_Tx" SG_ 529 OnbChrgSetNow_D_Rq 1;
BA_ "U_P708_MY2023_Tx" SG_ 529 OnbChrgSetNow_D_Rq 1;
BA_ "U_P702_MY2024_Tx" SG_ 529 OnbChrgSetNow_D_Rq 1;
BA_ "U_V710_MY2023_Tx" SG_ 529 OnbChrgSetDelete_B_Rq 1;
BA_ "U_P708_MY2023_Tx" SG_ 529 OnbChrgSetDelete_B_Rq 1;
BA_ "U_P702_MY2024_Tx" SG_ 529 OnbChrgSetDelete_B_Rq 1;
BA_ "U_V710_MY2023_Tx" SG_ 529 OnbChrgPrflWknd_No_Rq 1;
BA_ "U_P708_MY2023_Tx" SG_ 529 OnbChrgPrflWknd_No_Rq 1;
BA_ "U_P702_MY2024_Tx" SG_ 529 OnbChrgPrflWknd_No_Rq 1;
BA_ "U_V710_MY2023_Tx" SG_ 529 OnbChrgPrflWkdy_No_Rq 1;
BA_ "U_P708_MY2023_Tx" SG_ 529 OnbChrgPrflWkdy_No_Rq 1;
BA_ "U_P702_MY2024_Tx" SG_ 529 OnbChrgPrflWkdy_No_Rq 1;
BA_ "GenSigSendType" SG_ 529 OnbChrgPrflUpdate_B_Rq 3;
BA_ "ECGUsedRxSignal" SG_ 529 OnbChrgPrflUpdate_B_Rq 1;
BA_ "U_V713N_MY2022_Rx" SG_ 529 OnbChrgPrflUpdate_B_Rq 1;
BA_ "U_V713AV_MY2022_Rx" SG_ 529 OnbChrgPrflUpdate_B_Rq 1;
BA_ "U_P708_MY2023_Rx" SG_ 529 OnbChrgPrflUpdate_B_Rq 1;
BA_ "U_V710_MY2023_Tx" SG_ 529 OnbChrgPrflUpdate_B_Rq 1;
BA_ "U_P708_MY2023_Tx" SG_ 529 OnbChrgPrflUpdate_B_Rq 1;
BA_ "U_P702_MY2024_Tx" SG_ 529 OnbChrgPrflUpdate_B_Rq 1;
BA_ "U_V710_MY2023_Tx" SG_ 529 OnbChrgLocIdUns_B_Rq 1;
BA_ "U_P708_MY2023_Tx" SG_ 529 OnbChrgLocIdUns_B_Rq 1;
BA_ "U_P702_MY2024_Tx" SG_ 529 OnbChrgLocIdUns_B_Rq 1;
BA_ "MetaData" SG_ 529 OnbChrgLocIdTrgt_No_Rq 1;
BA_ "GenSigSendType" SG_ 529 OnbChrgLocIdTrgt_No_Rq 3;
BA_ "U_V710_MY2023_Tx" SG_ 529 OnbChrgLocIdTrgt_No_Rq 1;
BA_ "U_P708_MY2023_Tx" SG_ 529 OnbChrgLocIdTrgt_No_Rq 1;
BA_ "U_P702_MY2024_Tx" SG_ 529 OnbChrgLocIdTrgt_No_Rq 1;
BA_ "U_V713AV_MY2022_Rx" SG_ 374 GearEngag_D_Actl 1;
BA_ "U_P708_MY2023_Rx" SG_ 374 GearEngag_D_Actl 1;
BA_ "U_V710_MY2023_Rx" SG_ 374 GearEngag_D_Actl 1;
BA_ "U_V713N_MY2022_Rx" SG_ 374 GearEngag_D_Actl 1;
BA_ "U_P702_MY2024_Rx" SG_ 374 GearEngag_D_Actl 1;
BA_ "GenSigStartValue" SG_ 374 TrnRng_D_Rq 14;
BA_ "U_V713AV_MY2022_Rx" SG_ 374 TrnRng_D_Rq 1;
BA_ "U_P708_MY2023_Rx" SG_ 374 TrnRng_D_Rq 1;
BA_ "U_V710_MY2023_Rx" SG_ 374 TrnRng_D_Rq 1;
BA_ "U_P702_MY2024_Rx" SG_ 374 TrnRng_D_Rq 1;
BA_ "MetaData" SG_ 374 GearPos_No_Cs 1;
BA_ "MetaData" SG_ 374 GearPos_No_Cnt 1;
BA_ "GenSigStartValue" SG_ 374 GearPos_D_Actl 15;
BA_ "U_V713AV_MY2022_Rx" SG_ 374 GearPos_D_Actl 1;
BA_ "U_P708_MY2023_Rx" SG_ 374 GearPos_D_Actl 1;
BA_ "U_V710_MY2023_Rx" SG_ 374 GearPos_D_Actl 1;
BA_ "U_P702_MY2024_Rx" SG_ 374 GearPos_D_Actl 1;
BA_ "GenSigStartValue" SG_ 374 GearPos_D_Trg 15;
BA_ "U_V713AV_MY2022_Rx" SG_ 374 GearPos_D_Trg 1;
BA_ "U_P708_MY2023_Rx" SG_ 374 GearPos_D_Trg 1;
BA_ "U_V710_MY2023_Rx" SG_ 374 GearPos_D_Trg 1;
BA_ "U_P702_MY2024_Rx" SG_ 374 GearPos_D_Trg 1;
BA_ "U_V713N_MY2022_Rx" SG_ 500 Dsp_SourceSetTrack_Rq 1;
BA_ "U_V713AV_MY2022_Rx" SG_ 500 Dsp_SourceSetTrack_Rq 1;
BA_ "U_P708_MY2023_Rx" SG_ 500 Dsp_SourceSetTrack_Rq 1;
BA_ "U_V710_MY2023_Rx" SG_ 500 Dsp_SourceSetTrack_Rq 1;
BA_ "U_P708_MY2023_Tx" SG_ 500 Dsp_SourceSetTrack_Rq 1;
BA_ "U_P702_MY2024_Tx" SG_ 500 Dsp_SourceSetTrack_Rq 1;
BA_ "U_V713N_MY2022_Rx" SG_ 500 Dsp_ItemNameLength_Rq 1;
BA_ "U_V713AV_MY2022_Rx" SG_ 500 Dsp_ItemNameLength_Rq 1;
BA_ "U_P708_MY2023_Rx" SG_ 500 Dsp_ItemNameLength_Rq 1;
BA_ "U_V710_MY2023_Rx" SG_ 500 Dsp_ItemNameLength_Rq 1;
BA_ "U_P708_MY2023_Tx" SG_ 500 Dsp_ItemNameLength_Rq 1;
BA_ "U_P702_MY2024_Tx" SG_ 500 Dsp_ItemNameLength_Rq 1;
BA_ "GenSigSendType" SG_ 500 Dsp_GetCDTOCDData_Rq 3;
BA_ "U_V713N_MY2022_Rx" SG_ 500 Dsp_GetCDTOCDData_Rq 1;
BA_ "U_V713AV_MY2022_Rx" SG_ 500 Dsp_GetCDTOCDData_Rq 1;
BA_ "U_P708_MY2023_Rx" SG_ 500 Dsp_GetCDTOCDData_Rq 1;
BA_ "U_V710_MY2023_Rx" SG_ 500 Dsp_GetCDTOCDData_Rq 1;
BA_ "U_P708_MY2023_Tx" SG_ 500 Dsp_GetCDTOCDData_Rq 1;
BA_ "U_P702_MY2024_Tx" SG_ 500 Dsp_GetCDTOCDData_Rq 1;
BA_ "U_V713N_MY2022_Rx" SG_ 500 Dsp_FolderNumber_Rq 1;
BA_ "U_V713AV_MY2022_Rx" SG_ 500 Dsp_FolderNumber_Rq 1;
BA_ "U_P708_MY2023_Rx" SG_ 500 Dsp_FolderNumber_Rq 1;
BA_ "U_V710_MY2023_Rx" SG_ 500 Dsp_FolderNumber_Rq 1;
BA_ "U_P708_MY2023_Tx" SG_ 500 Dsp_FolderNumber_Rq 1;
BA_ "U_P702_MY2024_Tx" SG_ 500 Dsp_FolderNumber_Rq 1;
BA_ "U_V713N_MY2022_Rx" SG_ 500 Dsp_CutItem_Rq 1;
BA_ "U_V713AV_MY2022_Rx" SG_ 500 Dsp_CutItem_Rq 1;
BA_ "U_P708_MY2023_Rx" SG_ 500 Dsp_CutItem_Rq 1;
BA_ "U_V710_MY2023_Rx" SG_ 500 Dsp_CutItem_Rq 1;
BA_ "U_P708_MY2023_Tx" SG_ 500 Dsp_CutItem_Rq 1;
BA_ "U_P702_MY2024_Tx" SG_ 500 Dsp_CutItem_Rq 1;
BA_ "GenSigSendType" SG_ 500 Dsp_AudioSourceSel_Rq 3;
BA_ "U_V713N_MY2022_Rx" SG_ 500 Dsp_AudioSourceSel_Rq 1;
BA_ "U_V713AV_MY2022_Rx" SG_ 500 Dsp_AudioSourceSel_Rq 1;
BA_ "U_P708_MY2023_Rx" SG_ 500 Dsp_AudioSourceSel_Rq 1;
BA_ "U_V710_MY2023_Rx" SG_ 500 Dsp_AudioSourceSel_Rq 1;
BA_ "U_P708_MY2023_Tx" SG_ 500 Dsp_AudioSourceSel_Rq 1;
BA_ "U_P702_MY2024_Tx" SG_ 500 Dsp_AudioSourceSel_Rq 1;
BA_ "U_V713N_MY2022_Rx" SG_ 503 Dsp_PlayFrstTrInFldr_Rq 1;
BA_ "U_V713AV_MY2022_Rx" SG_ 503 Dsp_PlayFrstTrInFldr_Rq 1;
BA_ "U_P708_MY2023_Rx" SG_ 503 Dsp_PlayFrstTrInFldr_Rq 1;
BA_ "U_V710_MY2023_Rx" SG_ 503 Dsp_PlayFrstTrInFldr_Rq 1;
BA_ "U_P708_MY2023_Tx" SG_ 503 Dsp_PlayFrstTrInFldr_Rq 1;
BA_ "U_P702_MY2024_Tx" SG_ 503 Dsp_PlayFrstTrInFldr_Rq 1;
BA_ "U_V713N_MY2022_Rx" SG_ 503 Dsp_ItemIndex_Rq 1;
BA_ "U_V713AV_MY2022_Rx" SG_ 503 Dsp_ItemIndex_Rq 1;
BA_ "U_P708_MY2023_Rx" SG_ 503 Dsp_ItemIndex_Rq 1;
BA_ "U_V710_MY2023_Rx" SG_ 503 Dsp_ItemIndex_Rq 1;
BA_ "U_P708_MY2023_Tx" SG_ 503 Dsp_ItemIndex_Rq 1;
BA_ "U_P702_MY2024_Tx" SG_ 503 Dsp_ItemIndex_Rq 1;
BA_ "U_V713N_MY2022_Rx" SG_ 503 Dsp_FolderNumber3_Rq 1;
BA_ "U_V713AV_MY2022_Rx" SG_ 503 Dsp_FolderNumber3_Rq 1;
BA_ "U_P708_MY2023_Rx" SG_ 503 Dsp_FolderNumber3_Rq 1;
BA_ "U_V710_MY2023_Rx" SG_ 503 Dsp_FolderNumber3_Rq 1;
BA_ "U_P708_MY2023_Tx" SG_ 503 Dsp_FolderNumber3_Rq 1;
BA_ "U_P702_MY2024_Tx" SG_ 503 Dsp_FolderNumber3_Rq 1;
BA_ "GenSigSendType" SG_ 503 Dsp_AudioSourceSel3_Rq 3;
BA_ "U_V713N_MY2022_Rx" SG_ 503 Dsp_AudioSourceSel3_Rq 1;
BA_ "U_V713AV_MY2022_Rx" SG_ 503 Dsp_AudioSourceSel3_Rq 1;
BA_ "U_P708_MY2023_Rx" SG_ 503 Dsp_AudioSourceSel3_Rq 1;
BA_ "U_V710_MY2023_Rx" SG_ 503 Dsp_AudioSourceSel3_Rq 1;
BA_ "U_P708_MY2023_Tx" SG_ 503 Dsp_AudioSourceSel3_Rq 1;
BA_ "U_P702_MY2024_Tx" SG_ 503 Dsp_AudioSourceSel3_Rq 1;
BA_ "U_V713N_MY2022_Rx" SG_ 412 LBC2_StartItemInd 1;
BA_ "U_V713AV_MY2022_Rx" SG_ 412 LBC2_StartItemInd 1;
BA_ "U_P708_MY2023_Rx" SG_ 412 LBC2_StartItemInd 1;
BA_ "U_V710_MY2023_Rx" SG_ 412 LBC2_StartItemInd 1;
BA_ "U_P708_MY2023_Tx" SG_ 412 LBC2_StartItemInd 1;
BA_ "U_P702_MY2024_Tx" SG_ 412 LBC2_StartItemInd 1;
BA_ "U_V713N_MY2022_Rx" SG_ 412 LBC2_SetListServ 1;
BA_ "U_V713AV_MY2022_Rx" SG_ 412 LBC2_SetListServ 1;
BA_ "U_P708_MY2023_Rx" SG_ 412 LBC2_SetListServ 1;
BA_ "U_V710_MY2023_Rx" SG_ 412 LBC2_SetListServ 1;
BA_ "U_P708_MY2023_Tx" SG_ 412 LBC2_SetListServ 1;
BA_ "U_P702_MY2024_Tx" SG_ 412 LBC2_SetListServ 1;
BA_ "GenSigSendType" SG_ 412 LBC2_Opcode 3;
BA_ "U_V713N_MY2022_Rx" SG_ 412 LBC2_Opcode 1;
BA_ "U_V713AV_MY2022_Rx" SG_ 412 LBC2_Opcode 1;
BA_ "U_P708_MY2023_Rx" SG_ 412 LBC2_Opcode 1;
BA_ "U_V710_MY2023_Rx" SG_ 412 LBC2_Opcode 1;
BA_ "U_P708_MY2023_Tx" SG_ 412 LBC2_Opcode 1;
BA_ "U_P702_MY2024_Tx" SG_ 412 LBC2_Opcode 1;
BA_ "U_V713N_MY2022_Rx" SG_ 412 LBC2_NbrOfItems 1;
BA_ "U_V713AV_MY2022_Rx" SG_ 412 LBC2_NbrOfItems 1;
BA_ "U_P708_MY2023_Rx" SG_ 412 LBC2_NbrOfItems 1;
BA_ "U_V710_MY2023_Rx" SG_ 412 LBC2_NbrOfItems 1;
BA_ "U_P708_MY2023_Tx" SG_ 412 LBC2_NbrOfItems 1;
BA_ "U_P702_MY2024_Tx" SG_ 412 LBC2_NbrOfItems 1;
BA_ "U_V713N_MY2022_Rx" SG_ 412 LBC2_ItemIndex 1;
BA_ "U_V713AV_MY2022_Rx" SG_ 412 LBC2_ItemIndex 1;
BA_ "U_P708_MY2023_Rx" SG_ 412 LBC2_ItemIndex 1;
BA_ "U_V710_MY2023_Rx" SG_ 412 LBC2_ItemIndex 1;
BA_ "U_P708_MY2023_Tx" SG_ 412 LBC2_ItemIndex 1;
BA_ "U_P702_MY2024_Tx" SG_ 412 LBC2_ItemIndex 1;
BA_ "U_V713N_MY2022_Rx" SG_ 412 LBC2_ActiveListID 1;
BA_ "U_V713AV_MY2022_Rx" SG_ 412 LBC2_ActiveListID 1;
BA_ "U_P708_MY2023_Rx" SG_ 412 LBC2_ActiveListID 1;
BA_ "U_V710_MY2023_Rx" SG_ 412 LBC2_ActiveListID 1;
BA_ "U_P708_MY2023_Tx" SG_ 412 LBC2_ActiveListID 1;
BA_ "U_P702_MY2024_Tx" SG_ 412 LBC2_ActiveListID 1;
BA_ "GenSigSendType" SG_ 493 Dsp_StatLiScanCancel_Rq 3;
BA_ "U_V713N_MY2022_Rx" SG_ 493 Dsp_StatLiScanCancel_Rq 1;
BA_ "U_V713AV_MY2022_Rx" SG_ 493 Dsp_StatLiScanCancel_Rq 1;
BA_ "U_P708_MY2023_Rx" SG_ 493 Dsp_StatLiScanCancel_Rq 1;
BA_ "U_V710_MY2023_Rx" SG_ 493 Dsp_StatLiScanCancel_Rq 1;
BA_ "U_P708_MY2023_Tx" SG_ 493 Dsp_StatLiScanCancel_Rq 1;
BA_ "GenSigSendType" SG_ 493 Dsp_StationList_Rq 3;
BA_ "U_V713N_MY2022_Rx" SG_ 493 Dsp_StationList_Rq 1;
BA_ "U_V713AV_MY2022_Rx" SG_ 493 Dsp_StationList_Rq 1;
BA_ "U_P708_MY2023_Rx" SG_ 493 Dsp_StationList_Rq 1;
BA_ "U_V710_MY2023_Rx" SG_ 493 Dsp_StationList_Rq 1;
BA_ "U_P708_MY2023_Tx" SG_ 493 Dsp_StationList_Rq 1;
BA_ "U_V713N_MY2022_Rx" SG_ 493 Dsp_StartIndex3_Rq 1;
BA_ "U_V713AV_MY2022_Rx" SG_ 493 Dsp_StartIndex3_Rq 1;
BA_ "U_P708_MY2023_Rx" SG_ 493 Dsp_StartIndex3_Rq 1;
BA_ "U_V710_MY2023_Rx" SG_ 493 Dsp_StartIndex3_Rq 1;
BA_ "U_P708_MY2023_Tx" SG_ 493 Dsp_StartIndex3_Rq 1;
BA_ "U_V713N_MY2022_Rx" SG_ 493 Dsp_RefreshFlag 1;
BA_ "U_V713AV_MY2022_Rx" SG_ 493 Dsp_RefreshFlag 1;
BA_ "U_P708_MY2023_Rx" SG_ 493 Dsp_RefreshFlag 1;
BA_ "U_V710_MY2023_Rx" SG_ 493 Dsp_RefreshFlag 1;
BA_ "U_P708_MY2023_Tx" SG_ 493 Dsp_RefreshFlag 1;
BA_ "U_V713N_MY2022_Rx" SG_ 493 Dsp_PTYCode_Rq 1;
BA_ "U_V713AV_MY2022_Rx" SG_ 493 Dsp_PTYCode_Rq 1;
BA_ "U_P708_MY2023_Rx" SG_ 493 Dsp_PTYCode_Rq 1;
BA_ "U_V710_MY2023_Rx" SG_ 493 Dsp_PTYCode_Rq 1;
BA_ "U_P708_MY2023_Tx" SG_ 493 Dsp_PTYCode_Rq 1;
BA_ "U_V713N_MY2022_Rx" SG_ 493 Dsp_ListSize_Rq 1;
BA_ "U_V713AV_MY2022_Rx" SG_ 493 Dsp_ListSize_Rq 1;
BA_ "U_P708_MY2023_Rx" SG_ 493 Dsp_ListSize_Rq 1;
BA_ "U_V710_MY2023_Rx" SG_ 493 Dsp_ListSize_Rq 1;
BA_ "U_P708_MY2023_Tx" SG_ 493 Dsp_ListSize_Rq 1;
BA_ "GenSigSendType" SG_ 493 Dsp_AFJump_Rq 3;
BA_ "U_V713N_MY2022_Rx" SG_ 493 Dsp_AFJump_Rq 1;
BA_ "U_V713AV_MY2022_Rx" SG_ 493 Dsp_AFJump_Rq 1;
BA_ "U_P708_MY2023_Rx" SG_ 493 Dsp_AFJump_Rq 1;
BA_ "U_V710_MY2023_Rx" SG_ 493 Dsp_AFJump_Rq 1;
BA_ "U_P708_MY2023_Tx" SG_ 493 Dsp_AFJump_Rq 1;
BA_ "U_V713N_MY2022_Rx" SG_ 511 Dsp_TUStartIndex2_Rq 1;
BA_ "U_V713AV_MY2022_Rx" SG_ 511 Dsp_TUStartIndex2_Rq 1;
BA_ "U_P708_MY2023_Rx" SG_ 511 Dsp_TUStartIndex2_Rq 1;
BA_ "U_V710_MY2023_Rx" SG_ 511 Dsp_TUStartIndex2_Rq 1;
BA_ "U_P708_MY2023_Tx" SG_ 511 Dsp_TUStartIndex2_Rq 1;
BA_ "U_P702_MY2024_Tx" SG_ 511 Dsp_TUStartIndex2_Rq 1;
BA_ "GenSigSendType" SG_ 511 Dsp_TUPresetArea_Rq 3;
BA_ "U_V713N_MY2022_Rx" SG_ 511 Dsp_TUPresetArea_Rq 1;
BA_ "U_V713AV_MY2022_Rx" SG_ 511 Dsp_TUPresetArea_Rq 1;
BA_ "U_P708_MY2023_Rx" SG_ 511 Dsp_TUPresetArea_Rq 1;
BA_ "U_V710_MY2023_Rx" SG_ 511 Dsp_TUPresetArea_Rq 1;
BA_ "U_P708_MY2023_Tx" SG_ 511 Dsp_TUPresetArea_Rq 1;
BA_ "U_P702_MY2024_Tx" SG_ 511 Dsp_TUPresetArea_Rq 1;
BA_ "U_V713N_MY2022_Rx" SG_ 511 Dsp_TUNbrOfPresets_Rq 1;
BA_ "U_V713AV_MY2022_Rx" SG_ 511 Dsp_TUNbrOfPresets_Rq 1;
BA_ "U_P708_MY2023_Rx" SG_ 511 Dsp_TUNbrOfPresets_Rq 1;
BA_ "U_V710_MY2023_Rx" SG_ 511 Dsp_TUNbrOfPresets_Rq 1;
BA_ "U_P708_MY2023_Tx" SG_ 511 Dsp_TUNbrOfPresets_Rq 1;
BA_ "U_P702_MY2024_Tx" SG_ 511 Dsp_TUNbrOfPresets_Rq 1;
BA_ "GenSigSendType" SG_ 511 Dsp_SetCurrTUPreset_Rq 3;
BA_ "U_V713N_MY2022_Rx" SG_ 511 Dsp_SetCurrTUPreset_Rq 1;
BA_ "U_V713AV_MY2022_Rx" SG_ 511 Dsp_SetCurrTUPreset_Rq 1;
BA_ "U_P708_MY2023_Rx" SG_ 511 Dsp_SetCurrTUPreset_Rq 1;
BA_ "U_V710_MY2023_Rx" SG_ 511 Dsp_SetCurrTUPreset_Rq 1;
BA_ "U_P708_MY2023_Tx" SG_ 511 Dsp_SetCurrTUPreset_Rq 1;
BA_ "U_P702_MY2024_Tx" SG_ 511 Dsp_SetCurrTUPreset_Rq 1;
BA_ "GenSigSendType" SG_ 511 Dsp_SetCurrTUBand_Rq 3;
BA_ "U_V713N_MY2022_Rx" SG_ 511 Dsp_SetCurrTUBand_Rq 1;
BA_ "U_V713AV_MY2022_Rx" SG_ 511 Dsp_SetCurrTUBand_Rq 1;
BA_ "U_P708_MY2023_Rx" SG_ 511 Dsp_SetCurrTUBand_Rq 1;
BA_ "U_V710_MY2023_Rx" SG_ 511 Dsp_SetCurrTUBand_Rq 1;
BA_ "U_P708_MY2023_Tx" SG_ 511 Dsp_SetCurrTUBand_Rq 1;
BA_ "U_P702_MY2024_Tx" SG_ 511 Dsp_SetCurrTUBand_Rq 1;
BA_ "GenSigSendType" SG_ 511 SdarsAudioRtng_D_Rq 3;
BA_ "U_V713N_MY2022_Rx" SG_ 511 SdarsAudioRtng_D_Rq 1;
BA_ "U_P708_MY2023_Rx" SG_ 511 SdarsAudioRtng_D_Rq 1;
BA_ "U_V710_MY2023_Rx" SG_ 511 SdarsAudioRtng_D_Rq 1;
BA_ "U_P708_MY2023_Tx" SG_ 511 SdarsAudioRtng_D_Rq 1;
BA_ "U_P702_MY2024_Tx" SG_ 511 SdarsAudioRtng_D_Rq 1;
BA_ "GenSigSendType" SG_ 257 MFD_SetTagMode 3;
BA_ "U_V713N_MY2022_Rx" SG_ 257 MFD_SetTagMode 1;
BA_ "U_V713AV_MY2022_Rx" SG_ 257 MFD_SetTagMode 1;
BA_ "U_P708_MY2023_Rx" SG_ 257 MFD_SetTagMode 1;
BA_ "U_V710_MY2023_Rx" SG_ 257 MFD_SetTagMode 1;
BA_ "U_P708_MY2023_Tx" SG_ 257 MFD_SetTagMode 1;
BA_ "GenSigSendType" SG_ 257 MFD_SetRBDSMode 3;
BA_ "U_V713N_MY2022_Rx" SG_ 257 MFD_SetRBDSMode 1;
BA_ "U_V713AV_MY2022_Rx" SG_ 257 MFD_SetRBDSMode 1;
BA_ "U_P708_MY2023_Rx" SG_ 257 MFD_SetRBDSMode 1;
BA_ "U_V710_MY2023_Rx" SG_ 257 MFD_SetRBDSMode 1;
BA_ "U_P708_MY2023_Tx" SG_ 257 MFD_SetRBDSMode 1;
BA_ "GenSigSendType" SG_ 257 MFD_SetHDModeRq 3;
BA_ "U_V713N_MY2022_Rx" SG_ 257 MFD_SetHDModeRq 1;
BA_ "U_V713AV_MY2022_Rx" SG_ 257 MFD_SetHDModeRq 1;
BA_ "U_P708_MY2023_Rx" SG_ 257 MFD_SetHDModeRq 1;
BA_ "U_V710_MY2023_Rx" SG_ 257 MFD_SetHDModeRq 1;
BA_ "U_P708_MY2023_Tx" SG_ 257 MFD_SetHDModeRq 1;
BA_ "GenSigSendType" SG_ 257 MFD_GetTagInfo 3;
BA_ "U_V713N_MY2022_Rx" SG_ 257 MFD_GetTagInfo 1;
BA_ "U_V713AV_MY2022_Rx" SG_ 257 MFD_GetTagInfo 1;
BA_ "U_P708_MY2023_Rx" SG_ 257 MFD_GetTagInfo 1;
BA_ "U_V710_MY2023_Rx" SG_ 257 MFD_GetTagInfo 1;
BA_ "U_P708_MY2023_Tx" SG_ 257 MFD_GetTagInfo 1;
BA_ "MetaData" SG_ 972 LatCtlCpbltyDStat_No_Cs 1;
BA_ "MetaData" SG_ 972 LatCtlCpbltyDStat_No_Cnt 1;
BA_ "GenSigStartValue" SG_ 972 TjaHandsOnCnfdnc_B_Est 1;
BA_ "GenSigStartValue" SG_ 972 LaHandsOff_B_Actl 1;
BA_ "U_V713N_MY2022_Rx" SG_ 972 LaHandsOff_B_Actl 1;
BA_ "U_V713AV_MY2022_Rx" SG_ 972 LaHandsOff_B_Actl 1;
BA_ "U_P708_MY2023_Rx" SG_ 972 LaHandsOff_B_Actl 1;
BA_ "U_V710_MY2023_Rx" SG_ 972 LaHandsOff_B_Actl 1;
BA_ "U_V713N_MY2022_Rx" SG_ 972 LaActDeny_B_Actl 1;
BA_ "U_V713AV_MY2022_Rx" SG_ 972 LaActDeny_B_Actl 1;
BA_ "U_P708_MY2023_Rx" SG_ 972 LaActDeny_B_Actl 1;
BA_ "U_V710_MY2023_Rx" SG_ 972 LaActDeny_B_Actl 1;
BA_ "U_P702_MY2024_Rx" SG_ 972 LaActDeny_B_Actl 1;
BA_ "GenSigStartValue" SG_ 1120 FrontDiffLck_D_RqDrv 2;
BA_ "GenSigStartValue" SG_ 1120 AwdLck_D_RqDrv 2;
BA_ "GenSigStartValue" SG_ 1120 RearDiffLck_D_RqDrv 2;
BA_ "U_V713N_MY2022_Rx" SG_ 1120 RearDiffLck_D_RqDrv 1;
BA_ "U_V713AV_MY2022_Rx" SG_ 1120 RearDiffLck_D_RqDrv 1;
BA_ "U_P708_MY2023_Rx" SG_ 1120 RearDiffLck_D_RqDrv 1;
BA_ "U_V710_MY2023_Rx" SG_ 1120 RearDiffLck_D_RqDrv 1;
BA_ "U_P702_MY2024_Rx" SG_ 1120 RearDiffLck_D_RqDrv 1;
BA_ "GenSigStartValue" SG_ 1120 AwdMde_D_RqDrv 5;
BA_ "U_V713N_MY2022_Rx" SG_ 1120 AwdMde_D_RqDrv 1;
BA_ "U_V713AV_MY2022_Rx" SG_ 1120 AwdMde_D_RqDrv 1;
BA_ "U_P708_MY2023_Rx" SG_ 1120 AwdMde_D_RqDrv 1;
BA_ "U_V710_MY2023_Rx" SG_ 1120 AwdMde_D_RqDrv 1;
BA_ "U_P702_MY2024_Rx" SG_ 1120 AwdMde_D_RqDrv 1;
BA_ "U_P702_MY2024_Rx" SG_ 1087 EngIdlShutDownT_D_Stat 1;
BA_ "U_P708_MY2023_Rx" SG_ 1087 DcacFaltMsgTxt_D2_Rq 1;
BA_ "U_V710_MY2023_Rx" SG_ 1087 DcacFaltMsgTxt_D2_Rq 1;
BA_ "U_P702_MY2024_Rx" SG_ 1087 DcacFaltMsgTxt_D2_Rq 1;
BA_ "U_V713AV_MY2022_Rx" SG_ 1087 StrtInGearMsgTxt_D_Rq 1;
BA_ "U_P708_MY2023_Rx" SG_ 1087 StrtInGearMsgTxt_D_Rq 1;
BA_ "U_V710_MY2023_Rx" SG_ 1087 StrtInGearMsgTxt_D_Rq 1;
BA_ "U_P702_MY2024_Rx" SG_ 1087 StrtInGearMsgTxt_D_Rq 1;
BA_ "U_P708_MY2023_Rx" SG_ 787 PwTgateInhbtMsgTxt_B_Rq 1;
BA_ "U_P702_MY2024_Rx" SG_ 787 PwTgateInhbtMsgTxt_B_Rq 1;
BA_ "WakeupSignal" SG_ 787 DrLckCnt_No_ActlTgate 1;
BA_ "U_V713AV_MY2022_Rx" SG_ 787 PwTgateStepMsgTxt_B_Rq 1;
BA_ "U_P708_MY2023_Rx" SG_ 787 PwTgateStepMsgTxt_B_Rq 1;
BA_ "U_V710_MY2023_Rx" SG_ 787 PwTgateStepMsgTxt_B_Rq 1;
BA_ "U_P702_MY2024_Rx" SG_ 787 PwTgateStepMsgTxt_B_Rq 1;
BA_ "U_V713AV_MY2022_Rx" SG_ 787 PwTgateMsgTxt_B_Rq 1;
BA_ "U_P708_MY2023_Rx" SG_ 787 PwTgateMsgTxt_B_Rq 1;
BA_ "U_V710_MY2023_Rx" SG_ 787 PwTgateMsgTxt_B_Rq 1;
BA_ "U_P702_MY2024_Rx" SG_ 787 PwTgateMsgTxt_B_Rq 1;
BA_ "U_P708_MY2023_Rx" SG_ 787 PwTgateLamp_B_Rq 1;
BA_ "U_V713AV_MY2022_Rx" SG_ 787 PwTgateLamp_B_Rq 1;
BA_ "U_V710_MY2023_Rx" SG_ 787 PwTgateLamp_B_Rq 1;
BA_ "U_P702_MY2024_Rx" SG_ 787 PwTgateLamp_B_Rq 1;
BA_ "WakeupSignal" SG_ 787 DrTgateChime2_D_Rq 1;
BA_ "U_V713N_MY2022_Rx" SG_ 787 DrTgateChime2_D_Rq 1;
BA_ "U_V713AV_MY2022_Rx" SG_ 787 DrTgateChime2_D_Rq 1;
BA_ "U_P708_MY2023_Rx" SG_ 787 DrTgateChime2_D_Rq 1;
BA_ "U_V710_MY2023_Rx" SG_ 787 DrTgateChime2_D_Rq 1;
BA_ "U_P702_MY2024_Rx" SG_ 787 DrTgateChime2_D_Rq 1;
BA_ "WakeupSignal" SG_ 787 DrTGate_D_Rq 1;
BA_ "WakeupSignal" SG_ 787 PwLftgtIntSw_B_Stat 1;
BA_ "U_P708_MY2023_Rx" SG_ 787 PwLftgtIntSw_B_Stat 1;
BA_ "U_V710_MY2023_Rx" SG_ 787 PwLftgtIntSw_B_Stat 1;
BA_ "U_P702_MY2024_Rx" SG_ 787 PwLftgtIntSw_B_Stat 1;
BA_ "U_V713N_MY2022_Rx" SG_ 787 Power_Liftgate_Mode_Stt 1;
BA_ "U_P708_MY2023_Rx" SG_ 787 Power_Liftgate_Mode_Stt 1;
BA_ "U_V710_MY2023_Rx" SG_ 787 Power_Liftgate_Mode_Stt 1;
BA_ "U_P702_MY2024_Rx" SG_ 787 Power_Liftgate_Mode_Stt 1;
BA_ "WakeupSignal" SG_ 819 DrPrsntPsngr_D_Stat 1;
BA_ "U_V713AV_MY2022_Rx" SG_ 819 DrPrsntPsngr_D_Stat 1;
BA_ "U_P708_MY2023_Rx" SG_ 819 DrPrsntPsngr_D_Stat 1;
BA_ "U_V710_MY2023_Rx" SG_ 819 DrPrsntPsngr_D_Stat 1;
BA_ "U_P702_MY2024_Rx" SG_ 819 DrPrsntPsngr_D_Stat 1;
BA_ "U_V713AV_MY2022_Rx" SG_ 819 DrPsngrMsgTxt_B_Rq 1;
BA_ "U_P708_MY2023_Rx" SG_ 819 DrPsngrMsgTxt_B_Rq 1;
BA_ "U_V710_MY2023_Rx" SG_ 819 DrPsngrMsgTxt_B_Rq 1;
BA_ "U_P702_MY2024_Rx" SG_ 819 DrPsngrMsgTxt_B_Rq 1;
BA_ "WakeupSignal" SG_ 819 DrPrsntRearPsngr_D_Stat 1;
BA_ "U_V713AV_MY2022_Rx" SG_ 819 DrPrsntRearPsngr_D_Stat 1;
BA_ "U_P708_MY2023_Rx" SG_ 819 DrPrsntRearPsngr_D_Stat 1;
BA_ "U_V710_MY2023_Rx" SG_ 819 DrPrsntRearPsngr_D_Stat 1;
BA_ "U_P702_MY2024_Rx" SG_ 819 DrPrsntRearPsngr_D_Stat 1;
BA_ "WakeupSignal" SG_ 819 Memory_3_SwPsngr_Stat 1;
BA_ "WakeupSignal" SG_ 819 Memory_2_SwPsngr_Stat 1;
BA_ "WakeupSignal" SG_ 819 Memory_1_SwPsngr_Stat 1;
BA_ "WakeupSignal" SG_ 819 Pasngr_Lock_Sw_Stat 1;
BA_ "WakeupSignal" SG_ 819 Pasngr_Lock_Sw_Cnt 1;
BA_ "MetaData" SG_ 819 Pasngr_Lock_Sw_Cnt 1;
BA_ "WakeupSignal" SG_ 819 ChildLckFdbckRp_B_Stat 1;
BA_ "WakeupSignal" SG_ 818 DrPrsntDrv_D_Stat 1;
BA_ "U_V713AV_MY2022_Rx" SG_ 818 DrPrsntDrv_D_Stat 1;
BA_ "U_P708_MY2023_Rx" SG_ 818 DrPrsntDrv_D_Stat 1;
BA_ "U_V710_MY2023_Rx" SG_ 818 DrPrsntDrv_D_Stat 1;
BA_ "U_P702_MY2024_Rx" SG_ 818 DrPrsntDrv_D_Stat 1;
BA_ "WakeupSignal" SG_ 818 DrPrsntRearDrv_D_Stat 1;
BA_ "U_V713AV_MY2022_Rx" SG_ 818 DrPrsntRearDrv_D_Stat 1;
BA_ "U_P708_MY2023_Rx" SG_ 818 DrPrsntRearDrv_D_Stat 1;
BA_ "U_V710_MY2023_Rx" SG_ 818 DrPrsntRearDrv_D_Stat 1;
BA_ "U_P702_MY2024_Rx" SG_ 818 DrPrsntRearDrv_D_Stat 1;
BA_ "U_V713AV_MY2022_Rx" SG_ 818 DrDrvMsgTxt_B_Rq 1;
BA_ "U_P708_MY2023_Rx" SG_ 818 DrDrvMsgTxt_B_Rq 1;
BA_ "U_V710_MY2023_Rx" SG_ 818 DrDrvMsgTxt_B_Rq 1;
BA_ "U_P702_MY2024_Rx" SG_ 818 DrDrvMsgTxt_B_Rq 1;
BA_ "WakeupSignal" SG_ 818 ChildLckPw_N_Cnt 1;
BA_ "WakeupSignal" SG_ 818 KeyCylSwDrvDr_D_Stat 1;
BA_ "WakeupSignal" SG_ 818 Driver_Lock_Sw_Stat 1;
BA_ "WakeupSignal" SG_ 818 Driver_Lock_Sw_Cnt 1;
BA_ "MetaData" SG_ 818 Driver_Lock_Sw_Cnt 1;
BA_ "WakeupSignal" SG_ 818 ChildLckPw_D_Rq 1;
BA_ "WakeupSignal" SG_ 818 ChildLckFdbckRd_B_Stat 1;
BA_ "U_V713N_MY2022_Rx" SG_ 818 RvrseMirrorChime_B_Rq 1;
BA_ "U_V713AV_MY2022_Rx" SG_ 818 RvrseMirrorChime_B_Rq 1;
BA_ "U_P708_MY2023_Rx" SG_ 818 RvrseMirrorChime_B_Rq 1;
BA_ "U_V710_MY2023_Rx" SG_ 818 RvrseMirrorChime_B_Rq 1;
BA_ "U_P702_MY2024_Rx" SG_ 818 RvrseMirrorChime_B_Rq 1;
VAL_ 662 RgstrSetIbr_D_Rq 7 "NotUsed_2" 6 "NotUsed_1" 5 "Close" 4 "Open" 3 "FeatureButtonChange" 2 "FeatureManualChange" 1 "ManualChange" 0 "NoChange" ;
VAL_ 662 RgstrSetObr_D_Rq 7 "NotUsed_2" 6 "NotUsed_1" 5 "Close" 4 "Open" 3 "FeatureButtonChange" 2 "FeatureManualChange" 1 "ManualChange" 0 "NoChange" ;
VAL_ 662 RgstrSetIbl_D_Rq 7 "NotUsed_2" 6 "NotUsed_1" 5 "Close" 4 "Open" 3 "FeatureButtonChange" 2 "FeatureManualChange" 1 "ManualChange" 0 "NoChange" ;
VAL_ 662 RgstrSetObl_D_Rq 7 "NotUsed_2" 6 "NotUsed_1" 5 "Close" 4 "Open" 3 "FeatureButtonChange" 2 "FeatureManualChange" 1 "ManualChange" 0 "NoChange" ;
VAL_ 662 ActvButtnRight_D_Rq 15 "NotUsed_4" 14 "NotUsed_3" 13 "NotUsed_2" 12 "NotUsed_1" 11 "Cycle_I_RHS" 10 "Cycle_--_RHS" 9 "Cycle_O_RHS" 8 "Cycle_C_RHS" 7 "Cycle_8_RHS" 6 "PresetTwoSaveRHS" 5 "PresetOneSaveRHS" 4 "PresetTwoRHS" 3 "PresetOneRHS" 2 "OffBodyRHS" 1 "OnBodyRHS" 0 "NonePressed" ;
VAL_ 662 ActvButtnLeft_D_Rq 15 "NotUsed_4" 14 "NotUsed_3" 13 "NotUsed_2" 12 "NotUsed_1" 11 "Cycle_I_LHS" 10 "Cycle_--_LHS" 9 "Cycle_O_LHS" 8 "Cycle_C_LHS" 7 "Cycle_8_LHS" 6 "PresetTwoSaveLHS" 5 "PresetOneSaveLHS" 4 "PresetTwoLHS" 3 "PresetOneLHS" 2 "OffBodyLHS" 1 "OnBodyLHS" 0 "NonePressed" ;
VAL_ 662 Third_Rear_Set_Temp 31 "HI" 30 "29_5" 29 "29_0" 28 "28_5" 27 "28_0" 26 "27_5" 25 "27_0" 24 "26_5" 23 "26_0" 22 "25_5" 21 "25_0" 20 "24_5" 19 "24_0" 18 "23_5" 17 "23_0" 16 "22_5" 15 "22_0" 14 "21_5" 13 "21_0" 12 "20_5" 11 "20_0" 10 "19_5" 9 "19_0" 8 "18_5" 7 "18_0" 6 "17_5" 5 "17_0" 4 "16_5" 3 "16_0" 2 "15_5" 1 "LO" 0 "No_Request" ;
VAL_ 662 Third_Rear_Blower_Speed 15 "NotUsed_6" 14 "NotUsed_5" 13 "NotUsed_4" 12 "NotUsed_3" 11 "NotUsed_2" 10 "Zero_Blower" 9 "Max_Blower" 8 "Min_Blower" 7 "Blower_Speed_7" 6 "Blower_Speed_6" 5 "Blower_Speed_5" 4 "Blower_Speed_4" 3 "Blower_Speed_3" 2 "Blower_Speed_2" 1 "Blower_Speed_1" 0 "No_Request" ;
VAL_ 662 Rear_Temp 15 "NotUsed_6" 14 "NotUsed_5" 13 "NotUsed_4" 12 "NotUsed_3" 11 "NotUsed_2" 10 "NotUsed_1" 9 "Max_Heating" 8 "Level_3_Heating" 7 "Level_2_Heating" 6 "Level_1_Heating" 5 "No_Heating_Cooling" 4 "Level_1_Cooling" 3 "Level_2_Cooling" 2 "Level_3_Cooling" 1 "Max_Cooling" 0 "No_Request" ;
VAL_ 662 Rear_Set_Temp 31 "HI" 30 "29_5" 29 "29_0" 28 "28_5" 27 "28_0" 26 "27_5" 25 "27_0" 24 "26_5" 23 "26_0" 22 "25_5" 21 "25_0" 20 "24_5" 19 "24_0" 18 "23_5" 17 "23_0" 16 "22_5" 15 "22_0" 14 "21_5" 13 "21_0" 12 "20_5" 11 "20_0" 10 "19_5" 9 "19_0" 8 "18_5" 7 "18_0" 6 "17_5" 5 "17_0" 4 "16_5" 3 "16_0" 2 "15_5" 1 "LO" 0 "No_Request" ;
VAL_ 662 Rear_Blower_Speed 15 "NotUsed_6" 14 "NotUsed_5" 13 "NotUsed_4" 12 "NotUsed_3" 11 "NotUsed_2" 10 "Zero_Blower" 9 "Max_Blower" 8 "Min_Blower" 7 "Blower_Speed_7" 6 "Blower_Speed_6" 5 "Blower_Speed_5" 4 "Blower_Speed_4" 3 "Blower_Speed_3" 2 "Blower_Speed_2" 1 "Blower_Speed_1" 0 "No_Request" ;
VAL_ 662 Running_Board_Cmd2 3 "Unused" 2 "Manually_Deployed" 1 "All_Enabled" 0 "All_Disabled" ;
VAL_ 515 PtIgnSwtch_D_Stat 3 "Faulty" 2 "No_Data_Exists" 1 "On" 0 "Off" ;
VAL_ 513 BptAllw_Pw_Dsply 1023 "Fault" 1022 "NoDataExists" ;
VAL_ 513 BptRngeRsrvMet_B_Stat 1 "Yes" 0 "No" ;
VAL_ 513 BptPwOut_B_Dsply 1 "Yes" 0 "No" ;
VAL_ 513 BptStrtStop_D_Stat 3 "NotUsed_1" 2 "Start" 1 "Stop" 0 "NoRequest" ;
VAL_ 513 BptComm_D_RqHtrn 9 "EnergyTransferFault" 8 "EnergyTransferEnd" 7 "VehicleEnergyTransferActv" 6 "VehicleEnergyTransferReady" 5 "VehiclePreChargeReady" 4 "VehicleEnergyTransferWait" 3 "ConfirmConnection" 2 "VehicleReadyToToggle" 1 "AttemptDgtlCommunication" 0 "NoDigitalCommunication" 15 "NotUsed_6" 14 "NotUsed_5" 13 "NotUsed_4" 12 "NotUsed_3" 11 "NotUsed_2" 10 "NotUsed_1" ;
VAL_ 513 BptMde_D_Stat 7 "NotUsed_4" 6 "NotUsed_3" 5 "NotUsed_2" 4 "NotUsed_1" 3 "Automatic" 2 "Manual" 1 "Off" 0 "Null" ;
VAL_ 513 Bpt_D_StatHtrn 15 "Faulty" 14 "NotUsed_8" 13 "NotUsed_7" 12 "NotUsed_6" 11 "NotUsed_5" 10 "NotUsed_4" 9 "NotUsed_3" 8 "NotUsed_2" 7 "NotUsed_1" 6 "VehicleFault" 5 "EvseFault" 4 "BptActive" 3 "Precharge" 2 "BptReady" 1 "Initialization" 0 "NotReady" ;
VAL_ 513 BptSustn_B_Rq 1 "Active" 0 "Inactive" ;
VAL_ 513 GridSrvc01_B_Stat 1 "On" 0 "Off" ;
VAL_ 513 BattTracTeColr_D_Dsply 3 "NotUsed" 2 "ColorForSeverlyLimited" 1 "ColorForLimited" 0 "ColorForNormal" ;
VAL_ 513 MtrTracTeColr_D_Dsply 3 "NotUsed" 2 "ColorForSeverlyLimited" 1 "ColorForLimited" 0 "ColorForNormal" ;
VAL_ 148 VehYawWActl_D_Qf 3 "OK" 2 "Not_Within_Specifications" 1 "No_Data_Exists" 0 "Faulty" ;
VAL_ 148 VehRolWActl_D_Qf 3 "OK" 2 "Not_Within_Specifications" 1 "No_Data_Exists" 0 "Faulty" ;
VAL_ 148 VehYaw_W_Actl 65535 "Faulty" 65534 "NoDataExists" ;
VAL_ 148 VehRol_W_Actl 65535 "Faulty" 65534 "NoDataExists" ;
VAL_ 1042 VehRol_An_Dsply 127 "Faulty" 126 "NoDataExists" ;
VAL_ 1042 RearDiffLck_Tq_RqMn 4095 "Faulty" ;
VAL_ 1042 VehPtch_An_Dsply 127 "Faulty" 126 "NoDataExists" ;
VAL_ 828 DrvSpotLight_B_Rq 1 "Yes" 0 "No" ;
VAL_ 828 SpotLghtRight_D_Stat 1 "On" 0 "Off" ;
VAL_ 828 RearPassWindowPos 7 "Unused2" 6 "Unused1" 5 "Fully_Open" 4 "Bet60Percent_FullyOpen" 3 "Bet10Percent_60Percent" 2 "BetFully_10PercentOpen" 1 "Fully_Closed" 0 "Undefined" ;
VAL_ 828 PassWindowPosition 7 "Unused2" 6 "Unused1" 5 "Fully_Open" 4 "Bet60Percent_FullyOpen" 3 "Bet10Percent_60Percent" 2 "BetFully_10PercentOpen" 1 "Fully_Closed" 0 "Undefined" ;
VAL_ 828 SpotLghtLeft_D_Stat 1 "On" 0 "Off" ;
VAL_ 330 TrnFaltOpenClu_B_Stat 1 "MayOpenClutch" 0 "Normal" ;
VAL_ 330 TrnAout_W_ActlUnfilt 32767 "Fault" 32766 "Unknown" ;
VAL_ 512 PtDrvMde_D_Stat 15 "Faulty" 14 "NotUsed11" 13 "NotUsed10" 12 "NotUsed9" 11 "NotUsed8" 10 "NotUsed7" 9 "NotUsed6" 8 "Track" 7 "Drag" 6 "Rock" 5 "Baja" 4 "Sand" 3 "TowHaulGradeAssist" 2 "SnowWet" 1 "Sport" 0 "Normal" ;
VAL_ 862 TwHlGrdAsst_B_RqTrn 1 "On" 0 "Off" ;
VAL_ 862 ApaSwtch_D_RqDrv 3 "NotUsed2" 2 "NotUsed1" 1 "Pressed" 0 "Not_Pressed" ;
VAL_ 862 HvacBlwrFront_D_Stat 31 "Not_Used" 20 "Full_On" 19 "95_Percent" 18 "90_Percent" 17 "85_Percent" 16 "80_Percent" 15 "75_Percent" 14 "70_Percent" 13 "65_Percent" 12 "60_Percent" 11 "55_Percent" 10 "50_Percent" 9 "45_Percent" 8 "40_Percent" 7 "35_Percent" 6 "30_Percent" 5 "25_Percent" 4 "20_Percent" 3 "15_Percent" 2 "10_Percent" 1 "5_Percent" 0 "Off" ;
VAL_ 862 HvacBlwrRear_D_Stat 31 "Not_Used" 20 "Full_On" 19 "95_Percent" 18 "90_Percent" 17 "85_Percent" 16 "80_Percent" 15 "75_Percent" 14 "70_Percent" 13 "65_Percent" 12 "60_Percent" 11 "55_Percent" 10 "50_Percent" 9 "45_Percent" 8 "40_Percent" 7 "35_Percent" 6 "30_Percent" 5 "25_Percent" 4 "20_Percent" 3 "15_Percent" 2 "10_Percent" 1 "5_Percent" 0 "Off" ;
VAL_ 862 EcoMde_D_RqDrv 3 "Faulty" 2 "On" 1 "Off" 0 "Null" ;
VAL_ 862 ClimtThrmlLoad_No_Actl 255 "Fault" ;
VAL_ 862 CamraDefog_B_Actl 1 "On" 0 "Off" ;
VAL_ 862 CabnAmb_Te_Actl 255 "Fault" ;
VAL_ 862 AutoStpHvacDelta_I_Est 255 "Fault" ;
VAL_ 831 PassMirrorCmd 7 "Unused" 6 "Unfold" 5 "Fold" 4 "Right" 3 "Left" 2 "Down" 1 "Up" 0 "Idle" ;
VAL_ 831 DipMirrorPosPassenger 1 "Dipped" 0 "Off" ;
VAL_ 831 MirrorTelescopic_D_Rq 3 "NotUsed" 2 "Retract" 1 "Extend" 0 "Null" ;
VAL_ 831 RearPassWindowLockCmd 1 "Enable" 0 "Disable" ;
VAL_ 831 RearPassWindowCmd 7 "Unused2" 6 "Unused1" 5 "NotDefined" 4 "Audo_Down" 3 "Manual_Down" 2 "Auto_Up" 1 "Manual_Up" 0 "Idle" ;
VAL_ 831 PassWindowCmd 7 "Unused2" 6 "Unused1" 5 "NotDefined" 4 "Audo_Down" 3 "Manual_Down" 2 "Auto_Up" 1 "Manual_Up" 0 "Idle" ;
VAL_ 831 ActiveStoragePassenger 7 "Unused3" 6 "Unused2" 5 "Unused1" 4 "StoreDipMemoryButton4" 3 "StoreDipMemoryButton3" 2 "StoreDipMemoryButton2" 1 "StoreDipMemoryButton1" 0 "Off" ;
VAL_ 831 RearDriverWindowPos 7 "Unused2" 6 "Unused1" 5 "Fully_Open" 4 "Bet60Percent_FullyOpen" 3 "Bet10Percent_60Percent" 2 "BetFully_10PercentOpen" 1 "Fully_Closed" 0 "Undefined" ;
VAL_ 831 DriverWindowPosition 7 "Unused2" 6 "Unused1" 5 "Fully_Open" 4 "Bet60Percent_FullyOpen" 3 "Bet10Percent_60Percent" 2 "BetFully_10PercentOpen" 1 "Fully_Closed" 0 "Undefined" ;
VAL_ 331 TrnAout2_W_ActlUnfilt 65535 "Fault" 65534 "NoDataExists" ;
VAL_ 331 CmbbEngTqMn_B_ActlHtrn 1 "Active" 0 "Inactive" ;
VAL_ 331 CmbbDeny_B_ActlHtrn 1 "Yes" 0 "No" ;
VAL_ 965 TrnkFrontPrim_B_Falt 1 "Fault" 0 "NoFault" ;
VAL_ 965 TrnkFrontEmgcy_D_Stat 3 "NotDetermined" 2 "SwitchState2" 1 "SwitchState1" 0 "NotPressed" ;
VAL_ 965 PtWakeupActv4_B_Rq 1 "On" 0 "Off" ;
VAL_ 965 TrunkFrontOpen_D_Stat 3 "NotUsed" 2 "NotRestricted" 1 "Restricted" 0 "Null" ;
VAL_ 1242 EngExhMdeQuietCstm_D_Rq 7 "Faulty" 6 "NotUsed_2" 5 "NotUsed_1" 4 "Track" 3 "Sport" 2 "Normal" 1 "Stealth" 0 "Null" ;
VAL_ 1242 StopStrtCstm_D_Rq 3 "Faulty" 2 "On" 1 "Off" 0 "NotAvailable" ;
VAL_ 1242 SelDrvMdeCstmPt_D_Rq 31 "Faulty" 30 "NotUsed15" 29 "NotUsed14" 28 "NotUsed13" 27 "NotUsed12" 26 "NotUsed11" 25 "NotUsed10" 24 "NotUsed9" 23 "NotUsed8" 22 "NotUsed7" 21 "CustomMode" 20 "TrackMode" 19 "OnePedalDrive" 18 "EvLaterChargerMode" 17 "EvNowMode" 16 "DragMode" 15 "HighSpeedDesertMode_Baja" 14 "SportAdaptiveMode" 13 "NotAvailable_13" 12 "NotAvailable_12" 11 "NotAvailable_11" 10 "NotAvailable_10" 9 "RockCrawlMode" 8 "MudRutsMode" 7 "SandMode" 6 "EconomyMode" 5 "GrassGravelSnow" 4 "NotAvailable_04" 3 "TowHaulMode" 2 "NotAvailable_02" 1 "SportMode" 0 "NormalMode" ;
VAL_ 1245 RearDiffLckLamp_D_Cstm 3 "Not_Used" 2 "Flash" 1 "On" 0 "Off" ;
VAL_ 1245 FrontDiffLckLamp_D_Cstm 3 "Fast_Flash" 2 "Slow_Flash" 1 "On" 0 "Off" ;
VAL_ 1245 AwdMdeCstm_D_RqDrv 7 "Faulty" 6 "NotUsed_3" 5 "NotUsed_2" 4 "NotUsed_1" 3 "FourByFourLow" 2 "FourByFourHigh" 1 "FourByFourAuto" 0 "FourByTwo" ;
VAL_ 1245 SelDrvMdeAwd2_D_Cstm 31 "Faulty" 30 "NotUsed_17" 29 "NotUsed_16" 28 "NotUsed_15" 27 "NotUsed_14" 26 "NotUsed_13" 25 "NotUsed_12" 24 "NotUsed_11" 23 "NotUsed_10" 22 "NotUsed_9" 21 "NotUsed_8" 20 "CustomMode" 19 "OnePedalDrive" 18 "DragMode" 17 "EvLaterChargeMode" 16 "EvNowMode" 15 "TrackMode" 14 "RoughRoadMode" 13 "NotAvailable" 12 "HighSpeedDesertMode_Baja" 11 "SportAdaptiveMode" 10 "RockCrawlMode" 9 "MudRutsMode" 8 "SandMode" 7 "EconomyMode" 6 "GrassGravelSnow" 5 "TowHaulMode" 4 "SportMode" 3 "Normal_4L" 2 "Normal_4A" 1 "Normal_2H" 0 "NormalMode" ;
VAL_ 781 TrlrTireDual_D_Stat 15 "NotUsed_11" 14 "NotUsed_10" 13 "NotUsed_9" 12 "NotUsed_8" 11 "NotUsed_7" 10 "NotUsed_6" 9 "NotUsed_5" 8 "NotUsed_4" 7 "NotUsed_3" 6 "NotUsed_2" 5 "NotUsed_1" 4 "NotSupported" 3 "Invalid" 2 "InnerTire" 1 "OuterTire" 0 "SystemUnknown" ;
VAL_ 781 TrlrTireSys_D_Stat 15 "NotUsed" 14 "TiresNotTrained" 13 "TrainingComplete" 12 "TrainLMTire" 11 "TrainLRTire" 10 "TrainRMTire" 9 "TrainRRTire" 8 "TrainRFTire" 7 "TrainLFTire" 6 "RequestPressureThresh" 5 "RequestTireCount" 4 "SystemActive" 3 "TireLow" 2 "SensorFault" 1 "System Fault" 0 "SystemUnknown" ;
VAL_ 781 TrlrTireCnt_D_Stat 7 "Faulty" 6 "TwelveTire" 5 "EightTire" 4 "FourTireOneAxle" 3 "SixTire" 2 "FourTire" 1 "TwoTire" 0 "Unconfigured" ;
VAL_ 781 Chirp_D_RqTrlr 3 "NotUsed" 2 "Chirp_2" 1 "Chirp_1" 0 "NoRequest" ;
VAL_ 1022 TrlrTireTSensIRM_D_Stat 3 "Faulty" 2 "HighTempWarning" 1 "Normal" 0 "NotAvailable" ;
VAL_ 1022 TrlrTireTSensIRF_D_Stat 3 "Faulty" 2 "HighTempWarning" 1 "Normal" 0 "NotAvailable" ;
VAL_ 1022 TrlrTireIRR_T_Actl 255 "NotSupported" 254 "Invalid" ;
VAL_ 1022 TrlrTireIRM_T_Actl 255 "NotSupported" 254 "Invalid" ;
VAL_ 1022 TrlrTireILR_T_Actl 255 "NotSupported" 254 "Invalid" ;
VAL_ 1022 TrlrTireILM_T_Actl 255 "NotSupported" 254 "Invalid" ;
VAL_ 1022 TrlrTireILF_T_Actl 255 "NotSupported" 254 "Invalid" ;
VAL_ 1022 TrlrTireIRF_T_Actl 255 "NotSupported" 254 "Invalid" ;
VAL_ 1022 TrlrTireTSensIRR_D_Stat 3 "Faulty" 2 "HighTempWarning" 1 "Normal" 0 "NotAvailable" ;
VAL_ 1022 TrlrTireTSensILR_D_Stat 3 "Faulty" 2 "HighTempWarning" 1 "Normal" 0 "NotAvailable" ;
VAL_ 1022 TrlrTireTSensILM_D_Stat 3 "Faulty" 2 "HighTempWarning" 1 "Normal" 0 "NotAvailable" ;
VAL_ 1022 TrlrTireTSensILF_D_Stat 3 "Faulty" 2 "HighTempWarning" 1 "Normal" 0 "NotAvailable" ;
VAL_ 903 AprSnd_D_Rq 63 "NotUsed_24" 62 "NotUsed_23" 61 "NotUsed_22" 60 "NotUsed_21" 59 "NotUsed_20" 58 "NotUsed_19" 57 "NotUsed_18" 56 "NotUsed_17" 55 "NotUsed_16" 54 "NotUsed_15" 53 "NotUsed_14" 52 "NotUsed_13" 51 "NotUsed_12" 50 "NotUsed_11" 49 "NotUsed_10" 48 "NotUsed_9" 47 "NotUsed_8" 46 "NotUsed_7" 45 "NotUsed_6" 44 "NotUsed_5" 43 "NotUsed_4" 42 "NotUsed_3" 41 "NotUsed_2" 40 "ROpenDoor" 39 "MgMercOpenDoor" 38 "MgRecAuthFail_Max" 37 "RCustCareCalling" 36 "MgRecCustCareCalling" 35 "RCallCustCare" 34 "MgRecCallCustCare" 33 "RItemDetection" 32 "MgRecItemDetection" 31 "MgMercItemDetection" 30 "MgRecOpenDoor" 29 "MgMercLoadOrder" 28 "MgRecBarcodeError" 27 "MgRecBarcode" 26 "RAuthFailMax" 25 "MgMercAuthFailMax" 24 "RAuthFail" 23 "MgMercAuthFail" 22 "R_6ft" 21 "MgRec_6ft" 20 "RAuthSucc" 19 "MgRecAuthSucc" 18 "MgMercAuthSucc" 17 "RMaxTime" 16 "MgRecMaxTime" 15 "MgMercMaxTime" 14 "RExtendTimeUnloading" 13 "RExtendTimeLoading" 12 "MgReciExtendTime" 11 "MgMercExtendTime" 10 "RTimeOutLoading" 9 "RTimeOutUnloading" 8 "MgMercTimeOut" 7 "MgRecTimeOut" 6 "RBttnPressKeypad" 5 "MgRecBttnPressKeypad" 4 "MgMercBttnPressKeypad" 3 "MgMercBttnPressOrder" 2 "RNudge" 1 "MgMercNudge" 0 "NoSound" ;
VAL_ 901 AplSnd_D_Rq 63 "NotUsed_24" 62 "NotUsed_23" 61 "NotUsed_22" 60 "NotUsed_21" 59 "NotUsed_20" 58 "NotUsed_19" 57 "NotUsed_18" 56 "NotUsed_17" 55 "NotUsed_16" 54 "NotUsed_15" 53 "NotUsed_14" 52 "NotUsed_13" 51 "NotUsed_12" 50 "NotUsed_11" 49 "NotUsed_10" 48 "NotUsed_9" 47 "NotUsed_8" 46 "NotUsed_7" 45 "NotUsed_6" 44 "NotUsed_5" 43 "NotUsed_4" 42 "NotUsed_3" 41 "NotUsed_2" 40 "ROpenDoor" 39 "MgMercOpenDoor" 38 "MgRecAuthFail_Max" 37 "RCustCareCalling" 36 "MgRecCustCareCalling" 35 "RCallCustCare" 34 "MgRecCallCustCare" 33 "RItemDetection" 32 "MgRecItemDetection" 31 "MgMercItemDetection" 30 "MgRecOpenDoor" 29 "MgMercLoadOrder" 28 "MgRecBarcodeError" 27 "MgRecBarcode" 26 "RAuthFailMax" 25 "MgMercAuthFailMax" 24 "RAuthFail" 23 "MgMercAuthFail" 22 "R_6ft" 21 "MgRec_6ft" 20 "RAuthSucc" 19 "MgRecAuthSucc" 18 "MgMercAuthSucc" 17 "RMaxTime" 16 "MgRecMaxTime" 15 "MgMercMaxTime" 14 "RExtendTimeUnloading" 13 "RExtendTimeLoading" 12 "MgReciExtendTime" 11 "MgMercExtendTime" 10 "RTimeOutLoading" 9 "RTimeOutUnloading" 8 "MgMercTimeOut" 7 "MgRecTimeOut" 6 "RBttnPressKeypad" 5 "MgRecBttnPressKeypad" 4 "MgMercBttnPressKeypad" 3 "MgMercBttnPressOrder" 2 "RNudge" 1 "MgMercNudge" 0 "NoSound" ;
VAL_ 1112 BattTracIsoDis_B_Stat 1 "Yes" 0 "No" ;
VAL_ 1112 BattTrac2_E_Max 4095 "Faulty" 4094 "NoDataExists" ;
VAL_ 1112 BattTracHeat_D_Rq 3 "Faulty" 2 "NotUsed" 1 "On" 0 "Off" ;
VAL_ 1112 BattTracDcFstSustn_B_Rq 1 "Active" 0 "Inactive" ;
VAL_ 1112 BattDcCnnct_D_Cmd 7 "NotUsed_3" 6 "NotUsed_2" 5 "NotUsed_1" 4 "WeldCheck" 3 "OkToDischarge" 2 "Closed" 1 "Precharge" 0 "Open" ;
VAL_ 1112 BattTrac2_E_Avail 4095 "Faulty" 4094 "NoDataExists" ;
VAL_ 1112 BattTracCnnct_D_Cmd 7 "NotUsed_3" 6 "NotUsed_2" 5 "NotUsed_1" 4 "WeldCheck" 3 "OkToDischarge" 2 "Closed" 1 "Precharge" 0 "Open" ;
VAL_ 1112 BattTracHvilOpen_B_Stat 1 "Open" 0 "Closed" ;
VAL_ 1112 BattTracCoolLvl_D_Rq 7 "Faulty" 6 "NotUsed" 5 "ChillerCoolingBattFirst" 4 "ChillerCoolingCabinFirst" 3 "ForcedCoolingRadiator" 2 "OpportunisticCoolingRad" 1 "CoolantFlowBypassLine" 0 "Off" ;
VAL_ 1112 BattTracTeSustn_B_Rq 1 "Active" 0 "Inactive" ;
VAL_ 1112 BattTracTeEvnt_B_Stat 1 "Active" 0 "Inactive" ;
VAL_ 1112 BattTracDcdcDis_B_Rq 1 "Yes" 0 "No" ;
VAL_ 1112 BattChrgTrgtEvnt_B_Stat 1 "Active" 0 "Inactive" ;
VAL_ 1112 BattTracDiagClr_B_Rq 1 "On" 0 "Off" ;
VAL_ 1112 BattTracChrgSustn_B_Rq 1 "Active" 0 "Inactive" ;
VAL_ 1112 HtrnClntPump_D_Stat 3 "Faulty" 2 "No_Data_Exists" 1 "On" 0 "Off" ;
VAL_ 1112 BattTracDelta_Te_Actl 255 "Faulty" 254 "NoDataExists" ;
VAL_ 1112 BattTracClntPmp_D_Stat 3 "Faulty" 2 "No_Data_Exists" 1 "On" 0 "Off" ;
VAL_ 1112 BattTracHazrd_D_Stat 3 "Disabled" 2 "HazardConfirmed" 1 "ExternalMonitoringRequired" 0 "NoHazardDetected" ;
VAL_ 977 CnvtTopTrgt_D_Rq 7 "NotUsed4" 6 "NotUsed3" 5 "NotUsed2" 4 "NotUsed1" 3 "OpenTarget" 2 "OpenPosition" 1 "ClosePosition" 0 "CloseTarget" ;
VAL_ 977 CnvtTopSleepActv_B_Rq 1 "Active" 0 "Inactive" ;
VAL_ 977 CnvtTopPar_D_Rq 7 "NotUsed" 6 "ForceIncrease3" 5 "ForceIncrease2" 4 "ForceIncrease1" 3 "NoAdapt" 2 "Teach" 1 "NoPwmNoAp" 0 "Normal" ;
VAL_ 977 CnvtTopBrkActv_B_Rq 1 "Active" 0 "Inactive" ;
VAL_ 977 CnvtTop_D_Rq 7 "NotUsed" 6 "ResetErrorFlags" 5 "DiscardNormalization" 4 "SetNormalization" 3 "DirectDriveClose" 2 "DirectDriveOpen" 1 "DirectPosition" 0 "Stop" ;
VAL_ 977 CnvtTopPos_Up_Stat 1 "Up" 0 "Not_Up" ;
VAL_ 977 CnvtTopMsgTxt_D_Rq 3 "NotSecure" 2 "NotAvailable" 1 "RemoveCaps" 0 "NoWarning" ;
VAL_ 977 WndwCnvtTopDrop_B_Cmd 1 "Yes" 0 "No" ;
VAL_ 977 CnvtTopPos_Dn_Stat 1 "Down" 0 "Not_Down" ;
VAL_ 969 WndwQtrRrDown_B_Stat 1 "Yes" 0 "No" ;
VAL_ 969 WndwQtrRlDown_B_Stat 1 "Yes" 0 "No" ;
VAL_ 969 Dimming_Level_Stat 3 "Low" 2 "Not_Used" 1 "High" 0 "Null" ;
VAL_ 969 Current_Color_Stat 15 "NotUsed7" 14 "NotUsed6" 13 "NotUsed5" 12 "NotUsed4" 11 "NotUsed3" 10 "NotUsed2" 9 "NotUsed1" 8 "Null" 7 "Color7" 6 "Color6" 5 "Color5" 4 "Color4" 3 "Color3" 2 "Color2" 1 "Color1" 0 "Off" ;
VAL_ 969 BlendedColorRed_Stat 15 "NotUsed10" 14 "NotUsed9" 13 "NotUsed8" 12 "NotUsed7" 11 "NotUsed6" 10 "NotUsed5" 9 "NotUsed4" 8 "NotUsed3" 7 "NotUsed2" 6 "NotUsed1" 5 "_5" 4 "_4" 3 "_3" 2 "_2" 1 "_1" 0 "Null" ;
VAL_ 969 BlendedColorGreen_Stat 15 "NotUsed10" 14 "NotUsed9" 13 "NotUsed8" 12 "NotUsed7" 11 "NotUsed6" 10 "NotUsed5" 9 "NotUsed4" 8 "NotUsed3" 7 "NotUsed2" 6 "NotUsed1" 5 "_5" 4 "_4" 3 "_3" 2 "_2" 1 "_1" 0 "Null" ;
VAL_ 969 BlendedColorBlue_Stat 15 "NotUsed10" 14 "NotUsed9" 13 "NotUsed8" 12 "NotUsed7" 11 "NotUsed6" 10 "NotUsed5" 9 "NotUsed4" 8 "NotUsed3" 7 "NotUsed2" 6 "NotUsed1" 5 "_5" 4 "_4" 3 "_3" 2 "_2" 1 "_1" 0 "Null" ;
VAL_ 969 BlendedColor_Stat 3 "NotUsed" 2 "Null" 1 "On" 0 "Off" ;
VAL_ 969 TurnLampRrOut_B_Stat 1 "Out" 0 "Null" ;
VAL_ 969 TurnLampRlOut_B_Stat 1 "Out" 0 "Null" ;
VAL_ 530 StationTypeSel_D_Rq 0 "Inactive" 1 "PI_Code" 2 "SCIDI_SID_ECC" 3 "NotUsed_1" ;
VAL_ 746 Con_BTAud_Shuffle_St 3 "OnTheFolderSelGroup" 2 "OnTheDevice" 1 "Off" 0 "Invalid" ;
VAL_ 746 Con_BTAud_Repeat_St 7 "Reserved3" 6 "Reserved2" 5 "Reserved1" 4 "RepeatOnDevice" 3 "RepeatOnFolder" 2 "RepeatOnTrack" 1 "Off" 0 "Invalid" ;
VAL_ 746 Con_BTAud_IntroScan_St 3 "OnTheFolderSelGroup" 2 "OnTheDevice" 1 "Off" 0 "Invalid" ;
VAL_ 746 Con_BTAud_Error_St 8 "NoDataInFolder" 7 "NoRespFromDevice" 6 "UnableToRead" 5 "NoDataOnDevice" 4 "FileSysNotSupported" 3 "DeviceNotSupported" 2 "InvalidFile" 1 "NoError" 0 "Invalid" ;
VAL_ 746 Con_BTAud_FunctStats_St 7 "Reserved2" 6 "Reserved1" 5 "Reserved" 4 "Reading" 3 "Ready" 2 "Initilization" 1 "Free" 0 "Invalid" ;
VAL_ 746 Con_BTAud_OpMode_St 7 "FastRewind20" 6 "FastRewind10" 5 "FastForward20" 4 "FastForward10" 3 "Pause" 2 "Play" 1 "Stop" 0 "Invalid" ;
VAL_ 479 DISP_SetVol_Source_Rq 5 "SetAudioVolume" 4 "SetVRvolume" 3 "SetPhoneVolume" 2 "SetPromptVolume" 1 "SetTAVolume" 0 "Inactive" ;
VAL_ 479 DISP_Setshaker_Rq 2 "On" 1 "Off" 0 "Inactive" ;
VAL_ 474 Nav_SetCurrStatMCCh_Rq 7 "MCChannel7" 6 "MCChannel6" 5 "MCChannel5" 4 "MCChannel4" 3 "MCChannel3" 2 "MCChannel2" 1 "MCChannel1" 0 "Inactive" ;
VAL_ 474 NAV_SetNEWSMode_Rq 0 "Inactive" 1 "NewsOn" 2 "NewsOff" ;
VAL_ 474 NAV_SetDSP_Rq 9 "Convertible" 8 "RearSeats" 7 "FrontSeats" 6 "Reserved3" 5 "Reserved2" 4 "Reserved1" 15 "Reserved" 0 "Inactive" 1 "All" 2 "Driver" 3 "Passenger" ;
VAL_ 474 NAV_SetCurrentStatOp_Rq 0 "Inactive" 1 "SetCurrentFrequency" 2 "SetCurrentPiCode" 3 "SetCurrentStation" ;
VAL_ 474 NAV_ARReqstrSystem_Rq 0 "FrontRequester" 1 "RearRequester" ;
VAL_ 474 NAV_ARReqstrPriority_Rq 0 "EmergencyServ" 1 "TelService" 2 "AutoAnswer" 3 "Ta" 4 "PttMutevoice" 5 "NavUserVoiceCmd" 6 "NavSysVoiceCmd" 7 "Radio" 8 "Disc" 9 "Alarm" 10 "Ptynews" 11 "Aux_ExtSource" 12 "BT_BTNavAndTelMute" 13 "ManualAudioMute" 14 "NotReq" ;
VAL_ 474 NAV_AROperationType_Rq 0 "Inactive" 1 "Requestaudioresource" 2 "Releaseaudioresource" 3 "Releaseallaudioresouces" 4 "Getresourceupdate" 5 "Getallresourceupdates" ;
VAL_ 474 NAV_ARAudioSource_Rq 15 "iPod" 14 "USB" 13 "BTAudio" 0 "AmfmRadio" 1 "FrontDisc" 2 "SDARS_DAB" 3 "InDashCdChanger" 4 "VoiceRecogniser" 5 "TelematicUnit" 6 "BluetoothPhone" 7 "RearDisc" 8 "APIM" 9 "FrontAuxInput" 10 "Navigation" 11 "RearAux" 12 "NotReq" ;
VAL_ 477 NAV_LoadEjectMode_Rq 0 "Inactive" 1 "Load" 2 "Eject" 3 "EndloadMode" ;
VAL_ 477 NAV_LoadEjectDisc_Rq 0 "Inactive" 1 "Disc1" 2 "Disc2" 3 "Disc3" 4 "Disc4" 5 "Disc5" 6 "Disc6" 7 "All" ;
VAL_ 260 MFD_SDARS_SetOpMode_Rq 7 "FastRewindSpeed2" 6 "FastRewindSpeed1" 5 "FastForwardSpeed2" 4 "FastForwardSpeed1" 3 "Pause" 2 "Play" 1 "Stop" 0 "Invalid" ;
VAL_ 260 SDARS_GetESN_Rq 1 "RequestESN" 0 "Invalid" ;
VAL_ 260 SDARS_SRReplay_Rq 2 "Disable" 1 "Enable" 0 "Inactive" ;
VAL_ 260 SDARS_FactoryReset_Rq 1 "ResetFactoryDefaults" 0 "Invalid" ;
VAL_ 476 Nav_SetAudioMixRatio_Rq 31 "Inactive" ;
VAL_ 476 NAV_SkipCatalouge_Rq 0 "Inactive" 1 "NextCatalouge" 2 "PerviousCatalouge" ;
VAL_ 476 NAV_SetOperationMode_Rq 7 "FastRewind20" 6 "FastRewind10" 5 "FastForward20" 4 "FastForward10" 3 "Pause" 2 "Play" 1 "Stop" 0 "Inactive" ;
VAL_ 476 NAV_SetDSPProgram_Rq 7 "Reserved2" 6 "Reserved1" 5 "Voice" 4 "Rock" 0 "Inactive" 1 "Normal" 2 "Pop" 3 "Classical" ;
VAL_ 490 HMI_SetCompression_Rq 0 "Inactive" 1 "Off" 2 "On" 3 "NotUsed" ;
VAL_ 490 HMI_SkipTrack_Rq 3 "NotUsed" 2 "Decrement" 1 "Increment" 0 "Inactive" ;
VAL_ 896 BptDly_T_Actl 63 "Faulty" 62 "NoDataExists" ;
VAL_ 896 VehElAvgTrip1_Eff_Dsply 127 "Faulty" 126 "NoDataExists" ;
VAL_ 896 Trip1SumDrvE_Pc_Dsply 1023 "Faulty" 1022 "NoDataExists" ;
VAL_ 896 Trip1ExtFctrE_Pc_Dsply 1023 "Faulty" 1022 "NoDataExists" ;
VAL_ 896 Trip1ClimE_Pc_Dsply 1023 "Faulty" 1022 "NoDataExists" ;
VAL_ 896 Trip1BattULoE_Pc_Dsply 1023 "Faulty" 1022 "NoDataExists" ;
VAL_ 897 VehElAvgTrip2_Eff_Dsply 127 "Faulty" 126 "NoDataExists" ;
VAL_ 897 Trip2SumDrvE_Pc_Dsply 1023 "Faulty" 1022 "NoDataExists" ;
VAL_ 897 Trip2ExtFctrE_Pc_Dsply 1023 "Faulty" 1022 "NoDataExists" ;
VAL_ 897 Trip2ClimE_Pc_Dsply 1023 "Faulty" 1022 "NoDataExists" ;
VAL_ 897 Trip2BattULoE_Pc_Dsply 1023 "Faulty" 1022 "NoDataExists" ;
VAL_ 502 Dsp_FolderContent_Rq 2 "Inactive" 1 "RequestContentFromParentF" 0 "RequestContentFromParamet" ;
VAL_ 502 Dsp_CutItem2_Rq 3 "Inactive" 2 "ThreeQuarterFromTheBeginn" 1 "End" 0 "Beginning" ;
VAL_ 502 Dsp_AudioSourceSel2_Rq 4 "Reserved" 3 "USB" 2 "BTAudio" 1 "CD" 0 "Inactive" ;
VAL_ 955 Tire_Temp_RF_Data 255 "NotSupported" 254 "Invalid" ;
VAL_ 955 Tire_Temp_ORR_Data 255 "NotSupported" 254 "Invalid" ;
VAL_ 955 Tire_Temp_OLR_Data 255 "NotSupported" 254 "Invalid" ;
VAL_ 955 Tire_Temp_LF_Data 255 "NotSupported" 254 "Invalid" ;
VAL_ 955 Tire_Temp_IRR_Data 255 "NotSupported" 254 "Invalid" ;
VAL_ 955 Tire_Temp_ILR_Data 255 "NotSupported" 254 "Invalid" ;
VAL_ 1116 TrlrAidSetup_D2_Rq 15 "NotUsed_9" 14 "NotUsed_8" 13 "NotUsed_7" 12 "NotUsed_6" 11 "NotUsed_5" 10 "NotUsed_4" 9 "NotUsed_3" 8 "NotUsed_2" 7 "NotUsed_1" 6 "CompleteSetup" 5 "ReturnToSetup" 4 "StickerNotCircled" 3 "ConfirmSetup" 2 "EndSetup" 1 "BeginSetup" 0 "Inactive" ;
VAL_ 1116 TrlrAidEnbl_D2_Rq 7 "NotUsed_4" 6 "NotUsed_3" 5 "NotUsed_2" 4 "NotUsed_1" 3 "Deactivate" 2 "ActivateTrg" 1 "ActivateTba" 0 "Inactive" ;
VAL_ 1116 TlightTest_D_Mnu 3 "TestEndAcknowledge" 2 "StartTest" 1 "StopTest" 0 "Null" ;
VAL_ 1116 TrlrRvrseCancl_B_Rq 1 "Cancel" 0 "Null" ;
VAL_ 1116 TrlrIdType_D_Stat 3 "Gooseneck" 2 "FifthWheel" 1 "Conventional" 0 "Null" ;
VAL_ 1116 TrlrAnOffstDir_D_Mem 3 "NotUSed" 2 "Right" 1 "Left_or_Center" 0 "Null" ;
VAL_ 608 EvseDcChrgIso_D_Stat 7 "Faulty" 6 "NoDataExists" 5 "NotUsed_3" 4 "NotUsed_2" 3 "NotUsed_1" 2 "Valid" 1 "Warning" 0 "Invalid" ;
VAL_ 608 DcChrgSrvcRqd_B_Rq 1 "On" 0 "Off" ;
VAL_ 608 DcChrgWarnLamp_B_Rq 1 "On" 0 "Off" ;
VAL_ 608 EvseChrgIso_D_Stat 3 "Faulty" 2 "Warning" 1 "Valid" 0 "Invalid" ;
VAL_ 608 DgtlCommGtwy_D_Falt 127 "NotUsed_63" 65 "NotUsed_1" 64 "EvseGbtCommTimeout" 63 "EvseGbtCrgVoltMismatch" 62 "EvseGbtChrgCurrntMismatch" 61 "EvseGbtOtherFalt" 60 "EvseGbtEmergShutdown" 59 "EvseGbtEnergyTransFalt" 58 "EvseGbtIntOverTemp" 57 "EvseGbtConnectorFalt" 56 "EvseGbtOverTemp" 55 "EvseResCpsRootCaCertRev" 54 "EvseResSubCA2CertRev" 53 "EvseResSubCA1CertRev" 52 "EvseResCpsProvCertRev" 51 "EvseResRootCaCertRev" 50 "EvseResMoSubCa2CertRev" 49 "EvseResMoSubCa1CertRev" 48 "EvseResMoProvCertRev" 47 "EvseResOemSubCa2CertRev" 46 "EvseResOemSubCa1CertRev" 45 "EvseResOemProvCertRev" 44 "EvseResMoUnknown" 43 "EvseResContractNotAccept" 42 "EvseResNoSuppAppProt" 41 "EvseResCertNotAllowed" 40 "EvseResContractErr" 39 "EvseResNoChrgSvcSelect" 38 "EvseResMeterSignNotVld" 37 "EvseResPwrDelNotApplied" 36 "EvseResTrfSelectInvld" 35 "EvseResChrgProfileInvld" 34 "EvseResWrongChrgParam" 33 "EvseResWrongEnrgyTransMde" 32 "EvseResChlgInvld" 31 "EvseResContractCancel" 30 "EvseResCertChainErr" 29 "EvseResNoCertAvail" 28 "EvseResCertRvk" 27 "EvseResCertExp" 26 "EvseResPymtSelectInvld" 25 "EvseResSvcldInvld" 24 "EvseResUnknownSession" 23 "EvseResSignErr" 22 "EvseResSeqErr" 21 "EvseResFailed" 20 "EvsePreChrgTimeout" 19 "EvseCableCheckTimeout" 18 "EvseCommSetupTimeout" 17 "EvseMsgTimeout" 16 "EvseTlsUnknownCA" 15 "EvseTlsCertExpired" 14 "EvseTlsBadCert" 13 "EvseTlsHandshakeFail" 12 "EvseTlsDecryptFail" 11 "EvseTlsBadRecordMac" 10 "EvseTlsUnexpectedMsg" 9 "EvseTlsFail" 8 "EvseTcpCnnctFail" 7 "EvseUpdErr" 6 "EvseSlaacErr" 5 "EvseStopNotification" 4 "EvseMalfunction" 3 "EvseEmergShutdown" 2 "EvseStatUtilityIntrpt" 1 "EvseStatShutdown" 0 "NoFault" ;
VAL_ 608 EvseChrg2_Pw_Mx 32767 "Faulty" 32766 "NoDataExists" ;
VAL_ 608 DcChrgRdy_D_Stat 15 "Faulty" 14 "NotUsed_4" 13 "NotUsed_3" 12 "NotUsed_2" 11 "CableCheck" 10 "EvseFault" 9 "EvseNotCompatible" 8 "EvsePaused" 7 "GbtPrecharge" 6 "ChargeComplete" 5 "Charging" 4 "Precharge" 3 "WeldCheck" 2 "ChargeReady" 1 "Initialization" 0 "NotReady" ;
VAL_ 608 DgtlCommGtwyMde_D_Stat 11 "NotUsed_3" 10 "DgtlCommFailed" 9 "DgtlCommEstablished" 8 "Inactive" 7 "RestartRequest" 6 "AcPnc_Eim" 5 "AcPnc" 4 "AcEim" 3 "DcPnc_Eim" 2 "DcPnc" 1 "DcEim" 0 "NotDetected" 15 "NotUsed_7" 14 "NotUsed_6" 13 "NotUsed_5" 12 "NotUsed_4" ;
VAL_ 608 DgtlCommPnc_D_Stat 7 "Faulty" 6 "NotUsed_3" 5 "NotUsed_2" 4 "NotUsed_1" 3 "Enable" 2 "Disable" 1 "NoContractsInstalled" 0 "Null" ;
VAL_ 608 BattTracIsoDis_B_Rq 1 "Yes" 0 "No" ;
VAL_ 838 FohStrtDay_T_Rq 7 "Sunday" 6 "Saturday" 5 "Friday" 4 "Thursday" 3 "Wednesday" 2 "Tuesday" 1 "Monday" 0 "NotUsed" ;
VAL_ 838 FohStop_B_Rq 3 "Unknown" 2 "NotUsed" 1 "Enable" 0 "Disable" ;
VAL_ 838 FohTAllEnable_B_Rq 3 "Unknown" 2 "NotUsed" 1 "Enable" 0 "Disable" ;
VAL_ 838 FohT2Enable_B_Rq 1 "Enable" 0 "Disable" ;
VAL_ 838 FohT1Enable_B_Rq 1 "Enable" 0 "Disable" ;
VAL_ 838 FohStrtEnable_B_Rq 1 "Enable" 0 "Disable" ;
VAL_ 838 FohContOn_B_Rq 3 "Unknown" 2 "NotUsed" 1 "Enable" 0 "Disable" ;
VAL_ 1255 BalrRight4Threat_D_Stat 1 "Yes" 0 "No" ;
VAL_ 1255 BalrRight4Fast_B_Stat 1 "Yes" 0 "No" ;
VAL_ 1255 BalrRight4Dsply_B_Stat 1 "Yes" 0 "No" ;
VAL_ 1254 BalrRight3Threat_D_Stat 1 "Yes" 0 "No" ;
VAL_ 1254 BalrRight3Fast_B_Stat 1 "Yes" 0 "No" ;
VAL_ 1254 BalrRight3Dsply_B_Stat 1 "Yes" 0 "No" ;
VAL_ 1253 BalrRight2Threat_D_Stat 1 "Yes" 0 "No" ;
VAL_ 1253 BalrRight2Fast_B_Stat 1 "Yes" 0 "No" ;
VAL_ 1253 BalrRight2Dsply_B_Stat 1 "Yes" 0 "No" ;
VAL_ 1252 BalrRight1Threat_D_Stat 1 "Yes" 0 "No" ;
VAL_ 1252 BalrRight1Fast_B_Stat 1 "Yes" 0 "No" ;
VAL_ 1252 BalrRight1Dsply_B_Stat 1 "Yes" 0 "No" ;
VAL_ 1251 BalrLeft4Threat_D_Stat 1 "Yes" 0 "No" ;
VAL_ 1251 BalrLeft4Fast_B_Stat 1 "Yes" 0 "No" ;
VAL_ 1251 BalrLeft4Dsply_B_Stat 1 "Yes" 0 "No" ;
VAL_ 1250 BalrLeft3Threat_D_Stat 1 "Yes" 0 "No" ;
VAL_ 1250 BalrLeft3Fast_B_Stat 1 "Yes" 0 "No" ;
VAL_ 1250 BalrLeft3Dsply_B_Stat 1 "Yes" 0 "No" ;
VAL_ 1249 BalrLeft2Threat_D_Stat 1 "Yes" 0 "No" ;
VAL_ 1249 BalrLeft2Fast_B_Stat 1 "Yes" 0 "No" ;
VAL_ 1249 BalrLeft2Dsply_B_Stat 1 "Yes" 0 "No" ;
VAL_ 1248 BalrLeft1Threat_D_Stat 1 "Yes" 0 "No" ;
VAL_ 1248 BalrLeft1Fast_B_Stat 1 "Yes" 0 "No" ;
VAL_ 1248 BalrLeft1Dsply_B_Stat 1 "Yes" 0 "No" ;
VAL_ 529 OnbChrgToPcWknd_D_Actl 7 "Percent_50" 6 "Percent_60" 5 "Percent_70" 4 "Percent_80" 3 "Percent_85" 2 "Percent_90" 1 "Percent_95" 0 "Percent_100" ;
VAL_ 529 OnbChrgToPcWkdy_D_Actl 7 "Percent_50" 6 "Percent_60" 5 "Percent_70" 4 "Percent_80" 3 "Percent_85" 2 "Percent_90" 1 "Percent_95" 0 "Percent_100" ;
VAL_ 529 OnbChrgSetNow_D_Rq 3 "NotUsed" 2 "On" 1 "Off" 0 "Null" ;
VAL_ 529 OnbChrgSetDelete_B_Rq 1 "Request" 0 "NoRequest" ;
VAL_ 529 OnbChrgPrflUpdate_B_Rq 1 "Request" 0 "NoRequest" ;
VAL_ 529 OnbChrgLocIdUns_B_Rq 1 "Request" 0 "NoRequest" ;
VAL_ 374 GearEngag_D_Actl 7 "Undefined" 6 "Fwd_Clutch_Fully_Engaged" 5 "Neutral_Idle" 4 "Disengaged_to_Neutral_Idle" 3 "Disengaged_to_Neutral_Park" 2 "Engagement_in_Progress" 1 "InitializeFwdClutchEngagmt" 0 "Park_Neutral" ;
VAL_ 374 TrnRng_D_Rq 15 "Fault" 14 "Unknown_Position" 13 "NotUsed_2" 12 "NotUsed_1" 11 "Range6" 10 "Range5" 9 "Range4" 8 "Range3_M3_L3" 7 "Range2_M2_L2" 6 "Range1_M1_L1" 5 "Low" 4 "Sport_DriveSport_Mposition" 3 "Drive" 2 "Neutral" 1 "Reverse" 0 "Park" ;
VAL_ 374 TrnPrkSys_D_Actl 15 "Faulty" 14 "NotUsed_5" 13 "NotUsed_4" 12 "NotUsed_3" 11 "NotUsed_2" 10 "NotUsed_1" 9 "FrequencyError" 8 "OutOfRangeHigh" 7 "OutOfRangeLow" 6 "Override" 5 "OutOfPark" 4 "TransitionCloseToOutOfPark" 3 "AtNoSpring" 2 "TransitionCloseToPark" 1 "Park" 0 "NotKnown" ;
VAL_ 374 GearPos_D_Actl 15 "Unknown" 14 "Reverse" 13 "Undefined_5" 12 "Undefined_4" 11 "Undefined_3" 10 "Tenth" 9 "Ninth" 8 "Eighth" 7 "Seventh" 6 "Sixth" 5 "Fifth" 4 "Fourth" 3 "Third" 2 "Second" 1 "First" 0 "Neutral" ;
VAL_ 374 GearPos_D_Trg 15 "Unknown" 14 "Reverse" 13 "Undefined_5" 12 "Undefined_4" 11 "Undefined_3" 10 "Tenth" 9 "Ninth" 8 "Eighth" 7 "Seventh" 6 "Sixth" 5 "Fifth" 4 "Fourth" 3 "Third" 2 "Second" 1 "First" 0 "Neutral" ;
VAL_ 374 GearLvr_D_ActlDrv 15 "Fault" 14 "Unknown_Position" 13 "NotUsed_2" 12 "NotUsed_1" 11 "Range6" 10 "Range5" 9 "Range4" 8 "Range3_M3_L3" 7 "Range2_M2_L2" 6 "Range1_M1_L1" 5 "Low" 4 "Sport_DriveSport_Mposition" 3 "Drive" 2 "Neutral" 1 "Reverse" 0 "Park" ;
VAL_ 500 Dsp_GetCDTOCDData_Rq 0 "Inactive" 2 "Off" 1 "TOC" ;
VAL_ 500 Dsp_CutItem_Rq 3 "Inactive" 2 "ThreeQuarterFromTheBeginn" 1 "End" 0 "Beginning" ;
VAL_ 500 Dsp_AudioSourceSel_Rq 5 "SDCard" 4 "Reserved" 3 "USB" 2 "BTAudio" 1 "CD" 0 "Inactive" ;
VAL_ 503 Dsp_AudioSourceSel3_Rq 3 "USB" 2 "BTAudio" 1 "CD" 0 "Inactive" ;
VAL_ 493 Dsp_StatLiScanCancel_Rq 1 "Cancel" 0 "Inactive" ;
VAL_ 493 Dsp_StationList_Rq 15 "reserved_last" 8 "reserved" 7 "DAB_Service_List" 6 "DAB_Ensemble_Service_List" 5 "Analog_FM_PTY_List" 4 "Analog_and_HD_FM_List" 3 "HD_FM_List" 2 "Analog_FM_List" 1 "Analog_AM_List" 0 "Inactive" ;
VAL_ 493 Dsp_RefreshFlag 1 "True" 0 "False" ;
VAL_ 493 Dsp_AFJump_Rq 2 "Enable" 1 "Inhibit" 0 "Inactive" ;
VAL_ 511 Dsp_TUPresetArea_Rq 13 "reserved" 12 "GetSAT3PresetData" 11 "GetSAT2PresetData" 15 "reserved_last" 10 "GetSAT1PresetData" 9 "GetDAB2PresetData" 8 "GetDAB1PresetData" 7 "GetDAB3PresetData" 6 "GetAmPresetData" 5 "GetAmAstPresetData" 4 "GetFmAstPresetData" 3 "GetFm3PresetData" 2 "GetFm2PresetData" 1 "GetFm1PresetData" 0 "Inactive" ;
VAL_ 511 Dsp_SetCurrTUBand_Rq 13 "reserved1" 12 "DAB3" 11 "SAT3" 10 "SAT2" 15 "reserved_last" 9 "SAT1" 8 "DAB2" 7 "DAB1" 6 "AmAst" 5 "Am" 4 "FmAst" 3 "Fm3" 2 "Fm2" 1 "Fm1" 0 "Inactive" ;
VAL_ 511 SdarsAudioRtng_D_Rq 3 "NotUsed" 2 "APIMStereoOut" 1 "X40l2SStereoOut" 0 "Null" ;
VAL_ 257 MFD_SetTagMode 2 "On" 1 "Off" 0 "Inactive" ;
VAL_ 257 MFD_SetRBDSMode 2 "On" 1 "Off" 0 "Inactive" ;
VAL_ 257 MFD_SetHDModeRq 2 "On" 1 "Off" 0 "Inactive" ;
VAL_ 257 MFD_GetTagInfo 1 "TagInformation" 0 "Inactive" ;
VAL_ 972 LatCtlSte_D_Stat 7 "NotUsed3" 6 "NotUsed2" 5 "NotUsed1" 4 "Denied" 3 "RampOut" 2 "ContLatControlInProgress" 1 "Available" 0 "Unavailable" ;
VAL_ 972 LatCtlLim_D_Stat 3 "LimitWithDriverActive" 2 "LimitReached" 1 "LimitClose" 0 "LimitNotReached" ;
VAL_ 972 LatCtlCpblty_D_Stat 3 "Faulty" 2 "ExtendedModeAvailable" 1 "LimitedModeAvailable" 0 "NoModeAvailable" ;
VAL_ 972 LsmcBrkDecelEnbl_D_Rq 3 "NotUsed2" 2 "NotUsed1" 1 "On" 0 "Off" ;
VAL_ 972 TjaHandsOnCnfdnc_B_Est 1 "High_Confidence" 0 "Low_Confidence" ;
VAL_ 972 LaHandsOff_B_Actl 1 "Hands_Off" 0 "Hands_On" ;
VAL_ 972 LaActDeny_B_Actl 1 "LA_Denied" 0 "LA_Not_Denied" ;
VAL_ 972 LaActAvail_D2_Actl 3 "Intervention_Available" 2 "NoIntervention_Available" 1 "Intervention_NotAvailable" 0 "NoIntervention_NotAvailabl" ;
VAL_ 1120 StabBarCnncButtn_D_Stat 3 "Faulty" 2 "NotUsed" 1 "Pressed" 0 "Not_Pressed" ;
VAL_ 1120 DrvSlipCtlMde_B_Rq3 1 "Pressed" 0 "Not_Pressed" ;
VAL_ 1120 HybMdeSwtch_B_Rq 1 "Pressed" 0 "Not_Pressed" ;
VAL_ 1120 FrontDiffLck_D_RqDrv 3 "Faulty" 2 "NoRequest" 1 "On" 0 "Off" ;
VAL_ 1120 AwdLck_D_RqDrv 3 "Faulty" 2 "NoRequest" 1 "On" 0 "Off" ;
VAL_ 1120 TrailCtlSwtch_B_Stat3 1 "Pressed" 0 "Not_Pressed" ;
VAL_ 1120 RearDiffLck_D_RqDrv 3 "Faulty" 2 "NoRequest" 1 "On" 0 "Off" ;
VAL_ 1120 AwdMde_D_RqDrv 7 "Faulty" 6 "NotUsed2" 5 "NoRequest" 4 "Neutral" 3 "FourByFourLow" 2 "FourByFourHigh" 1 "FourByFourAuto" 0 "FourByTwo" ;
VAL_ 1120 HdcSwtchPos_B_Actl 1 "Pressed" 0 "Not_Pressed" ;
VAL_ 1087 TrlrRngeDsply_B_Stat 1 "On" 0 "Off" ;
VAL_ 1087 StopStrtImccTxt_D_Dspl 15 "Message15" 14 "Message14" 13 "Message13" 12 "Message12" 11 "Message11" 10 "Message10" 9 "Message9" 8 "Message8" 7 "Message7" 6 "Message6" 5 "Message5" 4 "Message4" 3 "Message3" 2 "Message2" 1 "Message1" 0 "NoMessage" ;
VAL_ 1087 StopStrtImccActv_D_St 7 "NotUsed_3" 6 "NotUsed_2" 5 "NotUsed_1" 4 "Deactivated" 3 "OnSuspended" 2 "OnActive" 1 "OnNotActive" 0 "Off" ;
VAL_ 1087 StopStrtImccTxt_D_Rq 7 "Message7" 6 "Message6" 5 "Message5" 4 "Message4" 3 "Message3" 2 "Message2" 1 "Message1" 0 "NoMessage" ;
VAL_ 1087 EngIdlShutDownT_D_Stat 255 "NotUsed_13" 254 "NotUsed_12" 253 "NotUsed_11" 252 "NotUsed_10" 251 "NotUsed_9" 250 "NotUsed_8" 249 "NotUsed_7" 248 "NotUsed_6" 247 "NotUsed_5" 246 "NotUsed_4" 245 "NotUsed_3" 244 "NotUsed_2" 243 "NotUsed_1" 242 "Indefinite_Idle" 241 "Selectable_Idle_Not_Active" 240 "IdleMinutes_240" 239 "IdleMinutes_239" 238 "IdleMinutes_238" 237 "IdleMinutes_237" 236 "IdleMinutes_236" 235 "IdleMinutes_235" 234 "IdleMinutes_234" 233 "IdleMinutes_233" 232 "IdleMinutes_232" 231 "IdleMinutes_231" 230 "IdleMinutes_230" 229 "IdleMinutes_229" 228 "IdleMinutes_228" 227 "IdleMinutes_227" 226 "IdleMinutes_226" 225 "IdleMinutes_225" 224 "IdleMinutes_224" 223 "IdleMinutes_223" 222 "IdleMinutes_222" 221 "IdleMinutes_221" 220 "IdleMinutes_220" 219 "IdleMinutes_219" 218 "IdleMinutes_218" 217 "IdleMinutes_217" 216 "IdleMinutes_216" 215 "IdleMinutes_215" 214 "IdleMinutes_214" 213 "IdleMinutes_213" 212 "IdleMinutes_212" 211 "IdleMinutes_211" 210 "IdleMinutes_210" 209 "IdleMinutes_209" 208 "IdleMinutes_208" 207 "IdleMinutes_207" 206 "IdleMinutes_206" 205 "IdleMinutes_205" 204 "IdleMinutes_204" 203 "IdleMinutes_203" 202 "IdleMinutes_202" 201 "IdleMinutes_201" 200 "IdleMinutes_200" 199 "IdleMinutes_199" 198 "IdleMinutes_198" 197 "IdleMinutes_197" 196 "IdleMinutes_196" 195 "IdleMinutes_195" 194 "IdleMinutes_194" 193 "IdleMinutes_193" 192 "IdleMinutes_192" 191 "IdleMinutes_191" 190 "IdleMinutes_190" 189 "IdleMinutes_189" 188 "IdleMinutes_188" 187 "IdleMinutes_187" 186 "IdleMinutes_186" 185 "IdleMinutes_185" 184 "IdleMinutes_184" 183 "IdleMinutes_183" 182 "IdleMinutes_182" 181 "IdleMinutes_181" 180 "IdleMinutes_180" 179 "IdleMinutes_179" 178 "IdleMinutes_178" 177 "IdleMinutes_177" 176 "IdleMinutes_176" 175 "IdleMinutes_175" 174 "IdleMinutes_174" 173 "IdleMinutes_173" 172 "IdleMinutes_172" 171 "IdleMinutes_171" 170 "IdleMinutes_170" 169 "IdleMinutes_169" 168 "IdleMinutes_168" 167 "IdleMinutes_167" 166 "IdleMinutes_166" 165 "IdleMinutes_165" 164 "IdleMinutes_164" 163 "IdleMinutes_163" 162 "IdleMinutes_162" 161 "IdleMinutes_161" 160 "IdleMinutes_160" 159 "IdleMinutes_159" 158 "IdleMinutes_158" 157 "IdleMinutes_157" 156 "IdleMinutes_156" 155 "IdleMinutes_155" 154 "IdleMinutes_154" 153 "IdleMinutes_153" 152 "IdleMinutes_152" 151 "IdleMinutes_151" 150 "IdleMinutes_150" 149 "IdleMinutes_149" 148 "IdleMinutes_148" 147 "IdleMinutes_147" 146 "IdleMinutes_146" 145 "IdleMinutes_145" 144 "IdleMinutes_144" 143 "IdleMinutes_143" 142 "IdleMinutes_142" 141 "IdleMinutes_141" 140 "IdleMinutes_140" 139 "IdleMinutes_139" 138 "IdleMinutes_138" 137 "IdleMinutes_137" 136 "IdleMinutes_136" 135 "IdleMinutes_135" 134 "IdleMinutes_134" 133 "IdleMinutes_133" 132 "IdleMinutes_132" 131 "IdleMinutes_131" 130 "IdleMinutes_130" 129 "IdleMinutes_129" 128 "IdleMinutes_128" 127 "IdleMinutes_127" 126 "IdleMinutes_126" 125 "IdleMinutes_125" 124 "IdleMinutes_124" 123 "IdleMinutes_123" 122 "IdleMinutes_122" 121 "IdleMinutes_121" 120 "IdleMinutes_120" 119 "IdleMinutes_119" 118 "IdleMinutes_118" 117 "IdleMinutes_117" 116 "IdleMinutes_116" 115 "IdleMinutes_115" 114 "IdleMinutes_114" 113 "IdleMinutes_113" 112 "IdleMinutes_112" 111 "IdleMinutes_111" 110 "IdleMinutes_110" 109 "IdleMinutes_109" 108 "IdleMinutes_108" 107 "IdleMinutes_107" 106 "IdleMinutes_106" 105 "IdleMinutes_105" 104 "IdleMinutes_104" 103 "IdleMinutes_103" 102 "IdleMinutes_102" 101 "IdleMinutes_101" 100 "IdleMinutes_100" 99 "IdleMinutes_99" 98 "IdleMinutes_98" 97 "IdleMinutes_97" 96 "IdleMinutes_96" 95 "IdleMinutes_95" 94 "IdleMinutes_94" 93 "IdleMinutes_93" 92 "IdleMinutes_92" 91 "IdleMinutes_91" 90 "IdleMinutes_90" 89 "IdleMinutes_89" 88 "IdleMinutes_88" 87 "IdleMinutes_87" 86 "IdleMinutes_86" 85 "IdleMinutes_85" 84 "IdleMinutes_84" 83 "IdleMinutes_83" 82 "IdleMinutes_82" 81 "IdleMinutes_81" 80 "IdleMinutes_80" 79 "IdleMinutes_79" 78 "IdleMinutes_78" 77 "IdleMinutes_77" 76 "IdleMinutes_76" 75 "IdleMinutes_75" 74 "IdleMinutes_74" 73 "IdleMinutes_73" 72 "IdleMinutes_72" 71 "IdleMinutes_71" 70 "IdleMinutes_70" 69 "IdleMinutes_69" 68 "IdleMinutes_68" 67 "IdleMinutes_67" 66 "IdleMinutes_66" 65 "IdleMinutes_65" 64 "IdleMinutes_64" 63 "IdleMinutes_63" 62 "IdleMinutes_62" 61 "IdleMinutes_61" 60 "IdleMinutes_60" 59 "IdleMinutes_59" 58 "IdleMinutes_58" 57 "IdleMinutes_57" 56 "IdleMinutes_56" 55 "IdleMinutes_55" 54 "IdleMinutes_54" 53 "IdleMinutes_53" 52 "IdleMinutes_52" 51 "IdleMinutes_51" 50 "IdleMinutes_50" 49 "IdleMinutes_49" 48 "IdleMinutes_48" 47 "IdleMinutes_47" 46 "IdleMinutes_46" 45 "IdleMinutes_45" 44 "IdleMinutes_44" 43 "IdleMinutes_43" 42 "IdleMinutes_42" 41 "IdleMinutes_41" 40 "IdleMinutes_40" 39 "IdleMinutes_39" 38 "IdleMinutes_38" 37 "IdleMinutes_37" 36 "IdleMinutes_36" 35 "IdleMinutes_35" 34 "IdleMinutes_34" 33 "IdleMinutes_33" 32 "IdleMinutes_32" 31 "IdleMinutes_31" 30 "IdleMinutes_30" 29 "IdleMinutes_29" 28 "IdleMinutes_28" 27 "IdleMinutes_27" 26 "IdleMinutes_26" 25 "IdleMinutes_25" 24 "IdleMinutes_24" 23 "IdleMinutes_23" 22 "IdleMinutes_22" 21 "IdleMinutes_21" 20 "IdleMinutes_20" 19 "IdleMinutes_19" 18 "IdleMinutes_18" 17 "IdleMinutes_17" 16 "IdleMinutes_16" 15 "IdleMinutes_15" 14 "IdleMinutes_14" 13 "IdleMinutes_13" 12 "IdleMinutes_12" 11 "IdleMinutes_11" 10 "IdleMinutes_10" 9 "IdleMinutes_9" 8 "IdleMinutes_8" 7 "IdleMinutes_7" 6 "IdleMinutes_6" 5 "IdleMinutes_5" 4 "IdleMinutes_4" 3 "IdleMinutes_3" 2 "IdleMinutes_2" 1 "IdleMinute_1" 0 "Null" ;
VAL_ 1087 DcacFaltMsgTxt_D2_Rq 35 "NotUsed_1" 34 "FrontTrnkPlgWarnDertExceed" 33 "FrontTrnkPlgWarnDerate" 32 "FrontTrnkPlgWarnFullPw" 31 "IpcPlugWarnDrive" 30 "DcacbOvercurrentLp" 29 "DcacbService" 28 "DcacbNotAvailable" 27 "DcacbAcOnOutput" 26 "DcacbTemperature" 25 "DcacbGfci" 24 "DcacbOvercurrent" 23 "PpoUsageWhenVehlsCharging" 22 "RpsNewKeyCycleWarning" 21 "LowSocRpsWarning" 20 "RpsResetWarn_ChngDrvToPark" 19 "RpsResetWarning" 18 "FirstRpsWarning" 63 "NotUsed_29" 17 "PowerTakeoff" 16 "HevDerate" 15 "HvacOn" 14 "OvercurrentLP" 13 "EngineRun" 12 "Service" 11 "NotAvailable" 10 "PlugWarn" 9 "PlugWarnDrive" 8 "BreakerC" 7 "BreakerB" 6 "BreakerA" 5 "FuelLow" 4 "AcOnOutput" 3 "Temperature" 2 "Gfci" 1 "Overcurrent" 0 "Ok" ;
VAL_ 1087 StopStrtCstm_D_Stat 3 "Faulty" 2 "On" 1 "Off" 0 "NotAvailable" ;
VAL_ 1087 SelDrvMdeCstmPt_D_Stat 31 "Faulty" 30 "NotUsed15" 29 "NotUsed14" 28 "NotUsed13" 27 "NotUsed12" 26 "NotUsed11" 25 "NotUsed10" 24 "NotUsed9" 23 "NotUsed8" 22 "NotUsed7" 21 "CustomMode" 20 "TrackMode" 19 "OnePedalDrive" 18 "EvLaterChargerMode" 17 "EvNowMode" 16 "DragMode" 15 "HighSpeedDesertMode_Baja" 14 "SportAdaptiveMode" 13 "NotAvailable_13" 12 "NotAvailable_12" 11 "NotAvailable_11" 10 "NotAvailable_10" 9 "RockCrawlMode" 8 "MudRutsMode" 7 "SandMode" 6 "EconomyMode" 5 "GrassGravelSnow" 4 "NotAvailable_04" 3 "TowHaulMode" 2 "NotAvailable_02" 1 "SportMode" 0 "NormalMode" ;
VAL_ 1087 RepaLcGrdInhbt_B_Stat 1 "Yes" 0 "No" ;
VAL_ 1087 ClimtCool_D_RqPt 3 "NotUsed_2" 2 "NotUsed_1" 1 "On" 0 "Off" ;
VAL_ 1087 StrtInGearMsgTxt_D_Rq 15 "Message15" 14 "Message14" 13 "Message13" 12 "Message12" 11 "Message11" 10 "Message10" 9 "Message9" 8 "Message8" 7 "Message7" 6 "Message6" 5 "Message5" 4 "Message4" 3 "Message3" 2 "Message2" 1 "Message1" 0 "NoMessage" ;
VAL_ 1087 IgnOffInhbt_B_Stat 1 "Yes" 0 "No" ;
VAL_ 1087 BtsiShifInhbt_B_RqPt 1 "Yes" 0 "No" ;
VAL_ 1087 FapLcInhbt_B_Rq 1 "Yes" 0 "No" ;
VAL_ 1087 FapLcStopHold_B_Rq 1 "Yes" 0 "No" ;
VAL_ 1087 FapLcPrchgBrk_B_Rq 1 "Yes" 0 "No" ;
VAL_ 1087 FapLcObstcl_B_Stat 1 "Yes" 0 "No" ;
VAL_ 1087 FapLcMaxGrdInhbt_B_Stat 1 "Yes" 0 "No" ;
VAL_ 1087 FapLcMaxGrdAbrt_B_Stat 1 "Yes" 0 "No" ;
VAL_ 1087 FapLcActv_B_Stat 1 "Yes" 0 "No" ;
VAL_ 1087 BattRgenLoDChrg_D_RqEng 3 "Disable" 2 "Retain" 1 "Closed" 0 "Open" ;
VAL_ 1087 BattRgenLoChrg_D_RqEng 3 "Disable" 2 "Retain" 1 "Closed" 0 "Open" ;
VAL_ 1087 AdasLcObtclAbrt_B_Stat 1 "Yes" 0 "No" ;
VAL_ 787 DrTgatePos_Pc_Actl 127 "Faulty" 126 "NoDataExists" ;
VAL_ 787 PwTgateInhbtMsgTxt_B_Rq 1 "DisplayMessage" 0 "NoMessage" ;
VAL_ 787 PwTgateStepMsgTxt_B_Rq 1 "DisplayMessage" 0 "NoMessage" ;
VAL_ 787 PwTgateMsgTxt_B_Rq 1 "DisplayMessage" 0 "NoMessage" ;
VAL_ 787 PwTgateLamp_B_Rq 1 "On" 0 "Off" ;
VAL_ 787 DrTgateChime2_D_Rq 7 "NotUsed3" 6 "NotUsed2" 5 "NotUsed1" 4 "Long_Repeated" 3 "Fast" 2 "Short" 1 "Long" 0 "Off" ;
VAL_ 787 DrTGate_D_Rq 3 "NotUsed" 2 "Closing" 1 "Opening" 0 "Not_Moving" ;
VAL_ 787 PwLftgtIntSw_B_Stat 1 "Pressed" 0 "Null" ;
VAL_ 787 Power_Liftgate_Mode_Stt 2 "Unused" 3 "Not_Supported" 1 "Enabled" 0 "Disabled" ;
VAL_ 819 WndwUpPsngrRear_D_Falt 3 "NotUsed" 2 "Fault" 1 "NoFault" 0 "Null" ;
VAL_ 819 WndwUpPsngrFront_D_Falt 3 "NotUsed" 2 "Fault" 1 "NoFault" 0 "Null" ;
VAL_ 819 DrPrsntPsngr_D_Stat 3 "Faulty" 2 "Present" 1 "NotPresent" 0 "NotDetermined" ;
VAL_ 819 DrPsngrMsgTxt_B_Rq 1 "Yes" 0 "No" ;
VAL_ 819 DrPrsntRearPsngr_D_Stat 3 "Faulty" 2 "Present" 1 "NotPresent" 0 "NotDetermined" ;
VAL_ 819 Memory_3_SwPsngr_Stat 1 "Pressed" 0 "Null" ;
VAL_ 819 Memory_2_SwPsngr_Stat 1 "Pressed" 0 "Null" ;
VAL_ 819 Memory_1_SwPsngr_Stat 1 "Pressed" 0 "Null" ;
VAL_ 819 BLISLEDStatPassSide 3 "Fault" 2 "Unused" 1 "On" 0 "Off" ;
VAL_ 819 WndwPsngrSide_D_Stat 3 "BothWindow_Operating" 2 "RearWindow_Operating" 1 "FrontWindow_Operating" 0 "NoWindows_Operating" ;
VAL_ 819 Pasngr_Lock_Sw_Stat 3 "Invalid" 2 "Unlock" 1 "Lock" 0 "Null" ;
VAL_ 819 ChildLckFdbckRp_B_Stat 1 "Locked" 0 "Unlock" ;
VAL_ 818 WndwUpDrvRear_D_Falt 3 "NotUsed" 2 "Fault" 1 "NoFault" 0 "Null" ;
VAL_ 818 WndwUpDrvFront_D_Falt 3 "NotUsed" 2 "Fault" 1 "NoFault" 0 "Null" ;
VAL_ 818 DrvSpotLight_B_Stat 1 "Active" 0 "Inactive" ;
VAL_ 818 DrPrsntDrv_D_Stat 3 "Faulty" 2 "Present" 1 "NotPresent" 0 "NotDetermined" ;
VAL_ 818 DrPrsntRearDrv_D_Stat 3 "Faulty" 2 "Present" 1 "NotPresent" 0 "NotDetermined" ;
VAL_ 818 DrDrvMsgTxt_B_Rq 1 "Yes" 0 "No" ;
VAL_ 818 BLISLEDStatDriverSide 3 "Fault" 2 "Unused" 1 "On" 0 "Off" ;
VAL_ 818 WndwDrvSide_D_Stat 3 "BothWindow_Operating" 2 "RearWindow_Operating" 1 "FrontWindow_Operating" 0 "NoWindows_Operating" ;
VAL_ 818 KeyCylSwDrvDr_D_Stat 3 "NotUsed" 2 "Unlock" 1 "Lock" 0 "Null" ;
VAL_ 818 Driver_Lock_Sw_Stat 3 "Invalid" 2 "Unlock" 1 "Lock" 0 "Null" ;
VAL_ 818 ChildLckPw_D_Rq 1 "Active" 0 "Null" ;
VAL_ 818 ChildLckFdbckRd_B_Stat 1 "Locked" 0 "Unlock" ;
VAL_ 818 RvrseMirrorChime_B_Rq 1 "Yes" 0 "No" ;
